VERSION "HNNBNNNYNNNNNNNNNNNNNNNNNNNNNNNNNNNNNNNNNN/4/%%%/4/'%**4NNN///"

NS_ :

BS_:

BU_: AEM BAP_Tester E_Sound FLA Gateway Gateway_PAG ISE MRR_HL MRR_HR NightVision RDK SAK SAK2 SCR STH_MLBevo TopView

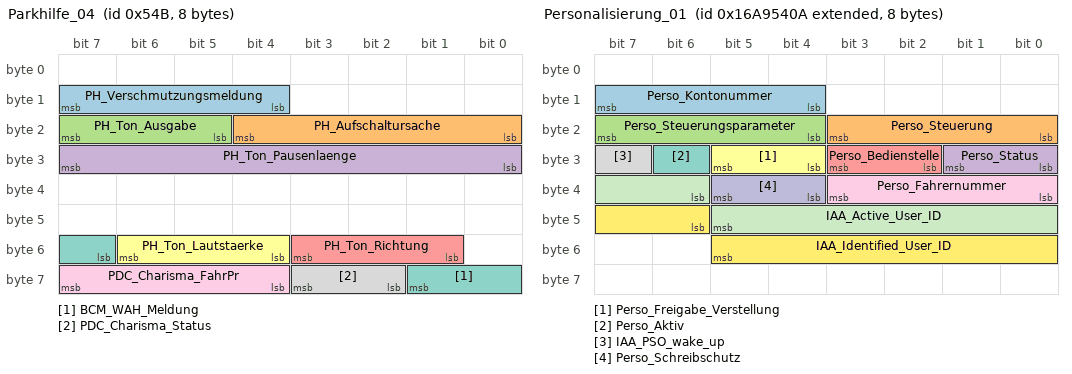
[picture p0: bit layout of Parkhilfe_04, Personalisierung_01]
BO_ 1355 Parkhilfe_04: 8 Gateway
 SG_ PH_Verschmutzungsmeldung : 12|4@1+ (1.0,0.0) [0.0|15] ""  Vector__XXX
 SG_ PH_Aufschaltursache : 16|5@1+ (1.0,0.0) [0.0|31] ""  TopView
 SG_ PH_Ton_Ausgabe : 21|3@1+ (1.0,0.0) [0.0|7] ""  Vector__XXX
 SG_ PH_Ton_Pausenlaenge : 24|8@1+ (1.0,0.0) [0.0|255] ""  Vector__XXX
 SG_ PH_Ton_Richtung : 49|3@1+ (1.0,0.0) [0.0|7] ""  Vector__XXX
 SG_ PH_Ton_Lautstaerke : 52|3@1+ (1.0,0.0) [0.0|7] ""  Vector__XXX
 SG_ BCM_WAH_Meldung : 55|3@1+ (1.0,0.0) [0.0|7] ""  Vector__XXX
 SG_ PDC_Charisma_Status : 58|2@1+ (1.0,0.0) [0.0|3] ""  Vector__XXX
 SG_ PDC_Charisma_FahrPr : 60|4@1+ (1.0,0.0) [0.0|15] ""  Vector__XXX

BO_ 2527679498 Personalisierung_01: 8 Gateway
 SG_ Perso_Kontonummer : 12|4@1+ (1.0,0.0) [0.0|15] ""  MRR_HR,NightVision
 SG_ Perso_Steuerung : 16|4@1+ (1.0,0.0) [0.0|15] ""  MRR_HR,NightVision
 SG_ Perso_Steuerungsparameter : 20|4@1+ (1.0,0.0) [0.0|15] ""  MRR_HR,NightVision
 SG_ Perso_Status : 24|2@1+ (1.0,0.0) [0.0|3] ""  MRR_HR,NightVision
 SG_ Perso_Bedienstelle : 26|2@1+ (1.0,0.0) [0.0|3] ""  Vector__XXX
 SG_ Perso_Freigabe_Verstellung : 28|2@1+ (1.0,0.0) [0.0|3] ""  Vector__XXX
 SG_ Perso_Aktiv : 30|1@1+ (1.0,0.0) [0.0|1] ""  Vector__XXX
 SG_ IAA_PSO_wake_up : 31|1@1+ (1.0,0.0) [0.0|1] ""  Vector__XXX
 SG_ Perso_Fahrernummer : 32|4@1+ (1.0,0.0) [0.0|15] ""  Vector__XXX
 SG_ Perso_Schreibschutz : 36|2@1+ (1.0,0.0) [0.0|3] ""  Vector__XXX
 SG_ IAA_Active_User_ID : 38|8@1+ (1,0) [0|255] "Unit_None"  Vector__XXX
 SG_ IAA_Identified_User_ID : 46|8@1+ (1,0) [0|255] "Unit_None"  Vector__XXX

BO_ 319 PreCrash_02: 8 Gateway
 SG_ PreCrash_02_CRC : 0|8@1+ (1,0) [0|255] ""  Vector__XXX
 SG_ PreCrash_02_BZ : 8|4@1+ (1,0) [0|15] ""  Vector__XXX
 SG_ PreCrash_Charisma_FahrPr : 12|4@1+ (1.0,0.0) [0.0|15] ""  Vector__XXX
 SG_ PreCrash_Charisma_Status : 16|2@1+ (1.0,0.0) [0.0|3] ""  Vector__XXX
 SG_ PreCrash_Schiebedach_schliessen : 18|1@1+ (1.0,0.0) [0.0|1] ""  Vector__XXX
 SG_ PreCrash_Fenster_schliessen : 19|1@1+ (1.0,0.0) [0.0|1] ""  Vector__XXX
 SG_ PreCrash_Blinken : 20|3@1+ (1.0,0.0) [0.0|7] ""  Vector__XXX
 SG_ SC_PreSense_FCWP : 23|1@1+ (1.0,0.0) [0.0|1] ""  NightVision
 SG_ PreCrash_Tueren_Verriegeln : 24|1@1+ (1.0,0.0) [0.0|1] ""  Vector__XXX
 SG_ PreCrash_Anforderung_AFR : 26|3@1+ (1.0,0.0) [0.0|7] ""  Vector__XXX
 SG_ SC_PreCrash_LED : 29|2@1+ (1.0,0.0) [0.0|3] ""  Vector__XXX
 SG_ PreCrash_FS_Pneumatik_ansteuern : 31|1@1+ (1.0,0.0) [0.0|1] ""  Vector__XXX
 SG_ PreCrash_BFS_Pneumatik_ansteuern : 32|1@1+ (1.0,0.0) [0.0|1] ""  Vector__XXX
 SG_ PreCrash_Fo_Pneumatik_ansteuern : 33|1@1+ (1.0,0.0) [0.0|1] ""  Vector__XXX
 SG_ PreCrash_FS_Sitzlehne_verfahren : 34|3@1+ (1.0,0.0) [0.0|7] ""  Vector__XXX
 SG_ PreCrash_BFS_Sitzlehne_verfahren : 37|3@1+ (1.0,0.0) [0.0|7] ""  Vector__XXX
 SG_ PreCrash_Fo_Sitzlehne_verfahren : 40|3@1+ (1.0,0.0) [0.0|7] ""  Vector__XXX
 SG_ PreCrash_FS_KSV_verfahren : 43|4@1+ (1.0,0.0) [0.0|15] ""  Vector__XXX
 SG_ PreCrash_BFS_KSV_verfahren : 47|4@1+ (1.0,0.0) [0.0|15] ""  Vector__XXX
 SG_ PreCrash_Fo_KSV_verfahren : 51|4@1+ (1.0,0.0) [0.0|15] ""  Vector__XXX
 SG_ SC_PreCrash_Warnung : 56|4@1+ (1.0,0.0) [0.0|15] ""  NightVision
 SG_ SC_PreCrash_Texte : 60|4@1+ (1.0,0.0) [0.0|15] ""  Vector__XXX

BO_ 1122 PSD_04: 8 Gateway
 SG_ PSD_Segment_ID : 0|6@1+ (1,0) [2|63] ""  FLA,NightVision
 SG_ PSD_Vorgaenger_Segment_ID : 6|6@1+ (1,0) [2|63] ""  FLA,NightVision
 SG_ PSD_Segmentlaenge : 12|7@1+ (2,0) [0|254] "Unit_Meter"  FLA,NightVision
 SG_ PSD_Strassenkategorie : 19|3@1+ (1.0,0.0) [0.0|7] ""  FLA,NightVision
 SG_ PSD_Endkruemmung : 22|8@1+ (1,0) [0|254] "Unit_None"  FLA,NightVision
 SG_ PSD_Endkruemmung_Vorz : 30|1@1+ (1.0,0.0) [0.0|1] ""  FLA,NightVision
 SG_ PSD_Idenditaets_ID : 31|6@1+ (1,0) [2|63] ""  FLA,NightVision
 SG_ PSD_ADAS_Qualitaet : 37|1@1+ (1.0,0.0) [0.0|1] ""  FLA,NightVision
 SG_ PSD_wahrscheinlichster_Pfad : 38|1@1+ (1.0,0.0) [0.0|1] ""  FLA,NightVision
 SG_ PSD_Geradester_Pfad : 39|1@1+ (1.0,0.0) [0.0|1] ""  FLA,NightVision
 SG_ PSD_Fahrspuren_Anzahl : 40|3@1+ (1.0,0.0) [0.0|7] ""  FLA,NightVision
 SG_ PSD_Bebauung : 43|1@1+ (1.0,0.0) [0.0|1] ""  FLA,NightVision
 SG_ PSD_Segment_Komplett : 44|1@1+ (1.0,0.0) [0.0|1] ""  FLA,NightVision
 SG_ PSD_Rampe : 45|2@1+ (1.0,0.0) [0.0|3] ""  FLA,NightVision
 SG_ PSD_Anfangskruemmung : 47|8@1+ (1,0) [0|254] ""  FLA,NightVision
 SG_ PSD_Anfangskruemmung_Vorz : 55|1@1+ (1.0,0.0) [0.0|1] ""  FLA,NightVision
 SG_ PSD_Abzweigerichtung : 56|1@1+ (1.0,0.0) [0.0|1] ""  FLA,NightVision
 SG_ PSD_Abzweigewinkel : 57|7@1+ (1.417323,0) [0.000000|180.000021] ""  FLA,NightVision

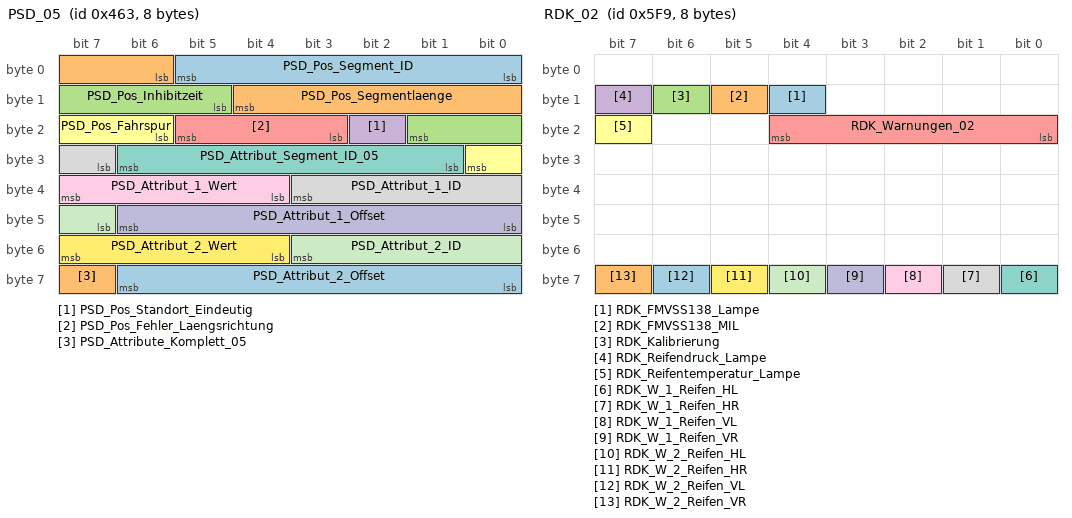
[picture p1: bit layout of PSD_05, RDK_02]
BO_ 1123 PSD_05: 8 Gateway
 SG_ PSD_Pos_Segment_ID : 0|6@1+ (1,0) [2|63] ""  FLA,NightVision
 SG_ PSD_Pos_Segmentlaenge : 6|7@1+ (2,0) [0|254] "Unit_Meter"  FLA,NightVision
 SG_ PSD_Pos_Inhibitzeit : 13|5@1+ (10,0) [0|310] "Unit_MilliSecon"  FLA,NightVision
 SG_ PSD_Pos_Standort_Eindeutig : 18|1@1+ (1.0,0.0) [0.0|1] ""  FLA,NightVision
 SG_ PSD_Pos_Fehler_Laengsrichtung : 19|3@1+ (1.0,0.0) [0.0|7] ""  FLA,NightVision
 SG_ PSD_Pos_Fahrspur : 22|3@1+ (1.0,0.0) [0.0|7] ""  FLA,NightVision
 SG_ PSD_Attribut_Segment_ID_05 : 25|6@1+ (1,0) [2|63] ""  FLA,NightVision
 SG_ PSD_Attribut_1_ID : 31|5@1+ (1,0) [1|31] ""  FLA,NightVision
 SG_ PSD_Attribut_1_Wert : 36|4@1+ (1.0,0.0) [0.0|15] ""  FLA,NightVision
 SG_ PSD_Attribut_1_Offset : 40|7@1+ (2,0) [0|254] "Unit_Meter"  FLA,NightVision
 SG_ PSD_Attribut_2_ID : 47|5@1+ (1,0) [1|31] ""  FLA,NightVision
 SG_ PSD_Attribut_2_Wert : 52|4@1+ (1.0,0.0) [0.0|15] ""  FLA,NightVision
 SG_ PSD_Attribut_2_Offset : 56|7@1+ (2,0) [0|254] "Unit_Meter"  FLA,NightVision
 SG_ PSD_Attribute_Komplett_05 : 63|1@1+ (1.0,0.0) [0.0|1] ""  FLA,NightVision

BO_ 1124 PSD_06: 8 Gateway
 SG_ PSD_06_Mux M  : 0|3@1+ (1.0,0.0) [0.0|7] ""  FLA,NightVision
 SG_ PSD_Sys_Segment_ID m0  : 3|6@1+ (1,0) [2|63] ""  FLA,NightVision
 SG_ PSD_Attribut_Segment_ID m1  : 3|6@1+ (1,0) [2|63] ""  FLA,NightVision
 SG_ PSD_Ges_Segment_ID m2  : 3|6@1+ (1,0) [2|63] ""  FLA,NightVision
 SG_ PSD_Baum_Laenge_VZ m3  : 3|1@1+ (1.0,0.0) [0.0|1] ""  FLA,NightVision
 SG_ PSD_Steigung_1_Segment_ID m4  : 3|6@1+ (1,0) [2|63] ""  FLA,NightVision
 SG_ PSD_Baum_Laenge m3  : 4|25@1+ (0.00001,0) [0.00000|180.00000] "Unit_DegreOfArc"  FLA,NightVision
 SG_ PSD_Sys_Laendercode m0  : 9|8@1+ (1.0,0.0) [0.0|255] ""  FLA,NightVision
 SG_ PSD_Attribut_3_ID m1  : 9|5@1+ (1,0) [1|31] ""  FLA,NightVision
 SG_ PSD_Ges_Offset m2  : 9|7@1+ (2,0) [0|254] "Unit_Meter"  FLA,NightVision
 SG_ PSD_Steigung_1_A_Steigung m4  : 9|7@1+ (0.12,0) [0.00|15.00] "Unit_PerCent"  FLA,NightVision
 SG_ PSD_Attribut_3_Offset m1  : 14|7@1+ (2,0) [0|254] "Unit_Meter"  FLA,NightVision
 SG_ PSD_Ges_Geschwindigkeit m2  : 16|5@1+ (1.0,0.0) [0.0|31] ""  FLA,NightVision
 SG_ PSD_Steigung_1_A_Vorz m4  : 16|1@1+ (1.0,0.0) [0.0|1] ""  FLA,NightVision
 SG_ PSD_Sys_Geschwindigkeit_Einheit m0  : 17|1@1+ (1.0,0.0) [0.0|1] ""  FLA,NightVision
 SG_ PSD_Steigung_1_A_Offset m4  : 17|7@1+ (2,0) [0|254] "Unit_Meter"  FLA,NightVision
 SG_ PSD_Sys_Verkehrsrichtung m0  : 18|1@1+ (1.0,0.0) [0.0|1] ""  FLA,NightVision
 SG_ PSD_Sys_Geometrieguete m0  : 19|2@1+ (1.0,0.0) [0.0|3] ""  FLA,NightVision
 SG_ PSD_Sys_Mapmatchingguete m0  : 21|2@1+ (1.0,0.0) [0.0|3] ""  FLA,NightVision
 SG_ PSD_Attribut_3_Wert m1  : 21|4@1+ (1.0,0.0) [0.0|15] ""  FLA,NightVision
 SG_ PSD_Ges_Typ m2  : 21|2@1+ (1.0,0.0) [0.0|3] ""  FLA,NightVision
 SG_ PSD_Sys_Alter_Karte m0  : 23|3@1+ (1.0,0.0) [0.0|7] ""  FLA,NightVision
 SG_ PSD_Ges_Spur_Geschw_Begrenzung m2  : 23|6@1+ (1.0,0.0) [0.0|63] ""  FLA,NightVision
 SG_ PSD_Steigung_1_B_Steigung m4  : 24|7@1+ (0.12,0) [0.00|15.00] "Unit_PerCent"  FLA,NightVision
 SG_ PSD_Attribut_4_ID m1  : 25|5@1+ (1,0) [1|31] ""  FLA,NightVision
 SG_ PSD_Sys_Zielfuehrung m0  : 26|1@1+ (1.0,0.0) [0.0|1] ""  FLA,NightVision
 SG_ PSD_Sys_US_State m0  : 27|6@1+ (1.0,0.0) [0.0|63] ""  FLA,NightVision
 SG_ PSD_Ges_Geschwindigkeit_Gespann m2  : 29|2@1+ (1.0,0.0) [0.0|3] ""  FLA,NightVision
 SG_ PSD_Baum_Breite_VZ m3  : 29|1@1+ (1.0,0.0) [0.0|1] ""  FLA,NightVision
 SG_ PSD_Attribut_4_Wert m1  : 30|4@1+ (1,0) [0|15] ""  FLA,NightVision
 SG_ PSD_Baum_Breite m3  : 30|24@1+ (0.00001,0) [0.00000|90.00000] "Unit_DegreOfArc"  FLA,NightVision
 SG_ PSD_Ges_Geschwindigkeit_Witter m2  : 31|2@1+ (1.0,0.0) [0.0|3] ""  FLA,NightVision
 SG_ PSD_Steigung_1_B_Vorz m4  : 31|1@1+ (1.0,0.0) [0.0|1] ""  FLA,NightVision
 SG_ PSD_Steigung_1_B_Offset m4  : 32|7@1+ (2,0) [0|254] "Unit_Meter"  FLA,NightVision
 SG_ PSD_Sys_Quali_Geometrien m0  : 33|3@1+ (1,0) [0|7] "Unit_None"  FLA,NightVision
 SG_ PSD_Ges_Geschwindigkeit_Tag_Anf m2  : 33|3@1+ (1.0,0.0) [0.0|7] ""  FLA,NightVision
 SG_ PSD_Attribut_4_Offset m1  : 34|7@1+ (2,0) [0|254] "Unit_Meter"  FLA,NightVision
 SG_ PSD_Sys_Quali_Ortsinfo m0  : 36|2@1+ (1,0) [0|3] "Unit_None"  FLA,NightVision
 SG_ PSD_Ges_Geschwindigkeit_Tag_Ende m2  : 36|3@1+ (1.0,0.0) [0.0|7] ""  FLA,NightVision
 SG_ PSD_Sys_Quali_verfuegbar m0  : 38|1@1+ (1.0,0.0) [0.0|1] ""  FLA,NightVision
 SG_ PSD_Sys_Zielfuehrung_geaendert m0  : 39|1@1+ (1.0,0.0) [0.0|1] ""  FLA,NightVision
 SG_ PSD_Ges_Geschwindigkeit_Std_Anf m2  : 39|5@1+ (1,0) [0|24] "Unit_Hours"  FLA,NightVision
 SG_ PSD_Steigung_1_Attribute_kompl m4  : 39|1@1+ (1.0,0.0) [0.0|1] ""  FLA,NightVision
 SG_ PSD_Sys_Geometrieguete_erweitert m0  : 40|8@1+ (1.0,0.0) [0.0|255] ""  FLA,NightVision
 SG_ PSD_Steigung_2_Segment_ID m4  : 40|6@1+ (1,0) [2|63] ""  FLA,NightVision
 SG_ PSD_Attribut_5_ID m1  : 41|5@1+ (1,0) [1|31] ""  FLA,NightVision
 SG_ PSD_Ges_Geschwindigkeit_Std_Ende m2  : 44|5@1+ (1,0) [0|24] "Unit_Hours"  FLA,NightVision
 SG_ PSD_Attribut_5_Offset m1  : 46|7@1+ (2,0) [0|254] "Unit_Meter"  FLA,NightVision
 SG_ PSD_Steigung_2_Steigung m4  : 46|7@1+ (0.12,0) [0.00|15.00] "Unit_PerCent"  FLA,NightVision
 SG_ PSD_Sys_Quali_sonstige_Attribute m0  : 48|3@1+ (1,0) [0|7] "Unit_None"  FLA,NightVision
 SG_ PSD_Ges_Ueberholverbot m2  : 49|2@1+ (1.0,0.0) [0.0|3] ""  FLA,NightVision
 SG_ PSD_Sys_Quali_Steigungen m0  : 51|3@1+ (1,0) [0|7] ""  FLA,NightVision
 SG_ PSD_Ges_Wechselverkehrszeichen m2  : 51|3@1+ (1.0,0.0) [0.0|7] ""  FLA,NightVision
 SG_ PSD_Attribut_5_Wert m1  : 53|4@1+ (1,0) [0|15] ""  FLA,NightVision
 SG_ PSD_Steigung_2_Vorz m4  : 53|1@1+ (1.0,0.0) [0.0|1] ""  FLA,NightVision
 SG_ PSD_Sys_Quali_Strassenkennz m0  : 54|3@1+ (1,0) [0|7] "Unit_None"  FLA,NightVision
 SG_ PSD_Wechselverkehrszeichen_Typ m2  : 54|2@1+ (1.0,0.0) [0.0|3] ""  FLA,NightVision
 SG_ PSD_Baum_Ausrichtung m3  : 54|10@1+ (0.3515625,0) [0E-7|359.6484375] "Unit_DegreOfArc"  FLA,NightVision
 SG_ PSD_Steigung_2_Offset m4  : 54|7@1+ (2,0) [0|254] "Unit_Meter"  FLA,NightVision
 SG_ PSD_Ges_Gesetzlich_Kategorie m2  : 56|3@1+ (1.0,0.0) [0.0|7] ""  FLA,NightVision
 SG_ PSD_Sys_Quali_Tempolimits m0  : 57|3@1+ (1,0) [0|7] "Unit_None"  FLA,NightVision
 SG_ PSD_Attribute_Komplett_06 m1  : 57|1@1+ (1.0,0.0) [0.0|1] ""  FLA,NightVision
 SG_ PSD_Ges_Gesetzlich_Zusatz m2  : 59|2@1+ (1.0,0.0) [0.0|3] ""  FLA,NightVision
 SG_ PSD_Sys_Quali_Vorfahrtsregelung m0  : 60|3@1+ (1,0) [0|7] "Unit_None"  FLA,NightVision
 SG_ PSD_Ges_Verkehrszeichen_Quelle m2  : 61|2@1+ (1.0,0.0) [0.0|3] ""  FLA,NightVision
 SG_ PSD_Steigung_2_Attribute_kompl m4  : 61|1@1+ (1.0,0.0) [0.0|1] ""  FLA,NightVision
 SG_ PSD_Ges_Attribute_Komplett m2  : 63|1@1+ (1.0,0.0) [0.0|1] ""  FLA,NightVision

BO_ 1529 RDK_02: 8 RDK
 SG_ RDK_FMVSS138_Lampe : 12|1@1+ (1.0,0.0) [0.0|1] ""  Gateway,Gateway_PAG
 SG_ RDK_FMVSS138_MIL : 13|1@1+ (1.0,0.0) [0.0|1] ""  Gateway,Gateway_PAG
 SG_ RDK_Kalibrierung : 14|1@1+ (1.0,0.0) [0.0|1] ""  Gateway,Gateway_PAG
 SG_ RDK_Reifendruck_Lampe : 15|1@1+ (1.0,0.0) [0.0|1] ""  Gateway,Gateway_PAG
 SG_ RDK_Warnungen_02 : 16|5@1+ (1.0,0.0) [0.0|31] ""  Gateway,Gateway_PAG
 SG_ RDK_Reifentemperatur_Lampe : 23|1@1+ (1.0,0.0) [0.0|1] ""  Gateway,Gateway_PAG
 SG_ RDK_W_1_Reifen_HL : 56|1@1+ (1.0,0.0) [0.0|1] ""  Gateway,Gateway_PAG
 SG_ RDK_W_1_Reifen_HR : 57|1@1+ (1.0,0.0) [0.0|1] ""  Gateway,Gateway_PAG
 SG_ RDK_W_1_Reifen_VL : 58|1@1+ (1.0,0.0) [0.0|1] ""  Gateway,Gateway_PAG
 SG_ RDK_W_1_Reifen_VR : 59|1@1+ (1.0,0.0) [0.0|1] ""  Gateway,Gateway_PAG
 SG_ RDK_W_2_Reifen_HL : 60|1@1+ (1.0,0.0) [0.0|1] ""  Gateway,Gateway_PAG
 SG_ RDK_W_2_Reifen_HR : 61|1@1+ (1.0,0.0) [0.0|1] ""  Gateway,Gateway_PAG
 SG_ RDK_W_2_Reifen_VL : 62|1@1+ (1.0,0.0) [0.0|1] ""  Gateway,Gateway_PAG
 SG_ RDK_W_2_Reifen_VR : 63|1@1+ (1.0,0.0) [0.0|1] ""  Gateway,Gateway_PAG

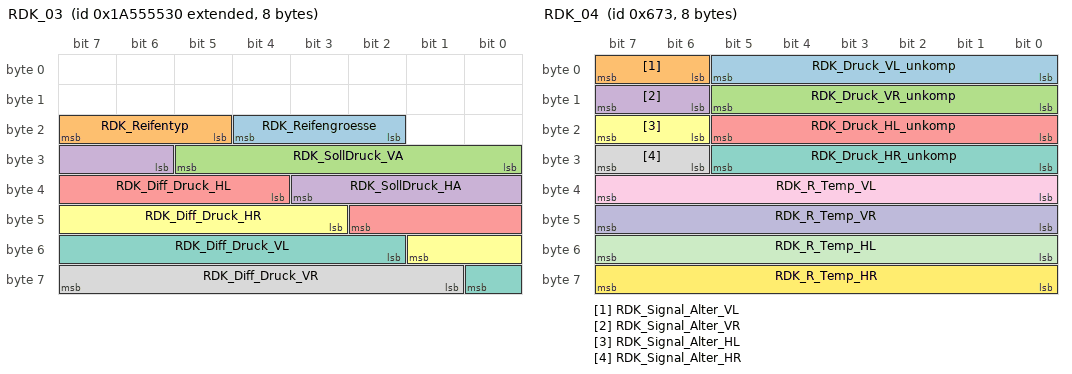
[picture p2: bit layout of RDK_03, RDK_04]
BO_ 2589283632 RDK_03: 8 RDK
 SG_ RDK_Reifengroesse : 18|3@1+ (1.0,0.0) [0.0|7] ""  Gateway,Gateway_PAG
 SG_ RDK_Reifentyp : 21|3@1+ (1.0,0.0) [0.0|7] ""  Gateway,Gateway_PAG
 SG_ RDK_SollDruck_VA : 24|6@1+ (0.1,0) [0.0|6.2] "Unit_Bar"  Gateway,Gateway_PAG
 SG_ RDK_SollDruck_HA : 30|6@1+ (0.1,0) [0.0|6.2] "Unit_Bar"  Gateway,Gateway_PAG
 SG_ RDK_Diff_Druck_HL : 36|7@1+ (0.1,-6.3) [-6.3|6.3] "Unit_Bar"  Gateway,Gateway_PAG
 SG_ RDK_Diff_Druck_HR : 43|7@1+ (0.1,-6.3) [-6.3|6.3] "Unit_Bar"  Gateway,Gateway_PAG
 SG_ RDK_Diff_Druck_VL : 50|7@1+ (0.1,-6.3) [-6.3|6.3] "Unit_Bar"  Gateway,Gateway_PAG
 SG_ RDK_Diff_Druck_VR : 57|7@1+ (0.1,-6.3) [-6.3|6.3] "Unit_Bar"  Gateway,Gateway_PAG

BO_ 1651 RDK_04: 8 RDK
 SG_ RDK_Druck_VL_unkomp : 0|6@1+ (0.1,0) [0.0|6.2] "Unit_Bar"  Gateway,Gateway_PAG
 SG_ RDK_Signal_Alter_VL : 6|2@1+ (1.0,0.0) [0.0|3] ""  Gateway,Gateway_PAG
 SG_ RDK_Druck_VR_unkomp : 8|6@1+ (0.1,0) [0.0|6.2] "Unit_Bar"  Gateway,Gateway_PAG
 SG_ RDK_Signal_Alter_VR : 14|2@1+ (1.0,0.0) [0.0|3] ""  Gateway,Gateway_PAG
 SG_ RDK_Druck_HL_unkomp : 16|6@1+ (0.1,0) [0.0|6.2] "Unit_Bar"  Gateway,Gateway_PAG
 SG_ RDK_Signal_Alter_HL : 22|2@1+ (1.0,0.0) [0.0|3] ""  Gateway,Gateway_PAG
 SG_ RDK_Druck_HR_unkomp : 24|6@1+ (0.1,0) [0.0|6.2] "Unit_Bar"  Gateway,Gateway_PAG
 SG_ RDK_Signal_Alter_HR : 30|2@1+ (1.0,0.0) [0.0|3] ""  Gateway,Gateway_PAG
 SG_ RDK_R_Temp_VL : 32|8@1+ (1,-60) [-60|193] "Unit_DegreCelsi"  Gateway,Gateway_PAG
 SG_ RDK_R_Temp_VR : 40|8@1+ (1,-60) [-60|193] "Unit_DegreCelsi"  Gateway,Gateway_PAG
 SG_ RDK_R_Temp_HL : 48|8@1+ (1,-60) [-60|193] "Unit_DegreCelsi"  Gateway,Gateway_PAG
 SG_ RDK_R_Temp_HR : 56|8@1+ (1,-60) [-60|193] "Unit_DegreCelsi"  Gateway,Gateway_PAG

BO_ 1711 Rear_View_01: 8 TopView
 SG_ RV_Video_on : 0|1@1+ (1.0,0.0) [0.0|1] ""  Gateway,Gateway_PAG
 SG_ RV_Dark_Screen : 1|1@1+ (1.0,0.0) [0.0|1] ""  Gateway,Gateway_PAG
 SG_ RV_HMI_Mode : 2|2@1+ (1.0,0.0) [0.0|3] ""  Gateway,Gateway_PAG
 SG_ RV_GL_side : 4|2@1+ (1.0,0.0) [0.0|3] ""  Gateway,Gateway_PAG
 SG_ RV_System_aktiv : 6|1@1+ (1.0,0.0) [0.0|1] ""  Gateway,Gateway_PAG
 SG_ RV_Reinigung_Anf : 7|1@1+ (1.0,0.0) [0.0|1] ""  Gateway,Gateway_PAG
 SG_ RV_Settings_enabled : 8|1@1+ (1.0,0.0) [0.0|1] ""  Gateway,Gateway_PAG
 SG_ RV_Menu_Item : 9|2@1+ (1.0,0.0) [0.0|3] ""  Gateway,Gateway_PAG
 SG_ SV_Video_on : 11|1@1+ (1.0,0.0) [0.0|1] ""  Gateway,Gateway_PAG
 SG_ RV_Calib_Fehler : 12|1@1+ (1.0,0.0) [0.0|1] ""  Gateway,Gateway_PAG
 SG_ RV_GL_Trailer_connect : 13|1@1+ (1.0,0.0) [0.0|1] ""  Gateway,Gateway_PAG
 SG_ RV_GL_Trunk_open : 14|1@1+ (1.0,0.0) [0.0|1] ""  Gateway,Gateway_PAG
 SG_ RV_GL_LWS_Fehler : 15|1@1+ (1.0,0.0) [0.0|1] ""  Gateway,Gateway_PAG
 SG_ RV_Helligkeit : 16|7@1+ (1,0) [0|100] "Unit_PerCent"  Gateway,Gateway_PAG
 SG_ ZFAS_Umfeldbeleuchtung_Anf : 23|1@1+ (1.0,0.0) [0.0|1] ""  Gateway,Gateway_PAG
 SG_ RV_Kontrast : 24|7@1+ (1,0) [0|100] "Unit_PerCent"  Gateway,Gateway_PAG
 SG_ RV_Farbe : 32|7@1+ (1,0) [0|100] "Unit_PerCent"  Gateway,Gateway_PAG

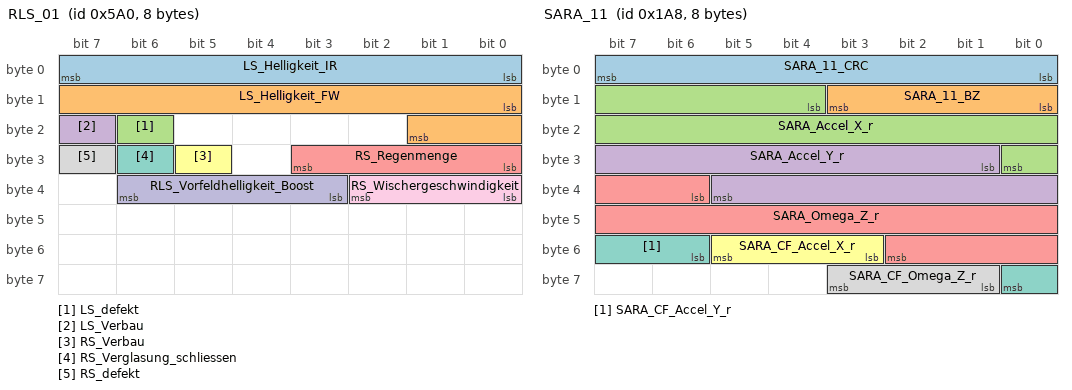
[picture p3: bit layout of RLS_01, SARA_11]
BO_ 1440 RLS_01: 8 Gateway
 SG_ LS_Helligkeit_IR : 0|8@1+ (400,0) [0|101200] "Unit_Lux"  MRR_HL,MRR_HR,NightVision
 SG_ LS_Helligkeit_FW : 8|10@1+ (6,0) [0|6126] "Unit_Lux"  MRR_HL,MRR_HR,NightVision
 SG_ LS_defekt : 22|1@1+ (1.0,0.0) [0.0|1] ""  MRR_HL,MRR_HR,NightVision
 SG_ LS_Verbau : 23|1@1+ (1.0,0.0) [0.0|1] ""  MRR_HL,MRR_HR,NightVision
 SG_ RS_Regenmenge : 24|4@1+ (10,0) [0|100] "Unit_PerCent"  Vector__XXX
 SG_ RS_Verbau : 29|1@1+ (1.0,0.0) [0.0|1] ""  NightVision
 SG_ RS_Verglasung_schliessen : 30|1@1+ (1.0,0.0) [0.0|1] ""  Vector__XXX
 SG_ RS_defekt : 31|1@1+ (1.0,0.0) [0.0|1] ""  NightVision
 SG_ RS_Wischergeschwindigkeit : 32|3@1+ (1.0,0.0) [0.0|7] ""  NightVision
 SG_ RLS_Vorfeldhelligkeit_Boost : 35|4@1+ (1.0,0.0) [0.0|15] ""  Vector__XXX

BO_ 1528 SAK_01: 8 ISE
 SG_ SAK_Charisma_FahrPr : 16|4@1+ (1.0,0.0) [0.0|15] ""  Gateway,Gateway_PAG
 SG_ SAK_Charisma_Status : 20|2@1+ (1.0,0.0) [0.0|3] ""  Gateway,Gateway_PAG

BO_ 424 SARA_11: 8 Gateway
 SG_ SARA_11_CRC : 0|8@1+ (1,0) [0|255] ""  Vector__XXX
 SG_ SARA_11_BZ : 8|4@1+ (1,0) [0|15] ""  Vector__XXX
 SG_ SARA_Accel_X_r : 12|13@1+ (0.16,-655.36) [-655.20|655.04] "Unit_MeterPerSeconSquar"  E_Sound,ISE,TopView
 SG_ SARA_Accel_Y_r : 25|13@1+ (0.16,-655.36) [-655.20|655.04] "Unit_MeterPerSeconSquar"  TopView
 SG_ SARA_Omega_Z_r : 38|13@1+ (0.08,-327.68) [-327.60|327.52] "Unit_DegreOfArcPerSecon"  FLA,NightVision,TopView
 SG_ SARA_CF_Accel_X_r : 51|3@1+ (1.0,0.0) [0.0|7] ""  TopView
 SG_ SARA_CF_Accel_Y_r : 54|3@1+ (1.0,0.0) [0.0|7] ""  TopView
 SG_ SARA_CF_Omega_Z_r : 57|3@1+ (1.0,0.0) [0.0|7] ""  FLA,NightVision,TopView

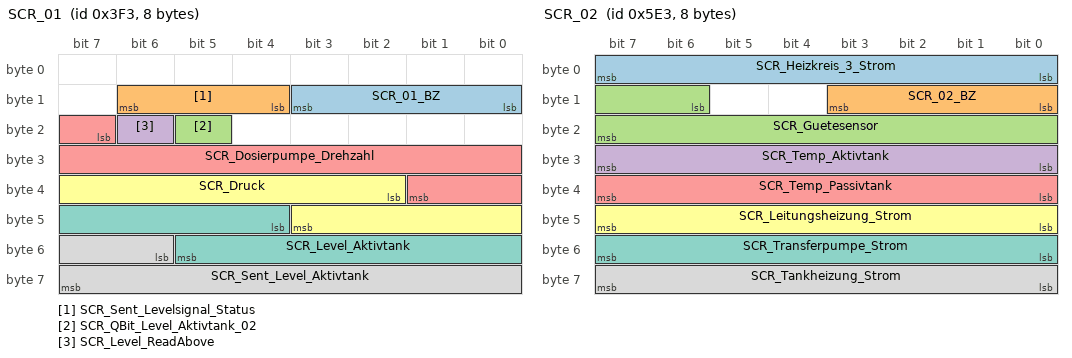
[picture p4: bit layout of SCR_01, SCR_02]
BO_ 1011 SCR_01: 8 SCR
 SG_ SCR_01_BZ : 8|4@1+ (1,0) [0|15] ""  Gateway,Gateway_PAG
 SG_ SCR_Sent_Levelsignal_Status : 12|3@1+ (1.0,0.0) [0.0|7] ""  Gateway,Gateway_PAG
 SG_ SCR_QBit_Level_Aktivtank_02 : 21|1@1+ (1.0,0.0) [0.0|1] ""  Gateway,Gateway_PAG
 SG_ SCR_Level_ReadAbove : 22|1@1+ (1.0,0.0) [0.0|1] ""  Gateway,Gateway_PAG
 SG_ SCR_Dosierpumpe_Drehzahl : 23|11@1+ (4,-4080) [-4080|4100] "Unit_MinutInver"  Gateway,Gateway_PAG
 SG_ SCR_Druck : 34|10@1+ (5,0) [0|5000] "Unit_MilliVolt"  Gateway,Gateway_PAG
 SG_ SCR_Level_Aktivtank : 44|10@1+ (5,0) [0|5000] "Unit_MilliVolt"  Gateway,Gateway_PAG
 SG_ SCR_Sent_Level_Aktivtank : 54|10@1+ (1,-20) [-20|1000] "Unit_MilliMeter"  Gateway,Gateway_PAG

BO_ 1507 SCR_02: 8 SCR
 SG_ SCR_Heizkreis_3_Strom : 0|8@1+ (0.1,0) [0.0|14.0] "Unit_Amper"  Gateway,Gateway_PAG
 SG_ SCR_02_BZ : 8|4@1+ (1,0) [0|15] ""  Gateway,Gateway_PAG
 SG_ SCR_Guetesensor : 14|10@1+ (5,0) [0|5000] "Unit_MilliVolt"  Gateway,Gateway_PAG
 SG_ SCR_Temp_Aktivtank : 24|8@1+ (20,0) [0|5000] "Unit_MilliVolt"  Gateway,Gateway_PAG
 SG_ SCR_Temp_Passivtank : 32|8@1+ (20,0) [0|5000] "Unit_MilliVolt"  Gateway,Gateway_PAG
 SG_ SCR_Leitungsheizung_Strom : 40|8@1+ (0.1,0) [0.0|14.0] "Unit_Amper"  Gateway,Gateway_PAG
 SG_ SCR_Transferpumpe_Strom : 48|8@1+ (0.1,0) [0.0|14.0] "Unit_Amper"  Gateway,Gateway_PAG
 SG_ SCR_Tankheizung_Strom : 56|8@1+ (0.1,0) [0.0|14.0] "Unit_Amper"  Gateway,Gateway_PAG

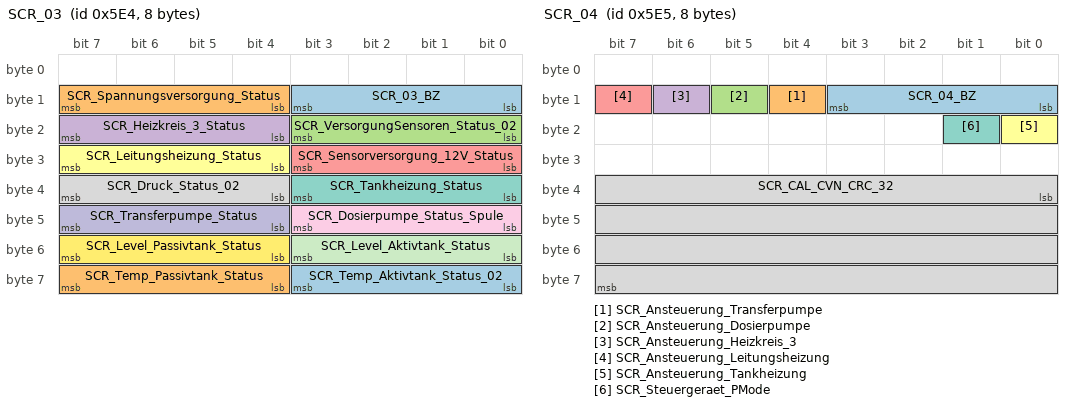
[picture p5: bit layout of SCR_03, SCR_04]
BO_ 1508 SCR_03: 8 SCR
 SG_ SCR_03_BZ : 8|4@1+ (1,0) [0|15] ""  Gateway,Gateway_PAG
 SG_ SCR_Spannungsversorgung_Status : 12|4@1+ (1.0,0.0) [0.0|15] ""  Gateway,Gateway_PAG
 SG_ SCR_VersorgungSensoren_Status_02 : 16|4@1+ (1.0,0.0) [0.0|15] ""  Gateway,Gateway_PAG
 SG_ SCR_Heizkreis_3_Status : 20|4@1+ (1.0,0.0) [0.0|15] ""  Gateway,Gateway_PAG
 SG_ SCR_Sensorversorgung_12V_Status : 24|4@1+ (1.0,0.0) [0.0|15] ""  Gateway,Gateway_PAG
 SG_ SCR_Leitungsheizung_Status : 28|4@1+ (1.0,0.0) [0.0|15] ""  Gateway,Gateway_PAG
 SG_ SCR_Tankheizung_Status : 32|4@1+ (1.0,0.0) [0.0|15] ""  Gateway,Gateway_PAG
 SG_ SCR_Druck_Status_02 : 36|4@1+ (1.0,0.0) [0.0|15] ""  Gateway,Gateway_PAG
 SG_ SCR_Dosierpumpe_Status_Spule : 40|4@1+ (1.0,0.0) [0.0|15] ""  Gateway,Gateway_PAG
 SG_ SCR_Transferpumpe_Status : 44|4@1+ (1.0,0.0) [0.0|15] ""  Gateway,Gateway_PAG
 SG_ SCR_Level_Aktivtank_Status : 48|4@1+ (1.0,0.0) [0.0|15] ""  Gateway,Gateway_PAG
 SG_ SCR_Level_Passivtank_Status : 52|4@1+ (1.0,0.0) [0.0|15] ""  Gateway,Gateway_PAG
 SG_ SCR_Temp_Aktivtank_Status_02 : 56|4@1+ (1.0,0.0) [0.0|15] ""  Gateway,Gateway_PAG
 SG_ SCR_Temp_Passivtank_Status : 60|4@1+ (1.0,0.0) [0.0|15] ""  Gateway,Gateway_PAG

BO_ 1509 SCR_04: 8 SCR
 SG_ SCR_04_BZ : 8|4@1+ (1,0) [0|15] ""  Gateway,Gateway_PAG
 SG_ SCR_Ansteuerung_Transferpumpe : 12|1@1+ (1.0,0.0) [0.0|1] ""  Gateway,Gateway_PAG
 SG_ SCR_Ansteuerung_Dosierpumpe : 13|1@1+ (1.0,0.0) [0.0|1] ""  Gateway,Gateway_PAG
 SG_ SCR_Ansteuerung_Heizkreis_3 : 14|1@1+ (1.0,0.0) [0.0|1] ""  Gateway,Gateway_PAG
 SG_ SCR_Ansteuerung_Leitungsheizung : 15|1@1+ (1.0,0.0) [0.0|1] ""  Gateway,Gateway_PAG
 SG_ SCR_Ansteuerung_Tankheizung : 16|1@1+ (1.0,0.0) [0.0|1] ""  Gateway,Gateway_PAG
 SG_ SCR_Steuergeraet_PMode : 17|1@1+ (1.0,0.0) [0.0|1] ""  Gateway,Gateway_PAG
 SG_ SCR_CAL_CVN_CRC_32 : 32|32@1+ (1.0,0.0) [0.0|4294967295] ""  Gateway,Gateway_PAG

BO_ 1526 SCR_05: 8 SCR
 SG_ SCR_05_BZ : 8|4@1+ (1,0) [0|15] ""  Gateway,Gateway_PAG
 SG_ SCR_Level_Aktivtank_OOR4Quality : 12|1@1+ (1.0,0.0) [0.0|1] ""  Gateway,Gateway_PAG
 SG_ SCR_Level_Aktivtank_OOR_minus : 13|1@1+ (1.0,0.0) [0.0|1] ""  Gateway,Gateway_PAG
 SG_ SCR_Sent_1_Signalstatus : 14|2@1+ (1.0,0.0) [0.0|3] ""  Gateway,Gateway_PAG
 SG_ SCR_Sent_1_elektrischer_Status : 16|4@1+ (1.0,0.0) [0.0|15] ""  Gateway,Gateway_PAG
 SG_ SCR_Sent_Levelsensor : 20|3@1+ (1.0,0.0) [0.0|7] ""  Gateway,Gateway_PAG
 SG_ SCR_Sent_Qualitaetssensor : 23|3@1+ (1.0,0.0) [0.0|7] ""  Gateway,Gateway_PAG
 SG_ SCR_Sent_Temperatursensor : 26|3@1+ (1.0,0.0) [0.0|7] ""  Gateway,Gateway_PAG
 SG_ SCR_DEF_Qualitaet_Medium : 29|1@1+ (1.0,0.0) [0.0|1] ""  Gateway,Gateway_PAG
 SG_ SCR_QBit_Qualitaet : 30|1@1+ (1.0,0.0) [0.0|1] ""  Gateway,Gateway_PAG
 SG_ SCR_Sent_2_Signalstatus : 31|2@1+ (1.0,0.0) [0.0|3] ""  Gateway,Gateway_PAG
 SG_ SCR_Temp_DEF2_Sensor_Status : 33|3@1+ (1.0,0.0) [0.0|7] ""  Gateway,Gateway_PAG
 SG_ SCR_Sent_2_elektrischer_Status : 36|4@1+ (1.0,0.0) [0.0|15] ""  Gateway,Gateway_PAG
 SG_ SCR_HAL_Sensorik_Status : 40|4@1+ (1.0,0.0) [0.0|15] ""  Gateway,Gateway_PAG
 SG_ SCR_Steuergeraet_Heizung_Status : 48|2@1+ (1.0,0.0) [0.0|3] ""  Gateway,Gateway_PAG
 SG_ SCR_Steuergeraet_Pumpe_Status : 50|2@1+ (1.0,0.0) [0.0|3] ""  Gateway,Gateway_PAG
 SG_ SCR_Steuergeraet_Relais_Status : 52|2@1+ (1.0,0.0) [0.0|3] ""  Gateway,Gateway_PAG
 SG_ SCR_Steuergeraet_Bus_Status : 56|2@1+ (1.0,0.0) [0.0|3] ""  Gateway,Gateway_PAG
 SG_ SCR_ECU_Datensatz_Status : 60|2@1+ (1.0,0.0) [0.0|3] ""  Gateway,Gateway_PAG
 SG_ SCR_Steuergeraet_Defekt_Status : 62|2@1+ (1.0,0.0) [0.0|3] ""  Gateway,Gateway_PAG

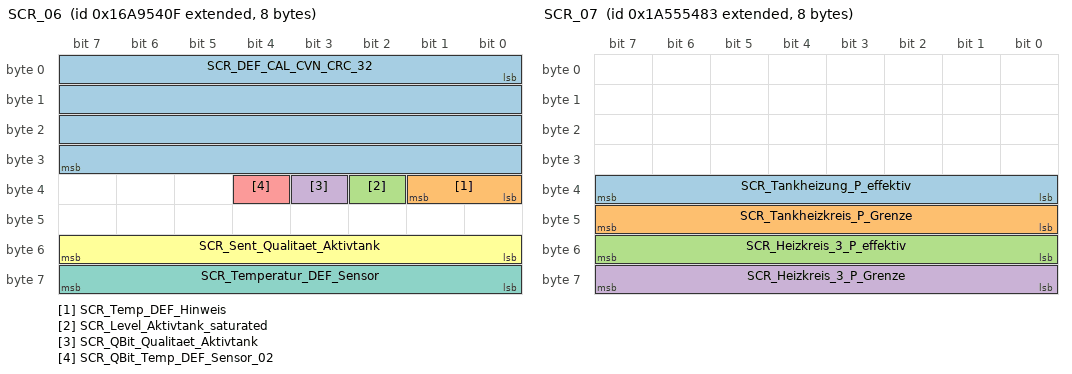
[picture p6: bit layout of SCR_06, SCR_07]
BO_ 2527679503 SCR_06: 8 SCR
 SG_ SCR_DEF_CAL_CVN_CRC_32 : 0|32@1+ (1.0,0.0) [0.0|4294967295] ""  Gateway,Gateway_PAG
 SG_ SCR_Temp_DEF_Hinweis : 32|2@1+ (1.0,0.0) [0.0|3] ""  Gateway,Gateway_PAG
 SG_ SCR_Level_Aktivtank_saturated : 34|1@1+ (1.0,0.0) [0.0|1] ""  Gateway,Gateway_PAG
 SG_ SCR_QBit_Qualitaet_Aktivtank : 35|1@1+ (1.0,0.0) [0.0|1] ""  Gateway,Gateway_PAG
 SG_ SCR_QBit_Temp_DEF_Sensor_02 : 36|1@1+ (1.0,0.0) [0.0|1] ""  Gateway,Gateway_PAG
 SG_ SCR_Sent_Qualitaet_Aktivtank : 48|8@1+ (0.5,-20) [-20.0|100.0] "Unit_PerCent"  Gateway,Gateway_PAG
 SG_ SCR_Temperatur_DEF_Sensor : 56|8@1+ (0.5,-45) [-45.0|80.0] "Unit_DegreCelsi"  Gateway,Gateway_PAG

BO_ 2589283459 SCR_07: 8 SCR
 SG_ SCR_Tankheizung_P_effektiv : 32|8@1+ (1,0) [0|250] "Unit_Watt"  Gateway,Gateway_PAG
 SG_ SCR_Tankheizkreis_P_Grenze : 40|8@1+ (1,0) [0|250] "Unit_Watt"  Gateway,Gateway_PAG
 SG_ SCR_Heizkreis_3_P_effektiv : 48|8@1+ (1,0) [0|250] "Unit_Watt"  Gateway,Gateway_PAG
 SG_ SCR_Heizkreis_3_P_Grenze : 56|8@1+ (1,0) [0|250] "Unit_Watt"  Gateway,Gateway_PAG

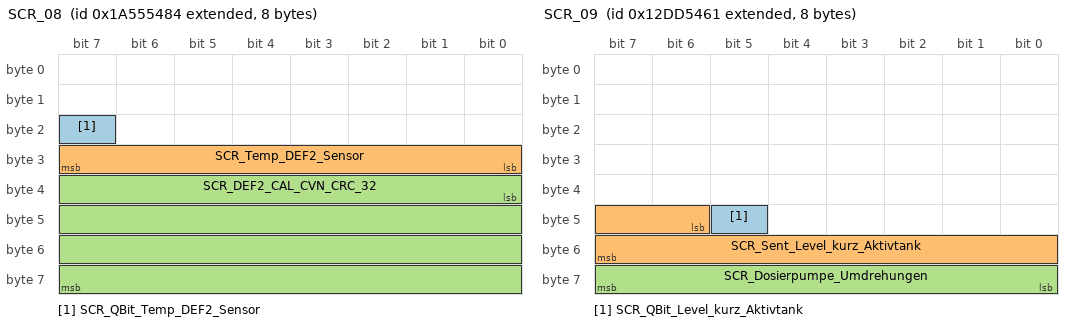
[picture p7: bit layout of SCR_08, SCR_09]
BO_ 2589283460 SCR_08: 8 SCR
 SG_ SCR_QBit_Temp_DEF2_Sensor : 23|1@1+ (1.0,0.0) [0.0|1] ""  Gateway,Gateway_PAG
 SG_ SCR_Temp_DEF2_Sensor : 24|8@1+ (0.5,-45) [-45.0|80.0] "Unit_DegreCelsi"  Gateway,Gateway_PAG
 SG_ SCR_DEF2_CAL_CVN_CRC_32 : 32|32@1+ (1.0,0.0) [0.0|4294967295] ""  Gateway,Gateway_PAG

BO_ 2463978593 SCR_09: 8 SCR
 SG_ SCR_QBit_Level_kurz_Aktivtank : 45|1@1+ (1.0,0.0) [0.0|1] ""  Gateway,Gateway_PAG
 SG_ SCR_Sent_Level_kurz_Aktivtank : 46|10@1+ (1,-20) [-20|1000] "Unit_MilliMeter"  Gateway,Gateway_PAG
 SG_ SCR_Dosierpumpe_Umdrehungen : 56|8@1+ (1,0) [0|253] "Unit_Rev"  Gateway,Gateway_PAG

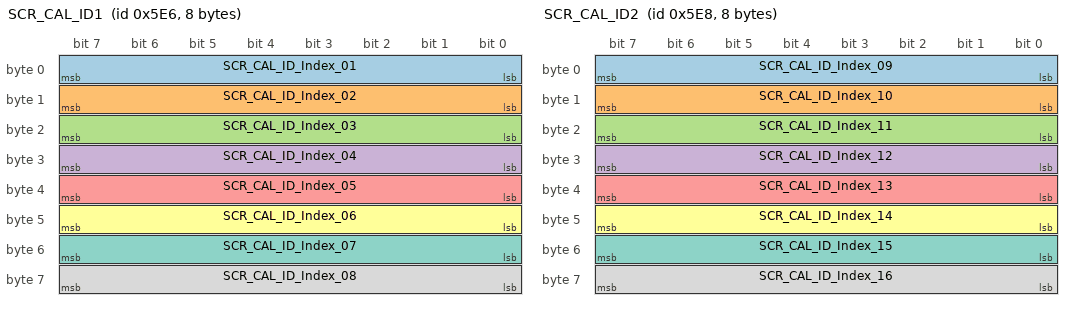
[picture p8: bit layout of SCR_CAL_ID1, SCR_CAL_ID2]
BO_ 1510 SCR_CAL_ID1: 8 SCR
 SG_ SCR_CAL_ID_Index_01 : 0|8@1+ (1.0,0.0) [0.0|255] ""  Gateway,Gateway_PAG
 SG_ SCR_CAL_ID_Index_02 : 8|8@1+ (1.0,0.0) [0.0|255] ""  Gateway,Gateway_PAG
 SG_ SCR_CAL_ID_Index_03 : 16|8@1+ (1.0,0.0) [0.0|255] ""  Gateway,Gateway_PAG
 SG_ SCR_CAL_ID_Index_04 : 24|8@1+ (1.0,0.0) [0.0|255] ""  Gateway,Gateway_PAG
 SG_ SCR_CAL_ID_Index_05 : 32|8@1+ (1.0,0.0) [0.0|255] ""  Gateway,Gateway_PAG
 SG_ SCR_CAL_ID_Index_06 : 40|8@1+ (1.0,0.0) [0.0|255] ""  Gateway,Gateway_PAG
 SG_ SCR_CAL_ID_Index_07 : 48|8@1+ (1.0,0.0) [0.0|255] ""  Gateway,Gateway_PAG
 SG_ SCR_CAL_ID_Index_08 : 56|8@1+ (1.0,0.0) [0.0|255] ""  Gateway,Gateway_PAG

BO_ 1512 SCR_CAL_ID2: 8 SCR
 SG_ SCR_CAL_ID_Index_09 : 0|8@1+ (1.0,0.0) [0.0|255] ""  Gateway,Gateway_PAG
 SG_ SCR_CAL_ID_Index_10 : 8|8@1+ (1.0,0.0) [0.0|255] ""  Gateway,Gateway_PAG
 SG_ SCR_CAL_ID_Index_11 : 16|8@1+ (1.0,0.0) [0.0|255] ""  Gateway,Gateway_PAG
 SG_ SCR_CAL_ID_Index_12 : 24|8@1+ (1.0,0.0) [0.0|255] ""  Gateway,Gateway_PAG
 SG_ SCR_CAL_ID_Index_13 : 32|8@1+ (1.0,0.0) [0.0|255] ""  Gateway,Gateway_PAG
 SG_ SCR_CAL_ID_Index_14 : 40|8@1+ (1.0,0.0) [0.0|255] ""  Gateway,Gateway_PAG
 SG_ SCR_CAL_ID_Index_15 : 48|8@1+ (1.0,0.0) [0.0|255] ""  Gateway,Gateway_PAG
 SG_ SCR_CAL_ID_Index_16 : 56|8@1+ (1.0,0.0) [0.0|255] ""  Gateway,Gateway_PAG

BO_ 2589283497 SCR_DEF2_CAL_ID1: 8 SCR
 SG_ SCR_DEF2_CAL_ID_Index01 : 0|32@1+ (1.0,0.0) [0.0|4294967295] ""  Gateway,Gateway_PAG
 SG_ SCR_DEF2_CAL_ID_Index02 : 32|32@1+ (1.0,0.0) [0.0|4294967295] ""  Gateway,Gateway_PAG

BO_ 2589283498 SCR_DEF2_CAL_ID2: 8 SCR
 SG_ SCR_DEF2_CAL_ID_Index03 : 0|32@1+ (1.0,0.0) [0.0|4294967295] ""  Gateway,Gateway_PAG
 SG_ SCR_DEF2_CAL_ID_Index04 : 32|32@1+ (1.0,0.0) [0.0|4294967295] ""  Gateway,Gateway_PAG

BO_ 2589283413 SCR_DEF_CAL_ID1: 8 SCR
 SG_ SCR_DEF_CAL_ID_Index01 : 0|32@1+ (1.0,0.0) [0.0|4294967295] ""  Gateway,Gateway_PAG
 SG_ SCR_DEF_CAL_ID_Index02 : 32|32@1+ (1.0,0.0) [0.0|4294967295] ""  Gateway,Gateway_PAG

BO_ 2589283414 SCR_DEF_CAL_ID2: 8 SCR
 SG_ SCR_DEF_CAL_ID_Index03 : 0|32@1+ (1.0,0.0) [0.0|4294967295] ""  Gateway,Gateway_PAG
 SG_ SCR_DEF_CAL_ID_Index04 : 32|32@1+ (1.0,0.0) [0.0|4294967295] ""  Gateway,Gateway_PAG

BO_ 980 SMLS_01: 8 Gateway
 SG_ SMLS_01_CRC : 0|8@1+ (1,0) [0|255] ""  Vector__XXX
 SG_ SMLS_01_BZ : 8|4@1+ (1,0) [0|15] ""  Vector__XXX
 SG_ BH_Blinker_li : 12|1@1+ (1.0,0.0) [0.0|1] ""  TopView
 SG_ BH_Blinker_re : 13|1@1+ (1.0,0.0) [0.0|1] ""  TopView
 SG_ BH_Lichthupe : 14|1@1+ (1.0,0.0) [0.0|1] ""  Vector__XXX
 SG_ BH_Fernlicht : 15|1@1+ (1.0,0.0) [0.0|1] ""  FLA
 SG_ WH_Tipwischen : 16|1@1+ (1.0,0.0) [0.0|1] ""  Vector__XXX
 SG_ WH_Intervall : 17|1@1+ (1.0,0.0) [0.0|1] ""  Vector__XXX
 SG_ WH_WischerStufe1 : 18|1@1+ (1.0,0.0) [0.0|1] ""  Vector__XXX
 SG_ WH_WischerStufe2 : 19|1@1+ (1.0,0.0) [0.0|1] ""  Vector__XXX
 SG_ WH_Frontwaschen : 20|1@1+ (1.0,0.0) [0.0|1] ""  Vector__XXX
 SG_ WH_Heckintervall : 21|1@1+ (1.0,0.0) [0.0|1] ""  Vector__XXX
 SG_ WH_Heckwaschen : 22|1@1+ (1.0,0.0) [0.0|1] ""  Vector__XXX
 SG_ WH_Intervallstufen : 23|4@1+ (1.0,0.0) [0.0|15] ""  Vector__XXX
 SG_ FAS_Taster : 27|1@1+ (1.0,0.0) [0.0|1] ""  Vector__XXX
 SG_ FAS_Taster_Fehler : 28|1@1+ (1.0,0.0) [0.0|1] ""  Vector__XXX
 SG_ SMLS_Hupe : 29|1@1+ (1.0,0.0) [0.0|1] ""  Vector__XXX
 SG_ LRH_on_off : 30|2@1+ (1.0,0.0) [0.0|3] ""  Vector__XXX
 SG_ LRH_aktiv : 40|1@1+ (1.0,0.0) [0.0|1] ""  Vector__XXX
 SG_ SMLS_P_verriegelt_plausibel : 43|1@1+ (1.0,0.0) [0.0|1] ""  Vector__XXX
 SG_ WH_SRA : 44|1@1+ (1.0,0.0) [0.0|1] ""  Vector__XXX
 SG_ WH_Wischer_Fehler : 45|1@1+ (1.0,0.0) [0.0|1] ""  Vector__XXX
 SG_ BH_Blinker_Fehler : 46|1@1+ (1.0,0.0) [0.0|1] ""  Vector__XXX
 SG_ SMLS_PTT : 47|1@1+ (1.0,0.0) [0.0|1] ""  Vector__XXX
 SG_ WH_Tipwischen_lang : 48|1@1+ (1.0,0.0) [0.0|1] ""  Vector__XXX

BO_ 1710 Spiegel_01: 8 Gateway
 SG_ SP_FT_oben : 0|1@1+ (1.0,0.0) [0.0|1] ""  Vector__XXX
 SG_ SP_FT_unten : 1|1@1+ (1.0,0.0) [0.0|1] ""  Vector__XXX
 SG_ SP_FT_links : 2|1@1+ (1.0,0.0) [0.0|1] ""  Vector__XXX
 SG_ SP_FT_rechts : 3|1@1+ (1.0,0.0) [0.0|1] ""  Vector__XXX
 SG_ SP_BT_oben : 4|1@1+ (1.0,0.0) [0.0|1] ""  Vector__XXX
 SG_ SP_BT_unten : 5|1@1+ (1.0,0.0) [0.0|1] ""  Vector__XXX
 SG_ SP_BT_links : 6|1@1+ (1.0,0.0) [0.0|1] ""  Vector__XXX
 SG_ SP_BT_rechts : 7|1@1+ (1.0,0.0) [0.0|1] ""  Vector__XXX
 SG_ SP_abklappen : 8|1@1+ (1.0,0.0) [0.0|1] ""  Vector__XXX
 SG_ SP_anklappen : 9|1@1+ (1.0,0.0) [0.0|1] ""  Vector__XXX
 SG_ SP_normieren : 10|1@1+ (1.0,0.0) [0.0|1] ""  Vector__XXX
 SG_ SP_Hzg_Taster : 12|1@1+ (1.0,0.0) [0.0|1] ""  Vector__XXX
 SG_ SP_S_oben : 16|1@1+ (1.0,0.0) [0.0|1] ""  Vector__XXX
 SG_ SP_S_unten : 17|1@1+ (1.0,0.0) [0.0|1] ""  Vector__XXX
 SG_ SP_S_links : 18|1@1+ (1.0,0.0) [0.0|1] ""  Vector__XXX
 SG_ SP_S_rechts : 19|1@1+ (1.0,0.0) [0.0|1] ""  Vector__XXX
 SG_ SP_Auswahl_li : 20|1@1+ (1.0,0.0) [0.0|1] ""  Vector__XXX
 SG_ SP_Auswahl_re : 21|1@1+ (1.0,0.0) [0.0|1] ""  Vector__XXX
 SG_ SP_ARA_Status : 22|1@1+ (1.0,0.0) [0.0|1] ""  Vector__XXX
 SG_ SP_S_Klappen : 23|1@1+ (1.0,0.0) [0.0|1] ""  TopView
 SG_ SP_Verstellschalter_Fehler : 24|1@1+ (1.0,0.0) [0.0|1] ""  Vector__XXX

BO_ 1313 STH_01: 8 STH_MLBevo
 SG_ STH_Funk_ein : 0|1@1+ (1.0,0.0) [0.0|1] ""  Gateway,Gateway_PAG
 SG_ STH_Funk_aus : 1|1@1+ (1.0,0.0) [0.0|1] ""  Gateway,Gateway_PAG
 SG_ STH_Zusatzheizung : 2|1@1+ (1.0,0.0) [0.0|1] ""  Gateway,Gateway_PAG
 SG_ STH_LED : 3|1@1+ (1.0,0.0) [0.0|1] ""  Gateway,Gateway_PAG
 SG_ STH_Pumpe_ein : 4|1@1+ (1,0) [0|1] ""  Gateway,Gateway_PAG
 SG_ STH_Geblaese : 5|1@1+ (1.0,0.0) [0.0|1] ""  Gateway,Gateway_PAG
 SG_ STH_EKP_Anst : 6|1@1+ (1.0,0.0) [0.0|1] ""  Gateway,Gateway_PAG
 SG_ STH_Start_folgt : 7|1@1+ (1.0,0.0) [0.0|1] ""  Gateway,Gateway_PAG
 SG_ STH_Ventiloeffnungszeit : 8|6@1+ (1,0) [0|63] "Unit_Minut"  Gateway,Gateway_PAG
 SG_ STH_Ventil_Status : 14|1@1+ (1.0,0.0) [0.0|1] ""  Gateway,Gateway_PAG
 SG_ STH_Fehler_ElWaPu : 15|1@1+ (1.0,0.0) [0.0|1] ""  Gateway,Gateway_PAG
 SG_ STH_Waermeeintrag : 16|6@1+ (1,0) [0|63] ""  Gateway,Gateway_PAG
 SG_ STH_Pumpen_Anf_extern : 22|1@1+ (1.0,0.0) [0.0|1] ""  Gateway,Gateway_PAG
 SG_ STH_KL_HUP : 23|1@1+ (1.0,0.0) [0.0|1] ""  Gateway,Gateway_PAG
 SG_ STH_KVS : 24|13@1+ (1,0) [0|8191] "Unit_MilliLiter"  Gateway,Gateway_PAG
 SG_ STH_Fehlerstatus : 37|3@1+ (1.0,0.0) [0.0|7] ""  Gateway,Gateway_PAG
 SG_ STH_Heizleistung : 40|8@1+ (1,0) [0|255] ""  Gateway,Gateway_PAG
 SG_ STH_Wassertemp : 48|8@1+ (0.75,-40) [-40.00|142.25] "Unit_DegreCelsi"  Gateway,Gateway_PAG
 SG_ STH_Texte : 56|3@1+ (1.0,0.0) [0.0|7] ""  Gateway,Gateway_PAG
 SG_ STH_Motorvorwaermung : 59|1@1+ (1.0,0.0) [0.0|1] ""  Gateway,Gateway_PAG
 SG_ STH_Servicemode : 60|1@1+ (1,0) [0|1] ""  Gateway,Gateway_PAG
 SG_ STH_war_aktiv : 61|1@1+ (1.0,0.0) [0.0|1] ""  Gateway,Gateway_PAG
 SG_ STH_KVS_Ueberlauf : 62|1@1+ (1.0,0.0) [0.0|1] ""  Gateway,Gateway_PAG
 SG_ STH_SH_ZH : 63|1@1+ (1.0,0.0) [0.0|1] ""  Gateway,Gateway_PAG

BO_TX_BU_ 1355 :Gateway,Gateway_PAG;
BO_TX_BU_ 2527679498 :Gateway,Gateway_PAG;
BO_TX_BU_ 319 :Gateway,Gateway_PAG;
BO_TX_BU_ 1122 :Gateway,Gateway_PAG;
BO_TX_BU_ 1123 :Gateway,Gateway_PAG;
BO_TX_BU_ 1124 :Gateway,Gateway_PAG;
BO_TX_BU_ 1440 :Gateway,Gateway_PAG;
BO_TX_BU_ 1528 :ISE,SAK;
BO_TX_BU_ 424 :Gateway,Gateway_PAG;
BO_TX_BU_ 980 :Gateway,Gateway_PAG;
BO_TX_BU_ 1710 :Gateway,Gateway_PAG;
CM_ BO_ 1355 "neue Struktur ab MQB ohne KD-Fehler";
CM_ BO_ 1529 "MQB";
CM_ BO_ 1440 "8Byte ab MLBevo
LIN-CAN (1:1) Botschaften werden geroutet
-  wenn entsprechender Slave codiert ist
-  wenn fehlerfreie Kommunikation zum Slave besteht
-  bei fehlerhafter Kommunikation zum Slave wird die Botschaft für 4s mit den letzten gültigen Werte";
CM_ BO_ 1528 "ab MQB mit geändertem Charisma, ohne KD-Fehler";
CM_ BO_ 424 "CAN-Botschaft";
CM_ BO_ 1510 "Teilenummer & Checksumme für OBD-Lampe";
CM_ BO_ 980 "Ab MQB 7.2";
CM_ BO_ 1710 "MLBevo 8Byte";

CM_ SG_ 1355 BCM_WAH_Meldung "Steuert die HMI-Meldungen im Kombi für den Wiederanfahrhinweis";
CM_ SG_ 1355 PDC_Charisma_FahrPr "Istwert der Kennline (siehe System-LAH MQB FPA)";
CM_ SG_ 1355 PDC_Charisma_Status "Charisma Systemstatus des Charisma-Teilnehmers";
CM_ SG_ 1355 PH_Aufschaltursache "Der Grund für die Aufschaltung der Einparkhilfe wird angegeben, z.B. bei der Aktivierung der Einparkhilfe durch eine andere Funktion, wird diese Funktion als Aktivierungsursache für die Dauer der Aktivierung gemeldet.
Das Signal wird den PH_Systemzustand";
CM_ SG_ 1355 PH_Ton_Ausgabe "Anforderung einer Tonausgabe beim MIB3 durch die Parkhilfe";
CM_ SG_ 1355 PH_Ton_Lautstaerke "Wunschlautstärke der Tonanforderung beim MIB3 durch die Parkhilfe.";
CM_ SG_ 1355 PH_Ton_Pausenlaenge "Pause zwischen den angeforderten Tönen beim MIB3 durch die Parkhilfe. Nur für Intervalltöne, nicht relevant für Dauerton und Quittierungston.";
CM_ SG_ 1355 PH_Ton_Richtung "Abspielrichtung des angeforderten Ton beim MIB3 durch die Parkhilfe";
CM_ SG_ 1355 PH_Verschmutzungsmeldung "Meldung einer Verschmutzung/Vereisung der PDC an das Kombi";

CM_ SG_ 2527679498 IAA_Active_User_ID "Signal gibt die IAA Nutzer ID des aktiven IAA Nutzers an.";
CM_ SG_ 2527679498 IAA_Identified_User_ID "Signal gibt die IAA Nutzer ID des vom BCM identifizierten IAA Nutzers an";
CM_ SG_ 2527679498 IAA_PSO_wake_up "Signal zum Wake_up der IAA und PSO Komponenten im Kombi und in der OCU";
CM_ SG_ 2527679498 Perso_Aktiv "Status Personalisierung für den Fahrer aktiviert/ deaktiviert (via HMI)";
CM_ SG_ 2527679498 Perso_Bedienstelle "Signal zeigt an, über welche Bedienstelle die Umschaltung des Benutzerkontos gestartet wurden.";
CM_ SG_ 2527679498 Perso_Fahrernummer "Signal gibt die jewels aktuelle Nummer des Fahrers für die Personalisierung an.
Nicht für AU736 und AU48x.";
CM_ SG_ 2527679498 Perso_Freigabe_Verstellung "Signal zeigt an, ob die Ergonomiefunktionen nach Umschaltung des Benutzerkontos verfahren dürfen.";
CM_ SG_ 2527679498 Perso_Kontonummer "Signal gibt die jewels aktuelle Kontonummer für die Personalisierung an.
Nicht für AU736 und AU48x.";
CM_ SG_ 2527679498 Perso_Schreibschutz "Signal zeigt an, ob der Schreibschutz der Personalisierung aktiv ist.";
CM_ SG_ 2527679498 Perso_Status "Codierstatus der Personalisierung
Nicht für AU736 und AU49x.";
CM_ SG_ 2527679498 Perso_Steuerung "Signal gibt einen Steuerungsbefehl an die Funktionsteilnehmer der Personalisierung.
Nicht für AU736 und AU49x.";
CM_ SG_ 2527679498 Perso_Steuerungsparameter "Signal gibt einen Parameter zum Steuerungsbefehl (Signal Perso_Steuerung) für die Personalisierung an.
Nicht für AU736 und AU49x.";

CM_ SG_ 319 PreCrash_02_BZ "Botschaftszaehler
Botschaft asynchron geroutet. Zählerwert kann springen.";
CM_ SG_ 319 PreCrash_02_CRC "Ab MQB und MLBevo:
'Berechnung siehe Lastenheft 'End-to-End Kommunikationsabsicherung''

Endwerte siehe Begleitdokument 'S-PDU Kennungsfolgen'";
CM_ SG_ 319 PreCrash_Anforderung_AFR "Anforderungen der Funktion PrecrashSeite an Fahrwerksregelung";
CM_ SG_ 319 PreCrash_BFS_KSV_verfahren "Ansteuerung der Kopfstuetze Beifahrerseite durch die Funktion PreCrash

Signalwert 0x09 für vereinfachte Ansteuerung mit Logik im Sitz-SG (MQB37W)";
CM_ SG_ 319 PreCrash_BFS_Pneumatik_ansteuern "Ansteuerung des Beifahrersitzes durch die PreCrash-Funktionen";
CM_ SG_ 319 PreCrash_BFS_Sitzlehne_verfahren "Ansteuerung des Beifahrersitzes durch die PreCrash-Funktionen

Wert 0x06 und 0x07 für vereinfachte Ansteuerung Sitzlehne";
CM_ SG_ 319 PreCrash_Blinken "Safety Computer übermittelt Blinkverhalten bei einer PreCrash-Auslösung an den BCM2";
CM_ SG_ 319 PreCrash_Charisma_FahrPr "Aktuell eingestelltes Fahrprogramm der Funktion PreCrash";
CM_ SG_ 319 PreCrash_Charisma_Status "Verfügbarkeit der Funktion PreCrash für die Ansteuerung durch den Charisma_Koordinator";
CM_ SG_ 319 PreCrash_Fenster_schliessen "Anforderung Seitenscheiben schließen durch die Funktion PreCrash";
CM_ SG_ 319 PreCrash_Fo_KSV_verfahren "Ansteuerung der Kopfstuetzen im Fond durch die PreCrash-Funktionen";
CM_ SG_ 319 PreCrash_Fo_Pneumatik_ansteuern "Ansteuerung der Fondsitze durch die PreCrash-Funktionen";
CM_ SG_ 319 PreCrash_Fo_Sitzlehne_verfahren "Ansteuerung des Fondsitzes durch die PreCrash-Funktionen";
CM_ SG_ 319 PreCrash_FS_KSV_verfahren "Ansteuerung der Kopfstuetze Fahrerseite durch die PreCrash-Funktionen

Signalwert 0x09 für vereinfachte Ansteuerung mit Logik im Sitz-SG (MQB37W)";
CM_ SG_ 319 PreCrash_FS_Pneumatik_ansteuern "Ansteuerung des Fahrersitzes durch die PreCrash-Funktionen";
CM_ SG_ 319 PreCrash_FS_Sitzlehne_verfahren "Ansteuerung des Fahrersitzes durch die PreCrash-Funktionen

Wert 0x06 und 0x07 für vereinfachte Ansteuerung Sitzlehne";
CM_ SG_ 319 PreCrash_Schiebedach_schliessen "Anforderung Schiebedach schließen durch die Funktion PreCrash";
CM_ SG_ 319 PreCrash_Tueren_Verriegeln "Anforderung Türen Verriegeln durch die Funktion PreCrash";
CM_ SG_ 319 SC_PreCrash_LED "Ansteuerung LED-Leiste im Kombi durch SC";
CM_ SG_ 319 SC_PreCrash_Texte "Safety Computer übermittelt Systemstatus der PreCrash Funktionen an Kombi";
CM_ SG_ 319 SC_PreCrash_Warnung "Safety Computer übermittelt Warnung der PreCrash Funktionen an Kombi";
CM_ SG_ 319 SC_PreSense_FCWP "Mitteilung an das NightVision, auf welche Art von Objekt eine Warnung angefordert wird";

CM_ SG_ 1122 PSD_Abzweigerichtung "Richtung, in der die Abzweigung von der Hauptroute abzweigt
";
CM_ SG_ 1122 PSD_Abzweigewinkel "Winkel, unter dem die Abzweigung von der Hauptroute abzweigt.
";
CM_ SG_ 1122 PSD_ADAS_Qualitaet "ADAS Qualtität des Streckensegments.";
CM_ SG_ 1122 PSD_Anfangskruemmung "Startkrümmung der Klothoide des übermittelten abzweigenden Streckensegments. 
1/(1+0.155 * x^2) {1/m}'
";
CM_ SG_ 1122 PSD_Anfangskruemmung_Vorz "Vorzeichen für die Startkrümmung bei Abzweigungen
";
CM_ SG_ 1122 PSD_Bebauung "Segement befindet sich innerhalb bebauten Gebietes";
CM_ SG_ 1122 PSD_Endkruemmung "'Endkrümmung der Klotoide des übermittelten Streckensegments. Die Anfangskrümmung des folgenden Streckensegments entspricht der Endkrümmung dieses Segments. Krümmung = 1/(1+0.155 * x²) [1/m]

";
CM_ SG_ 1122 PSD_Fahrspuren_Anzahl "Anzahl der Fahrspuren in Fahrtrichtung
";
CM_ SG_ 1122 PSD_Geradester_Pfad "Segment ist Teil des geradesten Pfades";
CM_ SG_ 1122 PSD_Idenditaets_ID "Identifier auf ein Streckensegment, dass mit dem aktuell übertragenen geometrisch identisch ist.";
CM_ SG_ 1122 PSD_Segment_ID "Identifier des prädiktiven Streckensegments
";
CM_ SG_ 1122 PSD_Segment_Komplett "Zeigt, ob alle Attribute für das Segment übertragen worden sind
";
CM_ SG_ 1122 PSD_Segmentlaenge "Gesamtlänge des prädiktiven Streckensegments";
CM_ SG_ 1122 PSD_Strassenkategorie "Klassifizierung der Straße des beschriebenen Segments
";
CM_ SG_ 1122 PSD_Vorgaenger_Segment_ID "An dem Streckensegment mit diesem Identifier schließt sich das neue Segment mit der ID 'PSD_01_Segment_ID' an.
";
CM_ SG_ 1122 PSD_wahrscheinlichster_Pfad "Identifiziert den vom Navigationssystem berechneten wahrscheinlichsten Pfad des Fahrzeuges. ";

CM_ SG_ 1123 PSD_Attribut_1_ID "Identifier des ersten Attributes";
CM_ SG_ 1123 PSD_Attribut_1_Offset "Positionsoffset im Segment für die Position des Attributs";
CM_ SG_ 1123 PSD_Attribut_1_Wert "Wert des ersten Attributes";
CM_ SG_ 1123 PSD_Attribut_2_ID "Identifier des zweiten Attributes";
CM_ SG_ 1123 PSD_Attribut_2_Offset "Positionsoffset im Segment für die Position des Attributs";
CM_ SG_ 1123 PSD_Attribut_2_Wert "Wert des zweiten Attributes";
CM_ SG_ 1123 PSD_Attribut_Segment_ID_05 "Identifier des Streckensegments, für das die weiteren Attribute in der Botschaft gültig sind";
CM_ SG_ 1123 PSD_Attribute_Komplett_05 "Zeigt, ob alle Attribute für das Segment übertragen worden sind";
CM_ SG_ 1123 PSD_Pos_Fahrspur "Spur, auf der sich das Fahrzeug aktuell befindet";
CM_ SG_ 1123 PSD_Pos_Fehler_Laengsrichtung "Laengsfehler der Positionierung";
CM_ SG_ 1123 PSD_Pos_Inhibitzeit "Zeitspanne zwischen Generierung der PSD Daten im Navigationssystem und Versand der Daten auf den Most
";
CM_ SG_ 1123 PSD_Pos_Segment_ID "Identifier des Streckensegments, auf dem sich das Fahrzeug aktuell befindet
";
CM_ SG_ 1123 PSD_Pos_Segmentlaenge "Verbleibende Länge des Streckensegments, auf dem sich das Fahrzeug aktuell befindet
";
CM_ SG_ 1123 PSD_Pos_Standort_Eindeutig "Ist die Position des Fahrzeugs eindeutig dem aktuelle Segment zugeordnet, oder gibt es fahrbare alternative Segmente, die bei akteller GPS-Position ebenfalls als aktuelles Segment möglich wären.";

CM_ SG_ 1124 PSD_06_Mux "Multiplex Zähler für die PSD_06-Botschaft";
CM_ SG_ 1124 PSD_Attribut_3_ID "Identifier des dritten Attributes";
CM_ SG_ 1124 PSD_Attribut_3_Offset "Positionsoffset im Segment für die Position des Attributs";
CM_ SG_ 1124 PSD_Attribut_3_Wert "Wert des dritten Attributes";
CM_ SG_ 1124 PSD_Attribut_4_ID "Typ von Attribut 4";
CM_ SG_ 1124 PSD_Attribut_4_Offset "Offset von Attribut 4";
CM_ SG_ 1124 PSD_Attribut_4_Wert "Wert von Attribut 4";
CM_ SG_ 1124 PSD_Attribut_5_ID "Typ von Attribut 5";
CM_ SG_ 1124 PSD_Attribut_5_Offset "Offset von Attribut 5";
CM_ SG_ 1124 PSD_Attribut_5_Wert "Wert von Attribut 5";
CM_ SG_ 1124 PSD_Attribut_Segment_ID "Identifier des Streckensegments,für das die weiteren Attribute in der Botschaft gültig sind";
CM_ SG_ 1124 PSD_Attribute_Komplett_06 "Zeigt, ob alle Attribute für das Segment übertragen worden sind
";
CM_ SG_ 1124 PSD_Baum_Ausrichtung "Ausrichtung des Fahrzeugsegments zu Nord";
CM_ SG_ 1124 PSD_Baum_Breite "WGS84 Breite des Fahrzeugsegments";
CM_ SG_ 1124 PSD_Baum_Breite_VZ "Vorzeichen WGS84 Breite des Fahrzeugsegments";
CM_ SG_ 1124 PSD_Baum_Laenge "WGS84 Laenge des Fahrzeugsegments";
CM_ SG_ 1124 PSD_Baum_Laenge_VZ "Vorzeichen WGS84 Laenge des Fahrzeugsegments";
CM_ SG_ 1124 PSD_Ges_Attribute_Komplett "Zeigt, ob alle Attribute für das Segment übertragen worden sind";
CM_ SG_ 1124 PSD_Ges_Geschwindigkeit_Gespann "Gilt diese Einschränkung der Geschwindigkeit für alle Fahrzeuge oder ausschließlich für PKW mit Gespann oder für LKW, Buss, etc.";
CM_ SG_ 1124 PSD_Ges_Geschwindigkeit_Std_Anf "Stunde, zu der die stündliche Geschwindigkeitsbegrenzung beginnt
0h.. 24h";
CM_ SG_ 1124 PSD_Ges_Geschwindigkeit_Std_Ende "Stunde, an der die stündliche Geschwindigkeitsbegrenzung endet
0h.. 24h";
CM_ SG_ 1124 PSD_Ges_Geschwindigkeit_Tag_Anf "Wochentag, an dem die tägliche Geschwindigkeitsbegrenzung beginnt";
CM_ SG_ 1124 PSD_Ges_Geschwindigkeit_Tag_Ende "Wochentag, an dem die tägliche Geschwindigkeitsbegrenzung endet";
CM_ SG_ 1124 PSD_Ges_Geschwindigkeit_Witter "Witterungsabhängigkeit der Geschwindigkeitsbegrenzung";
CM_ SG_ 1124 PSD_Ges_Gesetzlich_Kategorie "Kategorie für das legale Gebot";
CM_ SG_ 1124 PSD_Ges_Gesetzlich_Zusatz "Zusatz für das legale Gebot";
CM_ SG_ 1124 PSD_Ges_Offset "Positionsoffset im Segment für die Position des Attributs";
CM_ SG_ 1124 PSD_Ges_Segment_ID "Identifier des prädiktiven Streckensegments ab dem die Geschwindigkeitsbegrenzungen und mögliche Einschränkungen gelten.
";
CM_ SG_ 1124 PSD_Ges_Spur_Geschw_Begrenzung "Definition der Spuren, für die das übertragene Gebot gilt";
CM_ SG_ 1124 PSD_Ges_Typ "Typ der Geschwindigkeitsbegrenzung
";
CM_ SG_ 1124 PSD_Ges_Verkehrszeichen_Quelle "Quelle der Verkehrszeicheninformation";
CM_ SG_ 1124 PSD_Ges_Wechselverkehrszeichen "Am Beginn des Segments ist ein Wechselverkehrszeichen angebracht.";
CM_ SG_ 1124 PSD_Steigung_1_A_Offset "Positionsoffset im Segment für die Position der Steigung 1 A";
CM_ SG_ 1124 PSD_Steigung_1_A_Steigung "Steigung des Segments ab Offset 1A";
CM_ SG_ 1124 PSD_Steigung_1_A_Vorz "Vorzeichen für Steigung 1 A";
CM_ SG_ 1124 PSD_Steigung_1_Attribute_kompl "Alle Steigungsdaten für dieses Segment gesendet";
CM_ SG_ 1124 PSD_Steigung_1_B_Offset "Positionsoffset im Segment für die Position der Steigung 1 B";
CM_ SG_ 1124 PSD_Steigung_1_B_Steigung "Steigung des Segments ab Offset 1B";
CM_ SG_ 1124 PSD_Steigung_1_B_Vorz "Vorzeichen für Steigung 1 B";
CM_ SG_ 1124 PSD_Steigung_1_Segment_ID "Identifier des prädiktiven Streckensegments, zu dem die  ersten beiden Steigungswerte dieser Botschaft gehören";
CM_ SG_ 1124 PSD_Steigung_2_Attribute_kompl "Alle Steigungsdaten für dieses Segment gesendet";
CM_ SG_ 1124 PSD_Steigung_2_Offset "Positionsoffset im Segment für die Position der Steigung 2";
CM_ SG_ 1124 PSD_Steigung_2_Segment_ID "Identifier des prädiktiven Streckensegments, zu dem der dritte Steigungswert dieser Botschaft gehört";
CM_ SG_ 1124 PSD_Steigung_2_Steigung "Steigung des Segments ab Offset 2";
CM_ SG_ 1124 PSD_Steigung_2_Vorz "Vorzeichen für Steigung 2";
CM_ SG_ 1124 PSD_Sys_Alter_Karte "Alter der Karte";
CM_ SG_ 1124 PSD_Sys_Geometrieguete "Maß für die Güte der Klothoidengeometrie.";
CM_ SG_ 1124 PSD_Sys_Geometrieguete_erweitert "Güte der Kurvenrepräsentation der Klothoiden";
CM_ SG_ 1124 PSD_Sys_Geschwindigkeit_Einheit "Unterscheidung zwischen km/h und miles/h";
CM_ SG_ 1124 PSD_Sys_Laendercode "Ländercode
";
CM_ SG_ 1124 PSD_Sys_Mapmatchingguete "Güte des Mapmatchings";
CM_ SG_ 1124 PSD_Sys_Quali_Geometrien "Qualität der Geometrien in dieser Region";
CM_ SG_ 1124 PSD_Sys_Quali_Ortsinfo "Qualität Ortsinformationen (Bebauung, Ortsschild) dieser Region";
CM_ SG_ 1124 PSD_Sys_Quali_sonstige_Attribute "Qualität sonstiger Attribute dieser Region";
CM_ SG_ 1124 PSD_Sys_Quali_Steigungen "Qualität der Steigungen dieser Region";
CM_ SG_ 1124 PSD_Sys_Quali_Strassenkennz "Qualität Straßenkennzeichnungen dieser Region";
CM_ SG_ 1124 PSD_Sys_Quali_Tempolimits "Qualität Tempolimits dieser Region";
CM_ SG_ 1124 PSD_Sys_Quali_verfuegbar "Karte enthält gültige Qualitätskriterien";
CM_ SG_ 1124 PSD_Sys_Quali_Vorfahrtsregelung "Qualität Vorfahrtsregelungen dieser Region";
CM_ SG_ 1124 PSD_Sys_Segment_ID "Identifier des prädiktiven Streckensegments ab dem die Systeminformationen gültig sind.
";
CM_ SG_ 1124 PSD_Sys_US_State "Name des USA-State";
CM_ SG_ 1124 PSD_Sys_Verkehrsrichtung "Unterscheidung zwischen Linksverkehr und Rechtsverkehr";
CM_ SG_ 1124 PSD_Sys_Zielfuehrung "Zielfuehrung im Navigationssystem. Damit lässt sich der wahrscheinlichste Pfad des Fahrzeuges zuverlässig angeben.";
CM_ SG_ 1124 PSD_Sys_Zielfuehrung_geaendert "Die Zielführung (Route) hat sich geändert hat ohne dass der Fahrer eine neue Zielführung gestartet hat";
CM_ SG_ 1124 PSD_Wechselverkehrszeichen_Typ "Typ des Wechselverkehrszeichen";

CM_ SG_ 1529 RDK_FMVSS138_Lampe "Ansteuerung der RDK-Lampe im Kombi bei Druckwarnung";
CM_ SG_ 1529 RDK_FMVSS138_MIL "Ansteuerung der RDK-Lampe im Kombi bei Systemstörung.
RDK-Lampe muss für 65 Sekunden blinken und anschliessend dauerhaft leuchten bis RDK dieses Bit wieder auf '0' setzt (Wiedergutprüfung).
Hinweis:  Im AU48x blinken für 60 Sekunden";
CM_ SG_ 1529 RDK_Kalibrierung "Art der Vorgabe der Solldrücke
0x0 Vorgabe der Solldrücke erfolgt durch eine Reifenauswahl in der Headunit
0x1 Vorgabe der Solldrücke erfolgt durch Betätigung des SET-Tasters des Kombiinstruments";
CM_ SG_ 1529 RDK_Reifendruck_Lampe "Ansteuerung einer RDK-Lampe im Kombi bei einem problematischen Druck";
CM_ SG_ 1529 RDK_Reifentemperatur_Lampe "Ansteuerung einer RDK-Lampe im Kombi bei einer problematischen Reifentemperatur";
CM_ SG_ 1529 RDK_W_1_Reifen_HL "Harte Warnung fuer Reifen hinten links";
CM_ SG_ 1529 RDK_W_1_Reifen_HR "Harte Warnung fuer Reifen hinten rechts";
CM_ SG_ 1529 RDK_W_1_Reifen_VL "Harte Warnung fuer Reifen vorne links";
CM_ SG_ 1529 RDK_W_1_Reifen_VR "Harte Warnung fuer Reifen vorne rechts
";
CM_ SG_ 1529 RDK_W_2_Reifen_HL "Weiche Warnung fuer Reifen hinten links";
CM_ SG_ 1529 RDK_W_2_Reifen_HR "Weiche Warnung fuer Reifen hinten rechts";
CM_ SG_ 1529 RDK_W_2_Reifen_VL "Weiche Warnung fuer Reifen vorne links";
CM_ SG_ 1529 RDK_W_2_Reifen_VR "Weiche Warnung fuer Reifen vorne rechts";
CM_ SG_ 1529 RDK_Warnungen_02 "Ausgabe von Texten/Akustik im Kombiinstrument";

CM_ SG_ 2589283632 RDK_Diff_Druck_HL "Differenzdruck zwischen Ist- und Solldruck HL, normiert auf 20°C";
CM_ SG_ 2589283632 RDK_Diff_Druck_HR "Differenzdruck zwischen Ist- und Solldruck HR, normiert auf 20°C";
CM_ SG_ 2589283632 RDK_Diff_Druck_VL "Differenzdruck zwischen Ist- und Solldruck VL, normiert auf 20°C";
CM_ SG_ 2589283632 RDK_Diff_Druck_VR "Differenzdruck zwischen Ist- und Solldruck VL, normiert auf 20°C";
CM_ SG_ 2589283632 RDK_Reifengroesse "Ausgabe der Reifengröße (Vorderachse)";
CM_ SG_ 2589283632 RDK_Reifentyp "Ausgabe von Reifentyp";
CM_ SG_ 2589283632 RDK_SollDruck_HA "Solldruck hinten";
CM_ SG_ 2589283632 RDK_SollDruck_VA "Solldruck vorne";

CM_ SG_ 1651 RDK_Druck_HL_unkomp "Reifendruck hinten links unkompensiert für BC";
CM_ SG_ 1651 RDK_Druck_HR_unkomp "Reifendruck hinten rechts unkompensiert für BC";
CM_ SG_ 1651 RDK_Druck_VL_unkomp "Reifendruck vorne links unkompensiert für BC";
CM_ SG_ 1651 RDK_Druck_VR_unkomp "Reifendruck vorne rechts unkompensiert für BC";
CM_ SG_ 1651 RDK_R_Temp_HL "Reifentemperatur hinten links";
CM_ SG_ 1651 RDK_R_Temp_HR "Reifentemperatur hinten rechts";
CM_ SG_ 1651 RDK_R_Temp_VL "Reifentemperatur vorne links";
CM_ SG_ 1651 RDK_R_Temp_VR "Reifentemperatur vorne rechts";
CM_ SG_ 1651 RDK_Signal_Alter_HL "Gibt die Aktualitaet/ Alter des Sensorsignals an.";
CM_ SG_ 1651 RDK_Signal_Alter_HR "Gibt die Aktualitaet/ Alter des Sensorsignals an.";
CM_ SG_ 1651 RDK_Signal_Alter_VL "Gibt die Aktualitaet/ Alter des Sensorsignals an.";
CM_ SG_ 1651 RDK_Signal_Alter_VR "Gibt die Aktualitaet/ Alter des Sensorsignals an.";

CM_ SG_ 1711 RV_Dark_Screen "Verdunkelungsanforderung Kamerabild";
CM_ SG_ 1711 RV_Farbe "Istwert fuer Farbe (in Prozent)";
CM_ SG_ 1711 RV_Helligkeit "Istwert fuer Helligkeit (in Prozent)";
CM_ SG_ 1711 RV_HMI_Mode "Aktueller Wert für den HMI-Modus

";
CM_ SG_ 1711 RV_Kontrast "Istwert fuer Kontrast (in Prozent)";
CM_ SG_ 1711 RV_Menu_Item "Ausgewähltes Menü-Item
";
CM_ SG_ 1711 RV_Reinigung_Anf "Anforderung Reinigung der Rückfahrkamera";
CM_ SG_ 1711 RV_Settings_enabled "Menü 'Einstellungen'
";
CM_ SG_ 1711 RV_System_aktiv "Systemstatus (Initialisierungsphase)
";
CM_ SG_ 1711 RV_Video_on "Anzeige Kamerabild
";
CM_ SG_ 1711 SV_Video_on "Aufschaltaufforderung SideView";
CM_ SG_ 1711 ZFAS_Umfeldbeleuchtung_Anf "Anforderung für die Aktivierung einer Umfeldbeleuchtung zur Unterstützung des Umfeldkamerasystems bei Dunkelheit";

CM_ SG_ 1440 LS_defekt "Fehlererkennung Lichtsensor
";
CM_ SG_ 1440 LS_Verbau "Verbauinfo Lichtsensor
";
CM_ SG_ 1440 RLS_Vorfeldhelligkeit_Boost "erweiterte Helligkeitssensierung für HUD";
CM_ SG_ 1440 RS_defekt "Fehlererkennung Regensensor";
CM_ SG_ 1440 RS_Regenmenge "Regenmenge für intel. Heckleuchte ";
CM_ SG_ 1440 RS_Verbau "Verbauinfo Regensensor";
CM_ SG_ 1440 RS_Verglasung_schliessen "Anforderung: Verglasung schliessen
";
CM_ SG_ 1440 RS_Wischergeschwindigkeit "Wischergeschwindigkeit (Hübe/min)";

CM_ SG_ 1528 SAK_Charisma_FahrPr "MLBevo: Aktuelles Fahrprogramm des Charisma-Teilnehmers (siehe Systemlastenheft Drive Select)
MQB: Istwert der Kennlinie (siehe Systemlastenheft MQB FPA)";
CM_ SG_ 1528 SAK_Charisma_Status "Rückmeldung an den Charisma-Master

Wert 0x3 ist nur für Fahrzeuge ab MQB relevant";

CM_ SG_ 424 SARA_11_CRC "Für MLB:
'Berechnung siehe Lastenheft 'Kommunikationsabsicherung für Flexray und CAN''

Ab MQB und MLBevo:
'Berechnung siehe Lastenheft 'End-to-End Kommunikationsabsicherung'

Endwerte siehe Begleitdokument 'S-PDU Kennungsfolge'";
CM_ SG_ 424 SARA_Accel_X_r "Beschleunigung Acceleration-X routable:
- 0x0000= Sensor nicht verbaut, Signal wird nicht berechnet
- genutzter Wertebereich ± 640 m/s²

Filterung: 60 Hz Sensorfilter + 15 Hz uC-Filter (Cheby-II 3.Ordnung)";
CM_ SG_ 424 SARA_Accel_Y_r "Beschleunigung Acceleration-Y routable:
- 0x0000= Sensor nicht verbaut, Signal wird nicht berechnet
- genutzter Wertebereich ± 640 m/s²

Filterung: 60 Hz Sensorfilter + 15 Hz uC-Filter (Cheby-II 3.Ordnung)";
CM_ SG_ 424 SARA_CF_Accel_X_r "Confidence Faktor Beschleunigung Acceleration-X routable:

0=gültiger Wert
1=nicht belegt
2=nicht belegt
3=Temporärer Fehler {solange möglich werden aktuelle Sensorwerte gesendet, ansonsten 0xFFFF}
4=Init {0x8000 wird gesendet}
5=Sensor nicht verba";
CM_ SG_ 424 SARA_CF_Accel_Y_r "Confidence Faktor Beschleunigung Acceleration-Y routable:

0=gültiger Wert
1=nicht belegt
2=nicht belegt
3=Temporärer Fehler {solange möglich werden aktuelle Sensorwerte gesendet, ansonsten 0xFFFF}
4=Init {0x8000 wird gesendet}
5=Sensor nicht verba";
CM_ SG_ 424 SARA_CF_Omega_Z_r "Confidence Faktor Winkelgeschwindigkeit Omega-Z routable:

0=gültiger Wert
1=nicht belegt
2=nicht belegt
3=Temporärer Fehler {solange möglich werden aktuelle Sensorwerte gesendet, ansonsten 0xFFFF}
4=Init {0x8000 wird gesendet}
5=Sensor nicht verba";
CM_ SG_ 424 SARA_Omega_Z_r "Winkelgeschwindigkeit Omega-Z routable:
- 0x0000 = Sensor nicht verbaut, Signal wird nicht berechnet
- genutzter Wertebereich ± 320 Deg/s

Filterung: 60 Hz Sensorfilter + 15 Hz uC-Filter (Cheby-II 3.Ordnung)";

CM_ SG_ 1011 SCR_01_BZ "Zähler der von der Applikation inkrementiert wird";
CM_ SG_ 1011 SCR_Dosierpumpe_Drehzahl "Drehzahl der Dosierpumpe

negative 1/min für Rückwärtsbetrieb
0 für Stop
positive 1/min für Vorwärtsbetrieb";
CM_ SG_ 1011 SCR_Druck "Druck der wässrigen Harnstofflösung";
CM_ SG_ 1011 SCR_Level_Aktivtank "Füllstand des Aktivtanks";
CM_ SG_ 1011 SCR_Level_ReadAbove "Zeigt an in welchem Messmodus der Levelsensor ist.
Dieses Signal ist für die Füllstandberechnung notwendig und für die OBD-Diagnose mit notwendig.
Ist der Sensor im Readabove Ein Modus, ist die Toleranz des gemessenen Signals größer.";
CM_ SG_ 1011 SCR_QBit_Level_Aktivtank_02 "gibt an ob das Signal gültig ist.";
CM_ SG_ 1011 SCR_Sent_Level_Aktivtank "Füllstand des Aktivtanks";
CM_ SG_ 1011 SCR_Sent_Levelsignal_Status "Gibt an, in welchem Aggregatzustand sich die Flüssigkeit im Aktivtank befindet";

CM_ SG_ 1507 SCR_02_BZ "Zähler der von der Applikation inkrementiert wird";
CM_ SG_ 1507 SCR_Guetesensor "Güte der Flüssigkeit";
CM_ SG_ 1507 SCR_Heizkreis_3_Strom "gemessener Strom vom Heizkreis 3 (ist optional verbaut)";
CM_ SG_ 1507 SCR_Leitungsheizung_Strom "gemessener Strom für die Leitungsheizung";
CM_ SG_ 1507 SCR_Tankheizung_Strom "gemessener Strom für die Tankheizung Aktivtank";
CM_ SG_ 1507 SCR_Temp_Aktivtank "Temperatur des Medium im Aktivtank";
CM_ SG_ 1507 SCR_Temp_Passivtank "Temperatur des Medium im Aktivtank";
CM_ SG_ 1507 SCR_Transferpumpe_Strom "gemessener Strom für dieTransferpumpe";

CM_ SG_ 1508 SCR_03_BZ "Zähler der von der Applikation inkrementiert wird";
CM_ SG_ 1508 SCR_Dosierpumpe_Status_Spule "Statusinformation für OBD-Auswertung";
CM_ SG_ 1508 SCR_Druck_Status_02 "Statusinformation für OBD-Auswertung
KS+ / OC entspricht KS+ nach 5V";
CM_ SG_ 1508 SCR_Heizkreis_3_Status "Statusinformation für OBD-Auswertung";
CM_ SG_ 1508 SCR_Leitungsheizung_Status "Statusinformation für OBD-Auswertung";
CM_ SG_ 1508 SCR_Level_Aktivtank_Status "Statusinformation für OBD-Auswertung
KS+ / OC entspricht KS+ nach 5V
RC+ (alle Schalter offen) UND RC- (Wert unplausibel)";
CM_ SG_ 1508 SCR_Level_Passivtank_Status "Statusinformation für OBD-Auswertung
KS+ / OC entspricht KS+ nach 5V
RC+ (alle Schalter offen) UND RC- (Wert unplausibel)";
CM_ SG_ 1508 SCR_Sensorversorgung_12V_Status "Statusinformation für OBD-Auswertung der 12V-Sensorversorgung";
CM_ SG_ 1508 SCR_Spannungsversorgung_Status "Statusinformation für OBD-Auswertung";
CM_ SG_ 1508 SCR_Tankheizung_Status "Statusinformation für OBD-Auswertung";
CM_ SG_ 1508 SCR_Temp_Aktivtank_Status_02 "Statusinformation für OBD-Auswertung
KS+ / OC entspricht KS+ nach 5V";
CM_ SG_ 1508 SCR_Temp_Passivtank_Status "Statusinformation für OBD-Auswertung
KS+ / OC entspricht KS+ nach 5V";
CM_ SG_ 1508 SCR_Transferpumpe_Status "Statusinformation für OBD-Auswertung";
CM_ SG_ 1508 SCR_VersorgungSensoren_Status_02 "Statusinformation für OBD-Auswertung";

CM_ SG_ 1509 SCR_04_BZ "Zähler der von der Applikation inkrementiert wird";
CM_ SG_ 1509 SCR_Ansteuerung_Dosierpumpe "Messwert im Motor-SG zur Treiber-Ansteuerung der Dosierpumpen Endstufe.";
CM_ SG_ 1509 SCR_Ansteuerung_Heizkreis_3 "Messwert im Motor-SG zur Treiber-Ansteuerung der Heizkreis 3 Endstufe. ";
CM_ SG_ 1509 SCR_Ansteuerung_Leitungsheizung "Messwert im Motor-SG zur Treiber-Ansteuerung der Leitungsheizungs Endstufe. ";
CM_ SG_ 1509 SCR_Ansteuerung_Tankheizung "Messwert im Motor-SG zur Treiber-Ansteuerung der Tankheizungs Endstufe. ";
CM_ SG_ 1509 SCR_Ansteuerung_Transferpumpe "Messwert im Motor-SG zur Treiber-Ansteuerung der Transferpumpe Endstufe. ";
CM_ SG_ 1509 SCR_CAL_CVN_CRC_32 "Gesetzliche Anforderung nach OBD-Gesetz CCR1968.2 (g) (4.7) für 'diagnostic or emission critical powertrain control module'";
CM_ SG_ 1509 SCR_Steuergeraet_PMode "Gibt an ob der Vehicle P-Mode im SCR-Steuergeraet aktiv ist.";

CM_ SG_ 1526 SCR_05_BZ "Zähler der von der Applikation inkrementiert wird";
CM_ SG_ 1526 SCR_DEF_Qualitaet_Medium "Gibt an, dass die Konzentration des Medium nicht ermittelt werden kann.";
CM_ SG_ 1526 SCR_ECU_Datensatz_Status "StatusInformation für OBD-Auswertung";
CM_ SG_ 1526 SCR_HAL_Sensorik_Status "Statusinformation für OBD-Auswertung der HAL-Sensorik";
CM_ SG_ 1526 SCR_Level_Aktivtank_OOR4Quality "Der Füllstand im SCR-Tank ist zu niedrig um eine Qualtiätsmessung durchzuführen.";
CM_ SG_ 1526 SCR_Level_Aktivtank_OOR_minus "Minimaler Level vom SCR-Tank erreicht.
Tankstand so niedrig, dass das Signal nicht mehr verlässlich erfasst werden kann.";
CM_ SG_ 1526 SCR_QBit_Qualitaet "gibt an ob das Signal gültig ist";
CM_ SG_ 1526 SCR_Sent_1_elektrischer_Status "Fehlerstatus der elektrischen Diagnosen";
CM_ SG_ 1526 SCR_Sent_1_Signalstatus "Signalfehler vom Sent_1 Signal";
CM_ SG_ 1526 SCR_Sent_2_elektrischer_Status "Fehlerstatus der elektrischen Diagnosen auf dem zweiten Sentkanal";
CM_ SG_ 1526 SCR_Sent_2_Signalstatus "Signalfehler vom Sent_2  Signal";
CM_ SG_ 1526 SCR_Sent_Levelsensor "Funktionaler Fehlerstatus des Levelsensors";
CM_ SG_ 1526 SCR_Sent_Qualitaetssensor "Funktionalen Fehler des Qualitätssensors";
CM_ SG_ 1526 SCR_Sent_Temperatursensor "Funktionaler Fehlerstatus vom internen Temperatursensor in dem Sentsensor";
CM_ SG_ 1526 SCR_Steuergeraet_Bus_Status "StatusInformation für OBD-Auswertung";
CM_ SG_ 1526 SCR_Steuergeraet_Defekt_Status "StatusInformation für OBD-Auswertung";
CM_ SG_ 1526 SCR_Steuergeraet_Heizung_Status "StatusInformation für OBD-Auswertung";
CM_ SG_ 1526 SCR_Steuergeraet_Pumpe_Status "StatusInformation der Dosierpumpe für OBD-Auswertung";
CM_ SG_ 1526 SCR_Steuergeraet_Relais_Status "StatusInformation für OBD-Auswertung";
CM_ SG_ 1526 SCR_Temp_DEF2_Sensor_Status "Funktionaler Fehlerstatus vom internen Temperatursensor des zweiten Sentsensors";

CM_ SG_ 2527679503 SCR_DEF_CAL_CVN_CRC_32 "Major Monitor Sensor hat eine CVN zu senden";
CM_ SG_ 2527679503 SCR_Level_Aktivtank_saturated "Max. Füllstanderfassung erreicht";
CM_ SG_ 2527679503 SCR_QBit_Qualitaet_Aktivtank "Gibt an ob, dass aktuell gesendetet Qualitysignal gültig ist.";
CM_ SG_ 2527679503 SCR_QBit_Temp_DEF_Sensor_02 "Gibt an ob das Signal SCR_SENT_Temperatur gültig ist.";
CM_ SG_ 2527679503 SCR_Sent_Qualitaet_Aktivtank "Qualitätssignal des Aktivtank";
CM_ SG_ 2527679503 SCR_Temp_DEF_Hinweis "Gibt an ob die Temperatur am Sensor zu hoch oder zu niedrig ist, um eine verlässliches Signal vom Qualitätssensor oder Levelsensor zu bilden.";
CM_ SG_ 2527679503 SCR_Temperatur_DEF_Sensor "internes Temperatursignal vom Qualitätssensor.
Dieses Signal wird für den Crosscheck benötigt um das Qualitätssignal zu qulifizieren. Anforderung OBD-II";

CM_ SG_ 2589283459 SCR_Heizkreis_3_P_effektiv "Rückmeldung der effektiven Leistung vom Heizkreis_3";
CM_ SG_ 2589283459 SCR_Heizkreis_3_P_Grenze "Gibt die aktuell verfügbare Leistung für den Heizkreis 3 an.";
CM_ SG_ 2589283459 SCR_Tankheizkreis_P_Grenze "Gibt die aktuell verfügbare Leistung für den Tankheizkreis an.";
CM_ SG_ 2589283459 SCR_Tankheizung_P_effektiv "Rückmeldung der effektiven Leistung vom Tankheizkreis";

CM_ SG_ 2589283460 SCR_DEF2_CAL_CVN_CRC_32 "CVN des zweiten Sensors. Wird für die Ausgabe an das SCAN-Tool benötigt.";
CM_ SG_ 2589283460 SCR_QBit_Temp_DEF2_Sensor "Gibt an ob das Signal SCR_Temp_DEF2_Sensor gültig ist.";
CM_ SG_ 2589283460 SCR_Temp_DEF2_Sensor "Temperatur des zweiten DEF-Sensors im SCR-Tank";

CM_ SG_ 2463978593 SCR_Dosierpumpe_Umdrehungen "Anzahl der Umdrehungen der Dosierpumpe seit letztem Startup.

Zähler fängt bei Übverlauf wieder bei Null an. Der Zähler wird sowohl bei Vorwärts als auch bei Rückwärtsbetrieb der Pumpe hochgezählt. Somit muss der Ansteuerungsmodus bei der Auswertung des";
CM_ SG_ 2463978593 SCR_QBit_Level_kurz_Aktivtank "gibt an ob das Signal 'SCR_Sent_Level_kurz_Aktivtank' gültig ist.";
CM_ SG_ 2463978593 SCR_Sent_Level_kurz_Aktivtank "Füllstand des Aktivtanks, gemessen mit dem kurzen Levelsensor für höhere Genauigkeit bei niedrigen Füllständen";

CM_ SG_ 1510 SCR_CAL_ID_Index_01 "ASCII-Zeichen erster Buchstabe des SG-Namens";
CM_ SG_ 1510 SCR_CAL_ID_Index_02 "ASCII-Zeichen zweiter Buchstabe des SG-Namens";
CM_ SG_ 1510 SCR_CAL_ID_Index_03 "ASCII-Zeichen dritter Buchstabe des SG-Namens";
CM_ SG_ 1510 SCR_CAL_ID_Index_04 "ASCII-Zeichen erster Buchstabe der letzten 3 Stellen der Software-Teilenummer";
CM_ SG_ 1510 SCR_CAL_ID_Index_05 "ASCII-Zeichen zweiter Buchstabe der letzten 3 Stellen der Software-Teilenummer";
CM_ SG_ 1510 SCR_CAL_ID_Index_06 "ASCII-Zeichen dritter Buchstabe der letzten 3 Stellen der Software-Teilenummer";
CM_ SG_ 1510 SCR_CAL_ID_Index_07 "ASCII-Zeichen Buchstabe für Hardware-Index";
CM_ SG_ 1510 SCR_CAL_ID_Index_08 "ASCII-Zeichen erster Buchstabe der vierstelligen Softwareversion";

CM_ SG_ 1512 SCR_CAL_ID_Index_09 "ASCII-Zeichen zweiter Buchstabe der vierstelligen Softwareversion";
CM_ SG_ 1512 SCR_CAL_ID_Index_10 "ASCII-Zeichen dritter Buchstabe der vierstelligen Softwareversion";
CM_ SG_ 1512 SCR_CAL_ID_Index_11 "ASCII-Zeichen vierter Buchstabe der vierstelligen Softwareversion";
CM_ SG_ 1512 SCR_CAL_ID_Index_12 "ASCII-Zeichen erster Buchstabe der zweistelligen Abgelegten Fahrzeugklasse aus dem Datensatz";
CM_ SG_ 1512 SCR_CAL_ID_Index_13 "ASCII-Zeichen zweiter Buchstabe der zweistelligen Abgelegten Fahrzeugklasse aus dem Datensatz";
CM_ SG_ 1512 SCR_CAL_ID_Index_14 "ASCII-Zeichen Reserve zur Erweiterung der OBD-relevanten Variante";
CM_ SG_ 1512 SCR_CAL_ID_Index_15 "ASCII-Zeichen erster Buchstabe der zweistelligen Datensatzversion";
CM_ SG_ 1512 SCR_CAL_ID_Index_16 "ASCII-Zeichen zweiter Buchstabe der zweistelligen Datensatzversion";

CM_ SG_ 2589283497 SCR_DEF2_CAL_ID_Index01 "Die Bytes 1 bis 4 von der 16 stelligen CALID des zweiten Sentsensors.";
CM_ SG_ 2589283497 SCR_DEF2_CAL_ID_Index02 "5 bis 8 Byte der CALID vom zweiten Sentsensor";

CM_ SG_ 2589283498 SCR_DEF2_CAL_ID_Index03 "9. bis 12. Byte der CALID vom zweiten Sentsensor";
CM_ SG_ 2589283498 SCR_DEF2_CAL_ID_Index04 "13. bis 16. Byte der CALID für den zweiten Sentsensor";

CM_ SG_ 2589283413 SCR_DEF_CAL_ID_Index01 "Major Monitor Sensoren haben eine CALID zu senden";
CM_ SG_ 2589283413 SCR_DEF_CAL_ID_Index02 "Major Monitor Sensoren haben ein CALID zu senden.";

CM_ SG_ 2589283414 SCR_DEF_CAL_ID_Index03 "Major Monitor Sensoren haben einen CALID zu senden";
CM_ SG_ 2589283414 SCR_DEF_CAL_ID_Index04 "Major Monitor Sensoren haben einen CALID zu senden";

CM_ SG_ 980 BH_Blinker_Fehler "Anzeige, ob am Lenkstockschalter ein Fehler anliegt.
Notwendig aufgrund ASIL-Einstufung";
CM_ SG_ 980 BH_Blinker_li "Blinkerhebel Richtung links
";
CM_ SG_ 980 BH_Blinker_re "Blinkerhebel Richtung rechts
";
CM_ SG_ 980 BH_Fernlicht "Betaetigung Fernlicht
";
CM_ SG_ 980 BH_Lichthupe "Betaetigung Lichthupe
";
CM_ SG_ 980 FAS_Taster "Betaetigung FAS Taster
";
CM_ SG_ 980 FAS_Taster_Fehler "Fehlerstatus FAS Taster
";
CM_ SG_ 980 LRH_aktiv "Signal gibt an, ob ein Heizstrom durch die Lenkradheizung fließt. Es dient der Auswertung durch das Energiemanagement.";
CM_ SG_ 980 LRH_on_off "Status Lenkradheizung";
CM_ SG_ 980 SMLS_01_BZ "4bit Botschaftszaehler, wird mit jeder Sendebotschaft inkrementiert";
CM_ SG_ 980 SMLS_01_CRC "Für MLB:
'Berechnung siehe Lastenheft 'Kommunikationsabsicherung für FlexRay und CAN''

Ab MQB und MLBevo:
'Berechnung siehe Lastenheft 'End-to-End Kommunikationsabsicherung''

Endwerte siehe Begleitdokument 'S-PDU Kennungsfolgen'";
CM_ SG_ 980 SMLS_Hupe "Betaetigung Hupe
";
CM_ SG_ 980 SMLS_P_verriegelt_plausibel "Signal stellt den Plausibilisierungstatus des Signals p_verriegelt auf den Fahrzeugbus zur Verfügung. Eine Plausibilität muss explizit erkannt werden. Initial wird 'unplausibel' gesendet. Ein plausibles Signal wird erkannt, wenn p_verriegelt plausibel geg";
CM_ SG_ 980 SMLS_PTT "Betaetigung PTT";
CM_ SG_ 980 WH_Frontwaschen "Wischerhebel: Stellung Wisch Wasch vorne
";
CM_ SG_ 980 WH_Heckintervall "Wischerhebel: Stellung Heckintervall
";
CM_ SG_ 980 WH_Heckwaschen "Wischerhebel: Stellung Wisch Wasch hinten
";
CM_ SG_ 980 WH_Intervall "Wischerhebel: Stellung Intervall
";
CM_ SG_ 980 WH_Intervallstufen "Wischerhebel: Stellung Intervallstufen";
CM_ SG_ 980 WH_SRA "Scheinwerferreinigungsanlage

derzeit nur bei PAG umgesetzt";
CM_ SG_ 980 WH_Tipwischen "Wischerhebel: Tippwischen

MQB A0/ PQ26: Bei Verbau LSS (kein SMLS): gespiegelter Wert zu Signal WH_WischerStufe1";
CM_ SG_ 980 WH_Tipwischen_lang "Wischerhebel: Tippwischen lang
(dient zur Auswertung für die Unterscheidung Tippwischen oder Serviceposition Wischer)";
CM_ SG_ 980 WH_Wischer_Fehler "Anzeige, ob am Lenkstockschalter ein Fehler anliegt.
Notwendig aufgrund ASIL-Einstufung";
CM_ SG_ 980 WH_WischerStufe1 "Wischerhebel: Stufe Wischen 1
";
CM_ SG_ 980 WH_WischerStufe2 "Wischerhebel: Stufe Wischen 2
";

CM_ SG_ 1710 SP_abklappen "Spiegel abklappen";
CM_ SG_ 1710 SP_anklappen "Spiegel anklappen";
CM_ SG_ 1710 SP_ARA_Status "Rückkanal TSG im ARA-Modus";
CM_ SG_ 1710 SP_Auswahl_li "Spiegelschalter in Stellung Auswahl links";
CM_ SG_ 1710 SP_Auswahl_re "Spiegelschalter in Stellung Auswahl rechts";
CM_ SG_ 1710 SP_BT_links "Spiegel Beifahrertür nach links";
CM_ SG_ 1710 SP_BT_oben "Spiegel Beifahrertür nach oben";
CM_ SG_ 1710 SP_BT_rechts "Spiegel Beifahrertür nach rechts";
CM_ SG_ 1710 SP_BT_unten "Spiegel Beifahrertür nach unten";
CM_ SG_ 1710 SP_FT_links "Spiegel Fahrertür nach links";
CM_ SG_ 1710 SP_FT_oben "Spiegel Fahrertür nach oben";
CM_ SG_ 1710 SP_FT_rechts "Spiegel Fahrertür nach rechts";
CM_ SG_ 1710 SP_FT_unten "Spiegel Fahrertür nach unten";
CM_ SG_ 1710 SP_Hzg_Taster "Heizungstaster/schalter aktiv";
CM_ SG_ 1710 SP_normieren "Spiegel normieren";
CM_ SG_ 1710 SP_S_Klappen "Spiegelschalter in Stellung Klappen";
CM_ SG_ 1710 SP_S_links "Spiegelschalter in Stellung links";
CM_ SG_ 1710 SP_S_oben "Spiegelschalter in Stellung oben";
CM_ SG_ 1710 SP_S_rechts "Spiegelschalter in Stellung rechts";
CM_ SG_ 1710 SP_S_unten "Spiegelschalter in Stellung unten";
CM_ SG_ 1710 SP_Verstellschalter_Fehler "Erkennung eines hängenden Spiegelverstellschalters";

CM_ SG_ 1313 STH_EKP_Anst "STH sendet die Anforderung zur Ansteuerung der EKP an den Motor, um Kraftstoffbehälter der STH zu befüllen.";
CM_ SG_ 1313 STH_Fehler_ElWaPu "Fehler der el. Zusatzwasserpumpe der zur Deaktivierung der Wasserpumpe führt ";
CM_ SG_ 1313 STH_Fehlerstatus "Übermittlung der unterschiedlichen Fehlerzustände der Standheizung";
CM_ SG_ 1313 STH_Heizleistung "Heizleistung in %";
CM_ SG_ 1313 STH_KL_HUP "Signal HUP Aktivierung an Klima

0 = HUP aus
1 = HUP ein";
CM_ SG_ 1313 STH_KVS "Kraftstoffverbrauch";
CM_ SG_ 1313 STH_LED "Funktionslampe";
CM_ SG_ 1313 STH_Motorvorwaermung "Info an der Motor, dass der Aufheizvorgang mit Motorvorwärmung erfolgt ist";
CM_ SG_ 1313 STH_Pumpen_Anf_extern "Anforderung der motorseitigen elektr. (externen) Wasserpumpe zur Kreislaufunterstützung im Standheizbetrieb";
CM_ SG_ 1313 STH_SH_ZH "0 = Heizgerät ist Standheizung
1 = Heizgerät ist Zuheizer
Gerätekennung WZH oder ZH
";
CM_ SG_ 1313 STH_Start_folgt "Thema Start/Stop: Im Stop-Modus muß das KBT einen Wiederstart anfordern, da ein STH-Start notwendig ist.";
CM_ SG_ 1313 STH_Texte "Anforderung der unterschiedlichen Anzeigetexte im Mitteldisplay des Kombi.

0: Keine Anzeige
1: Kein Standheizungs- bzw Lueftungsbetrieb wegen Batteriemanagementeinschraenkung
2: Kein Standheizungs- bzw Lueftungsbetrieb wegen Kraftstoffmangels
3: Kei";
CM_ SG_ 1313 STH_Ventil_Status "Statusrückmeldung Ansteuerung 3/2 Wege-Ventil";
CM_ SG_ 1313 STH_Ventiloeffnungszeit "Die Standheizung sendet an den Motor die Information darüber wie lange das Magnetventil die Wasserkreisläufe von 'klein' aus 'gross' geschaltet hat. ";
CM_ SG_ 1313 STH_Waermeeintrag "Signal enthält die Brenndauer in 1min-Schritten, über welche die Standheizung gelaufen ist";
CM_ SG_ 1313 STH_war_aktiv "Bit beeinhaltet die Info, dass die Standheizung während der letzten halbe Stunde aktiv war.";
BA_DEF_REL_ BU_SG_REL_  "GenSigTimeoutTime" INT 0 65535;
BA_DEF_ BO_  "DiagRequest" ENUM "No", "Yes";
BA_DEF_ BO_  "DiagResponse" ENUM "No", "Yes";
BA_DEF_ BO_  "DiagState" ENUM "No", "Yes";
BA_DEF_ BO_  "GenMsgChkConstant" HEX 0 4095;
BA_DEF_ BO_  "GenMsgCycleTime" INT 0 65535;
BA_DEF_ BO_  "GenMsgCycleTimeFast" INT 0 65535;
BA_DEF_ BO_  "GenMsgDelayTime" INT 0 100000;
BA_DEF_ BO_  "GenMsgILSupport" ENUM "No", "Yes";
BA_DEF_ BO_  "GenMsgNrOfRepetition" INT 0 100;
BA_DEF_ BO_  "GenMsgPDUConstants" STRING;
BA_DEF_ BO_  "GenMsgSendType" ENUM "Cyclic", "not_used", "not_used", "not_used", "not_used", "not_used", "not_used", "IfActive", "NoMsgSendType";
BA_DEF_ BO_  "GenMsgStartDelayTime" INT 0 100000;
BA_DEF_ BO_  "NmMessage" ENUM "No", "Yes";
BA_DEF_ BO_  "NmhMessage" ENUM "No", "Yes";
BA_DEF_ BO_  "MsgType" ENUM "Application", "NM ", "NMH", "TP2.0", "ISO-TP ", "BAP", "EID", "KS";
BA_DEF_ BO_  "VAGTP20_API" HEX 0 255;
BA_DEF_ BO_  "VAGTP20_DynConnection" ENUM "No", "Yes";
BA_DEF_ BO_  "VAGTP20_DynSetup" ENUM "No", "Yes";
BA_DEF_ BO_  "VAGTP20_StatConnection" ENUM "No", "Yes";
BA_DEF_ SG_  "GenSigActiveRepetitions" INT -2147483648 2147483647;
BA_DEF_ SG_  "GenSigInactiveValue" INT -2147483648 2147483647;
BA_DEF_ SG_  "GenSigSendType" ENUM "Cyclic", "OnWrite", "OnWriteWithRepetition", "OnChange", "OnChangeWithRepetition", "IfActive", "IfActiveWithRepetition", "NoSigSendType", "OnChangeAndIfActive", "OnChangeAndIfActiveWithRepetition";
BA_DEF_ SG_  "GenSigStartValue" INT -2147483648 2147483647;
BA_DEF_ SG_  "NWM-WakeupAllowed" ENUM "No", "Yes";
BA_DEF_ SG_  "GenSigFuncType" ENUM "NoFunction", "MsgCounter", "CRC-8", "XOR", "XOR-2", "DatedBit", "SW-Kl15", "CHK", "Constant", "Protocol", "CRC-8-SAE_J1850";
BA_DEF_ SG_  "GenSigSwitchedByIgnition" ENUM "No", "Yes";
BA_DEF_ SG_  "Fehlerwert" HEX 0 2147483647;
BA_DEF_ SG_  "GenSigMissingSourceValue" HEX 0 2147483647;
BA_DEF_DEF_REL_  "GenSigTimeoutTime" 0;
BA_DEF_DEF_  "DiagRequest" "No";
BA_DEF_DEF_  "DiagResponse" "No";
BA_DEF_DEF_  "DiagState" "No";
BA_DEF_DEF_  "GenMsgChkConstant" 0;
BA_DEF_DEF_  "GenMsgCycleTime" 0;
BA_DEF_DEF_  "GenMsgCycleTimeFast" 0;
BA_DEF_DEF_  "GenMsgDelayTime" 0;
BA_DEF_DEF_  "GenMsgILSupport" "No";
BA_DEF_DEF_  "GenMsgNrOfRepetition" 0;
BA_DEF_DEF_  "GenMsgPDUConstants" "";
BA_DEF_DEF_  "GenMsgSendType" "NoMsgSendType";
BA_DEF_DEF_  "GenMsgStartDelayTime" 0;
BA_DEF_DEF_  "NmMessage" "No";
BA_DEF_DEF_  "NmhMessage" "No";
BA_DEF_DEF_  "MsgType" "Application";
BA_DEF_DEF_  "VAGTP20_API" 0;
BA_DEF_DEF_  "VAGTP20_DynConnection" "No";
BA_DEF_DEF_  "VAGTP20_DynSetup" "No";
BA_DEF_DEF_  "VAGTP20_StatConnection" "No";
BA_DEF_DEF_  "GenSigActiveRepetitions" 0;
BA_DEF_DEF_  "GenSigInactiveValue" 0;
BA_DEF_DEF_  "GenSigSendType" "NoSigSendType";
BA_DEF_DEF_  "GenSigStartValue" 0;
BA_DEF_DEF_  "NWM-WakeupAllowed" "No";
BA_DEF_DEF_  "GenSigFuncType" "NoFunction";
BA_DEF_DEF_  "GenSigSwitchedByIgnition" "Yes";
BA_DEF_DEF_  "Fehlerwert" 0;
BA_DEF_DEF_  "GenSigMissingSourceValue" 0;
BA_ "GenMsgCycleTime" BO_ 1355 500;
BA_ "GenMsgDelayTime" BO_ 1355 20;
BA_ "GenMsgILSupport" BO_ 1355 1;
BA_ "GenMsgSendType" BO_ 1355 0;
BA_ "GenMsgCycleTime" BO_ 2527679498 1000;
BA_ "GenMsgCycleTimeFast" BO_ 2527679498 200;
BA_ "GenMsgDelayTime" BO_ 2527679498 50;
BA_ "GenMsgILSupport" BO_ 2527679498 1;
BA_ "GenMsgNrOfRepetition" BO_ 2527679498 3;
BA_ "GenMsgSendType" BO_ 2527679498 0;
BA_ "GenMsgCycleTime" BO_ 319 200;
BA_ "GenMsgDelayTime" BO_ 319 20;
BA_ "GenMsgILSupport" BO_ 319 1;
BA_ "GenMsgPDUConstants" BO_ 319 "0x28,0x6e,0x5a,0xc6,0x52,0x65,0x85,0xa1,0xb8,0xe6,0x38,0x88,0xf8,0xb9,0x2b,0xb0";
BA_ "GenMsgSendType" BO_ 319 0;
BA_ "GenMsgCycleTime" BO_ 1122 150;
BA_ "GenMsgILSupport" BO_ 1122 1;
BA_ "GenMsgSendType" BO_ 1122 0;
BA_ "GenMsgCycleTime" BO_ 1123 150;
BA_ "GenMsgILSupport" BO_ 1123 1;
BA_ "GenMsgSendType" BO_ 1123 0;
BA_ "GenMsgCycleTime" BO_ 1124 150;
BA_ "GenMsgILSupport" BO_ 1124 1;
BA_ "GenMsgSendType" BO_ 1124 0;
BA_ "GenMsgCycleTime" BO_ 1529 320;
BA_ "GenMsgILSupport" BO_ 1529 1;
BA_ "GenMsgSendType" BO_ 1529 0;
BA_ "GenMsgCycleTime" BO_ 2589283632 800;
BA_ "GenMsgILSupport" BO_ 2589283632 1;
BA_ "GenMsgSendType" BO_ 2589283632 0;
BA_ "GenMsgCycleTime" BO_ 1651 800;
BA_ "GenMsgILSupport" BO_ 1651 1;
BA_ "GenMsgSendType" BO_ 1651 0;
BA_ "GenMsgCycleTime" BO_ 1711 1000;
BA_ "GenMsgDelayTime" BO_ 1711 100;
BA_ "GenMsgILSupport" BO_ 1711 1;
BA_ "GenMsgSendType" BO_ 1711 0;
BA_ "GenMsgCycleTime" BO_ 1440 200;
BA_ "GenMsgILSupport" BO_ 1440 1;
BA_ "GenMsgSendType" BO_ 1440 0;
BA_ "GenMsgCycleTime" BO_ 1528 1000;
BA_ "GenMsgDelayTime" BO_ 1528 100;
BA_ "GenMsgILSupport" BO_ 1528 1;
BA_ "GenMsgSendType" BO_ 1528 0;
BA_ "GenMsgCycleTime" BO_ 424 20;
BA_ "GenMsgILSupport" BO_ 424 1;
BA_ "GenMsgPDUConstants" BO_ 424 "0x11,0x17,0xbb,0xaa,0xd0,0x83,0xe1,0x8e,0xa3,0x4d,0xef,0x50,0x88,0xa5,0x22,0xf6";
BA_ "GenMsgSendType" BO_ 424 0;
BA_ "GenMsgCycleTime" BO_ 1011 100;
BA_ "GenMsgILSupport" BO_ 1011 1;
BA_ "GenMsgSendType" BO_ 1011 0;
BA_ "GenMsgCycleTime" BO_ 1507 500;
BA_ "GenMsgILSupport" BO_ 1507 1;
BA_ "GenMsgSendType" BO_ 1507 0;
BA_ "GenMsgCycleTime" BO_ 1508 500;
BA_ "GenMsgDelayTime" BO_ 1508 50;
BA_ "GenMsgILSupport" BO_ 1508 1;
BA_ "GenMsgSendType" BO_ 1508 0;
BA_ "GenMsgCycleTime" BO_ 1509 1000;
BA_ "GenMsgILSupport" BO_ 1509 1;
BA_ "GenMsgSendType" BO_ 1509 0;
BA_ "GenMsgCycleTime" BO_ 1526 500;
BA_ "GenMsgDelayTime" BO_ 1526 50;
BA_ "GenMsgILSupport" BO_ 1526 1;
BA_ "GenMsgSendType" BO_ 1526 0;
BA_ "GenMsgCycleTime" BO_ 2527679503 500;
BA_ "GenMsgILSupport" BO_ 2527679503 1;
BA_ "GenMsgSendType" BO_ 2527679503 0;
BA_ "GenMsgCycleTime" BO_ 2589283459 500;
BA_ "GenMsgILSupport" BO_ 2589283459 1;
BA_ "GenMsgSendType" BO_ 2589283459 0;
BA_ "GenMsgCycleTime" BO_ 2589283460 500;
BA_ "GenMsgILSupport" BO_ 2589283460 1;
BA_ "GenMsgSendType" BO_ 2589283460 0;
BA_ "GenMsgCycleTime" BO_ 2463978593 100;
BA_ "GenMsgILSupport" BO_ 2463978593 1;
BA_ "GenMsgSendType" BO_ 2463978593 0;
BA_ "GenMsgCycleTime" BO_ 1510 1000;
BA_ "GenMsgILSupport" BO_ 1510 1;
BA_ "GenMsgSendType" BO_ 1510 0;
BA_ "GenMsgCycleTime" BO_ 1512 1000;
BA_ "GenMsgILSupport" BO_ 1512 1;
BA_ "GenMsgSendType" BO_ 1512 0;
BA_ "GenMsgCycleTime" BO_ 2589283497 500;
BA_ "GenMsgILSupport" BO_ 2589283497 1;
BA_ "GenMsgSendType" BO_ 2589283497 0;
BA_ "GenMsgCycleTime" BO_ 2589283498 500;
BA_ "GenMsgILSupport" BO_ 2589283498 1;
BA_ "GenMsgSendType" BO_ 2589283498 0;
BA_ "GenMsgCycleTime" BO_ 2589283413 500;
BA_ "GenMsgILSupport" BO_ 2589283413 1;
BA_ "GenMsgSendType" BO_ 2589283413 0;
BA_ "GenMsgCycleTime" BO_ 2589283414 500;
BA_ "GenMsgILSupport" BO_ 2589283414 1;
BA_ "GenMsgSendType" BO_ 2589283414 0;
BA_ "GenMsgCycleTime" BO_ 980 200;
BA_ "GenMsgCycleTimeFast" BO_ 980 80;
BA_ "GenMsgDelayTime" BO_ 980 40;
BA_ "GenMsgILSupport" BO_ 980 1;
BA_ "GenMsgNrOfRepetition" BO_ 980 5;
BA_ "GenMsgPDUConstants" BO_ 980 "0xc3,0x79,0xbf,0xdb,0xe9,0x11,0x46,0x86,0x69,0xb6,0x9b,0x29,0x15,0x9c,0x45,0x0d";
BA_ "GenMsgSendType" BO_ 980 0;
BA_ "GenMsgCycleTime" BO_ 1710 1000;
BA_ "GenMsgCycleTimeFast" BO_ 1710 100;
BA_ "GenMsgDelayTime" BO_ 1710 50;
BA_ "GenMsgILSupport" BO_ 1710 1;
BA_ "GenMsgNrOfRepetition" BO_ 1710 5;
BA_ "GenMsgSendType" BO_ 1710 0;
BA_ "GenMsgCycleTime" BO_ 1313 200;
BA_ "GenMsgILSupport" BO_ 1313 1;
BA_ "GenMsgSendType" BO_ 1313 0;
BA_ "GenSigSendType" SG_ 1355 BCM_WAH_Meldung 3;
BA_ "GenSigSendType" SG_ 1355 PDC_Charisma_FahrPr 3;
BA_ "GenSigSendType" SG_ 1355 PDC_Charisma_Status 3;
BA_ "GenSigSendType" SG_ 1355 PH_Aufschaltursache 3;
BA_ "GenSigSendType" SG_ 1355 PH_Ton_Ausgabe 3;
BA_ "Fehlerwert" SG_ 1355 PH_Ton_Ausgabe 7;
BA_ "GenSigSendType" SG_ 1355 PH_Ton_Lautstaerke 3;
BA_ "GenSigSendType" SG_ 1355 PH_Ton_Pausenlaenge 3;
BA_ "Fehlerwert" SG_ 1355 PH_Ton_Pausenlaenge 127;
BA_ "GenSigSendType" SG_ 1355 PH_Ton_Richtung 3;
BA_ "GenSigSendType" SG_ 1355 PH_Verschmutzungsmeldung 3;
BA_ "GenSigSendType" SG_ 2527679498 IAA_Active_User_ID 0;
BA_ "GenSigSwitchedByIgnition" SG_ 2527679498 IAA_Active_User_ID 0;
BA_ "GenSigSendType" SG_ 2527679498 IAA_Identified_User_ID 0;
BA_ "GenSigSwitchedByIgnition" SG_ 2527679498 IAA_Identified_User_ID 0;
BA_ "GenSigSendType" SG_ 2527679498 IAA_PSO_wake_up 0;
BA_ "GenSigSwitchedByIgnition" SG_ 2527679498 IAA_PSO_wake_up 0;
BA_ "GenSigActiveRepetitions" SG_ 2527679498 Perso_Aktiv 3;
BA_ "GenSigSendType" SG_ 2527679498 Perso_Aktiv 4;
BA_ "GenSigSwitchedByIgnition" SG_ 2527679498 Perso_Aktiv 0;
BA_ "GenSigActiveRepetitions" SG_ 2527679498 Perso_Bedienstelle 3;
BA_ "GenSigSendType" SG_ 2527679498 Perso_Bedienstelle 4;
BA_ "GenSigSwitchedByIgnition" SG_ 2527679498 Perso_Bedienstelle 0;
BA_ "GenSigActiveRepetitions" SG_ 2527679498 Perso_Fahrernummer 3;
BA_ "GenSigSendType" SG_ 2527679498 Perso_Fahrernummer 4;
BA_ "GenSigSwitchedByIgnition" SG_ 2527679498 Perso_Fahrernummer 0;
BA_ "GenSigActiveRepetitions" SG_ 2527679498 Perso_Freigabe_Verstellung 3;
BA_ "GenSigSendType" SG_ 2527679498 Perso_Freigabe_Verstellung 4;
BA_ "GenSigSwitchedByIgnition" SG_ 2527679498 Perso_Freigabe_Verstellung 0;
BA_ "GenSigActiveRepetitions" SG_ 2527679498 Perso_Kontonummer 3;
BA_ "GenSigSendType" SG_ 2527679498 Perso_Kontonummer 4;
BA_ "GenSigSwitchedByIgnition" SG_ 2527679498 Perso_Kontonummer 0;
BA_ "GenSigActiveRepetitions" SG_ 2527679498 Perso_Schreibschutz 3;
BA_ "GenSigSendType" SG_ 2527679498 Perso_Schreibschutz 4;
BA_ "GenSigSwitchedByIgnition" SG_ 2527679498 Perso_Schreibschutz 0;
BA_ "GenSigSendType" SG_ 2527679498 Perso_Status 1;
BA_ "GenSigSwitchedByIgnition" SG_ 2527679498 Perso_Status 0;
BA_ "GenSigActiveRepetitions" SG_ 2527679498 Perso_Steuerung 3;
BA_ "GenSigSendType" SG_ 2527679498 Perso_Steuerung 4;
BA_ "GenSigSwitchedByIgnition" SG_ 2527679498 Perso_Steuerung 0;
BA_ "GenSigActiveRepetitions" SG_ 2527679498 Perso_Steuerungsparameter 3;
BA_ "GenSigSendType" SG_ 2527679498 Perso_Steuerungsparameter 4;
BA_ "GenSigSwitchedByIgnition" SG_ 2527679498 Perso_Steuerungsparameter 0;
BA_ "GenSigSendType" SG_ 319 PreCrash_02_BZ 0;
BA_ "GenSigFuncType" SG_ 319 PreCrash_02_BZ 1;
BA_ "GenSigSendType" SG_ 319 PreCrash_02_CRC 0;
BA_ "GenSigFuncType" SG_ 319 PreCrash_02_CRC 2;
BA_ "GenSigSendType" SG_ 319 PreCrash_Anforderung_AFR 3;
BA_ "GenSigStartValue" SG_ 319 PreCrash_Anforderung_AFR 7;
BA_ "GenSigSwitchedByIgnition" SG_ 319 PreCrash_Anforderung_AFR 0;
BA_ "GenSigSendType" SG_ 319 PreCrash_BFS_KSV_verfahren 3;
BA_ "GenSigSwitchedByIgnition" SG_ 319 PreCrash_BFS_KSV_verfahren 0;
BA_ "GenSigSendType" SG_ 319 PreCrash_BFS_Pneumatik_ansteuern 3;
BA_ "GenSigSwitchedByIgnition" SG_ 319 PreCrash_BFS_Pneumatik_ansteuern 0;
BA_ "GenSigSendType" SG_ 319 PreCrash_BFS_Sitzlehne_verfahren 3;
BA_ "GenSigSwitchedByIgnition" SG_ 319 PreCrash_BFS_Sitzlehne_verfahren 0;
BA_ "GenSigSendType" SG_ 319 PreCrash_Blinken 3;
BA_ "GenSigSendType" SG_ 319 PreCrash_Charisma_FahrPr 0;
BA_ "GenSigSendType" SG_ 319 PreCrash_Charisma_Status 0;
BA_ "GenSigSendType" SG_ 319 PreCrash_Fenster_schliessen 3;
BA_ "GenSigSendType" SG_ 319 PreCrash_Fo_KSV_verfahren 3;
BA_ "GenSigSwitchedByIgnition" SG_ 319 PreCrash_Fo_KSV_verfahren 0;
BA_ "GenSigSendType" SG_ 319 PreCrash_Fo_Pneumatik_ansteuern 3;
BA_ "GenSigSwitchedByIgnition" SG_ 319 PreCrash_Fo_Pneumatik_ansteuern 0;
BA_ "GenSigSendType" SG_ 319 PreCrash_Fo_Sitzlehne_verfahren 3;
BA_ "GenSigSwitchedByIgnition" SG_ 319 PreCrash_Fo_Sitzlehne_verfahren 0;
BA_ "GenSigSendType" SG_ 319 PreCrash_FS_KSV_verfahren 3;
BA_ "GenSigSwitchedByIgnition" SG_ 319 PreCrash_FS_KSV_verfahren 0;
BA_ "GenSigSendType" SG_ 319 PreCrash_FS_Pneumatik_ansteuern 3;
BA_ "GenSigSwitchedByIgnition" SG_ 319 PreCrash_FS_Pneumatik_ansteuern 0;
BA_ "GenSigSendType" SG_ 319 PreCrash_FS_Sitzlehne_verfahren 3;
BA_ "GenSigSwitchedByIgnition" SG_ 319 PreCrash_FS_Sitzlehne_verfahren 0;
BA_ "GenSigSendType" SG_ 319 PreCrash_Schiebedach_schliessen 3;
BA_ "GenSigSendType" SG_ 319 PreCrash_Tueren_Verriegeln 3;
BA_ "GenSigSwitchedByIgnition" SG_ 319 PreCrash_Tueren_Verriegeln 0;
BA_ "GenSigSendType" SG_ 319 SC_PreCrash_LED 3;
BA_ "GenSigSwitchedByIgnition" SG_ 319 SC_PreCrash_LED 0;
BA_ "GenSigSendType" SG_ 319 SC_PreCrash_Texte 3;
BA_ "GenSigSwitchedByIgnition" SG_ 319 SC_PreCrash_Texte 0;
BA_ "GenSigSendType" SG_ 319 SC_PreCrash_Warnung 3;
BA_ "GenSigSwitchedByIgnition" SG_ 319 SC_PreCrash_Warnung 0;
BA_ "GenSigSendType" SG_ 319 SC_PreSense_FCWP 3;
BA_ "GenSigSwitchedByIgnition" SG_ 319 SC_PreSense_FCWP 0;
BA_ "GenSigSendType" SG_ 1122 PSD_Abzweigerichtung 0;
BA_ "GenSigSwitchedByIgnition" SG_ 1122 PSD_Abzweigerichtung 0;
BA_ "GenSigSendType" SG_ 1122 PSD_Abzweigewinkel 0;
BA_ "GenSigSwitchedByIgnition" SG_ 1122 PSD_Abzweigewinkel 0;
BA_ "GenSigSendType" SG_ 1122 PSD_ADAS_Qualitaet 0;
BA_ "GenSigSendType" SG_ 1122 PSD_Anfangskruemmung 0;
BA_ "GenSigSwitchedByIgnition" SG_ 1122 PSD_Anfangskruemmung 0;
BA_ "GenSigSendType" SG_ 1122 PSD_Anfangskruemmung_Vorz 0;
BA_ "GenSigSwitchedByIgnition" SG_ 1122 PSD_Anfangskruemmung_Vorz 0;
BA_ "GenSigSendType" SG_ 1122 PSD_Bebauung 0;
BA_ "GenSigSendType" SG_ 1122 PSD_Endkruemmung 0;
BA_ "GenSigSendType" SG_ 1122 PSD_Endkruemmung_Vorz 0;
BA_ "GenSigSendType" SG_ 1122 PSD_Fahrspuren_Anzahl 0;
BA_ "GenSigStartValue" SG_ 1122 PSD_Fahrspuren_Anzahl 1;
BA_ "GenSigSwitchedByIgnition" SG_ 1122 PSD_Fahrspuren_Anzahl 0;
BA_ "GenSigSendType" SG_ 1122 PSD_Geradester_Pfad 0;
BA_ "GenSigSendType" SG_ 1122 PSD_Idenditaets_ID 0;
BA_ "Fehlerwert" SG_ 1122 PSD_Idenditaets_ID 1;
BA_ "GenSigSendType" SG_ 1122 PSD_Rampe 0;
BA_ "GenSigSendType" SG_ 1122 PSD_Segment_ID 0;
BA_ "GenSigSendType" SG_ 1122 PSD_Segment_Komplett 0;
BA_ "GenSigSwitchedByIgnition" SG_ 1122 PSD_Segment_Komplett 0;
BA_ "GenSigSendType" SG_ 1122 PSD_Segmentlaenge 0;
BA_ "GenSigSendType" SG_ 1122 PSD_Strassenkategorie 0;
BA_ "GenSigStartValue" SG_ 1122 PSD_Strassenkategorie 7;
BA_ "GenSigSwitchedByIgnition" SG_ 1122 PSD_Strassenkategorie 0;
BA_ "GenSigSendType" SG_ 1122 PSD_Vorgaenger_Segment_ID 0;
BA_ "GenSigSendType" SG_ 1122 PSD_wahrscheinlichster_Pfad 0;
BA_ "GenSigSendType" SG_ 1123 PSD_Attribut_1_ID 0;
BA_ "GenSigSendType" SG_ 1123 PSD_Attribut_1_Offset 0;
BA_ "GenSigSendType" SG_ 1123 PSD_Attribut_1_Wert 0;
BA_ "GenSigSendType" SG_ 1123 PSD_Attribut_2_ID 0;
BA_ "GenSigSendType" SG_ 1123 PSD_Attribut_2_Offset 0;
BA_ "GenSigSendType" SG_ 1123 PSD_Attribut_2_Wert 0;
BA_ "GenSigSendType" SG_ 1123 PSD_Attribut_Segment_ID_05 0;
BA_ "Fehlerwert" SG_ 1123 PSD_Attribut_Segment_ID_05 1;
BA_ "GenSigSendType" SG_ 1123 PSD_Attribute_Komplett_05 0;
BA_ "GenSigSendType" SG_ 1123 PSD_Pos_Fahrspur 0;
BA_ "GenSigSendType" SG_ 1123 PSD_Pos_Fehler_Laengsrichtung 0;
BA_ "GenSigSendType" SG_ 1123 PSD_Pos_Inhibitzeit 0;
BA_ "GenSigSendType" SG_ 1123 PSD_Pos_Segment_ID 0;
BA_ "GenSigSendType" SG_ 1123 PSD_Pos_Segmentlaenge 0;
BA_ "GenSigSendType" SG_ 1123 PSD_Pos_Standort_Eindeutig 0;
BA_ "GenSigSwitchedByIgnition" SG_ 1123 PSD_Pos_Standort_Eindeutig 0;
BA_ "GenSigSendType" SG_ 1124 PSD_06_Mux 0;
BA_ "NWM-WakeupAllowed" SG_ 1124 PSD_06_Mux 1;
BA_ "GenSigSwitchedByIgnition" SG_ 1124 PSD_06_Mux 0;
BA_ "Fehlerwert" SG_ 1124 PSD_Attribut_Segment_ID 1;
BA_ "GenSigSwitchedByIgnition" SG_ 1124 PSD_Attribute_Komplett_06 0;
BA_ "GenSigStartValue" SG_ 1124 PSD_Ges_Typ 3;
BA_ "GenSigSwitchedByIgnition" SG_ 1124 PSD_Ges_Typ 0;
BA_ "GenSigSwitchedByIgnition" SG_ 1124 PSD_Steigung_1_Attribute_kompl 0;
BA_ "Fehlerwert" SG_ 1124 PSD_Steigung_1_Segment_ID 1;
BA_ "GenSigSwitchedByIgnition" SG_ 1124 PSD_Steigung_2_Attribute_kompl 0;
BA_ "Fehlerwert" SG_ 1124 PSD_Steigung_2_Segment_ID 1;
BA_ "GenSigSendType" SG_ 1529 RDK_FMVSS138_Lampe 0;
BA_ "GenSigSwitchedByIgnition" SG_ 1529 RDK_FMVSS138_Lampe 0;
BA_ "GenSigSendType" SG_ 1529 RDK_FMVSS138_MIL 0;
BA_ "GenSigSwitchedByIgnition" SG_ 1529 RDK_FMVSS138_MIL 0;
BA_ "GenSigSendType" SG_ 1529 RDK_Kalibrierung 0;
BA_ "GenSigSwitchedByIgnition" SG_ 1529 RDK_Kalibrierung 0;
BA_ "GenSigSendType" SG_ 1529 RDK_Reifendruck_Lampe 0;
BA_ "GenSigSwitchedByIgnition" SG_ 1529 RDK_Reifendruck_Lampe 0;
BA_ "GenSigSendType" SG_ 1529 RDK_Reifentemperatur_Lampe 0;
BA_ "GenSigSwitchedByIgnition" SG_ 1529 RDK_Reifentemperatur_Lampe 0;
BA_ "GenSigSendType" SG_ 1529 RDK_W_1_Reifen_HL 0;
BA_ "GenSigSwitchedByIgnition" SG_ 1529 RDK_W_1_Reifen_HL 0;
BA_ "GenSigSendType" SG_ 1529 RDK_W_1_Reifen_HR 0;
BA_ "GenSigSwitchedByIgnition" SG_ 1529 RDK_W_1_Reifen_HR 0;
BA_ "GenSigSendType" SG_ 1529 RDK_W_1_Reifen_VL 0;
BA_ "GenSigSwitchedByIgnition" SG_ 1529 RDK_W_1_Reifen_VL 0;
BA_ "GenSigSendType" SG_ 1529 RDK_W_1_Reifen_VR 0;
BA_ "GenSigSwitchedByIgnition" SG_ 1529 RDK_W_1_Reifen_VR 0;
BA_ "GenSigSendType" SG_ 1529 RDK_W_2_Reifen_HL 0;
BA_ "GenSigSwitchedByIgnition" SG_ 1529 RDK_W_2_Reifen_HL 0;
BA_ "GenSigSendType" SG_ 1529 RDK_W_2_Reifen_HR 0;
BA_ "GenSigSwitchedByIgnition" SG_ 1529 RDK_W_2_Reifen_HR 0;
BA_ "GenSigSendType" SG_ 1529 RDK_W_2_Reifen_VL 0;
BA_ "GenSigSwitchedByIgnition" SG_ 1529 RDK_W_2_Reifen_VL 0;
BA_ "GenSigSendType" SG_ 1529 RDK_W_2_Reifen_VR 0;
BA_ "GenSigSwitchedByIgnition" SG_ 1529 RDK_W_2_Reifen_VR 0;
BA_ "GenSigSendType" SG_ 1529 RDK_Warnungen_02 0;
BA_ "GenSigSwitchedByIgnition" SG_ 1529 RDK_Warnungen_02 0;
BA_ "GenSigSendType" SG_ 2589283632 RDK_Diff_Druck_HL 0;
BA_ "GenSigSwitchedByIgnition" SG_ 2589283632 RDK_Diff_Druck_HL 0;
BA_ "GenSigSendType" SG_ 2589283632 RDK_Diff_Druck_HR 0;
BA_ "GenSigSwitchedByIgnition" SG_ 2589283632 RDK_Diff_Druck_HR 0;
BA_ "GenSigSendType" SG_ 2589283632 RDK_Diff_Druck_VL 0;
BA_ "GenSigSwitchedByIgnition" SG_ 2589283632 RDK_Diff_Druck_VL 0;
BA_ "GenSigSendType" SG_ 2589283632 RDK_Diff_Druck_VR 0;
BA_ "GenSigSwitchedByIgnition" SG_ 2589283632 RDK_Diff_Druck_VR 0;
BA_ "GenSigSendType" SG_ 2589283632 RDK_Reifengroesse 0;
BA_ "GenSigSwitchedByIgnition" SG_ 2589283632 RDK_Reifengroesse 0;
BA_ "GenSigSendType" SG_ 2589283632 RDK_Reifentyp 0;
BA_ "GenSigSendType" SG_ 2589283632 RDK_SollDruck_HA 0;
BA_ "GenSigStartValue" SG_ 2589283632 RDK_SollDruck_HA 63;
BA_ "GenSigSwitchedByIgnition" SG_ 2589283632 RDK_SollDruck_HA 0;
BA_ "GenSigSendType" SG_ 2589283632 RDK_SollDruck_VA 0;
BA_ "GenSigStartValue" SG_ 2589283632 RDK_SollDruck_VA 63;
BA_ "GenSigSwitchedByIgnition" SG_ 2589283632 RDK_SollDruck_VA 0;
BA_ "GenSigSendType" SG_ 1651 RDK_Druck_HL_unkomp 0;
BA_ "GenSigStartValue" SG_ 1651 RDK_Druck_HL_unkomp 63;
BA_ "GenSigSwitchedByIgnition" SG_ 1651 RDK_Druck_HL_unkomp 0;
BA_ "GenSigSendType" SG_ 1651 RDK_Druck_HR_unkomp 0;
BA_ "GenSigStartValue" SG_ 1651 RDK_Druck_HR_unkomp 63;
BA_ "GenSigSwitchedByIgnition" SG_ 1651 RDK_Druck_HR_unkomp 0;
BA_ "GenSigSendType" SG_ 1651 RDK_Druck_VL_unkomp 0;
BA_ "GenSigStartValue" SG_ 1651 RDK_Druck_VL_unkomp 63;
BA_ "GenSigSwitchedByIgnition" SG_ 1651 RDK_Druck_VL_unkomp 0;
BA_ "GenSigSendType" SG_ 1651 RDK_Druck_VR_unkomp 0;
BA_ "GenSigStartValue" SG_ 1651 RDK_Druck_VR_unkomp 63;
BA_ "GenSigSwitchedByIgnition" SG_ 1651 RDK_Druck_VR_unkomp 0;
BA_ "GenSigSendType" SG_ 1651 RDK_R_Temp_HL 0;
BA_ "GenSigStartValue" SG_ 1651 RDK_R_Temp_HL 80;
BA_ "GenSigSwitchedByIgnition" SG_ 1651 RDK_R_Temp_HL 0;
BA_ "Fehlerwert" SG_ 1651 RDK_R_Temp_HL 255;
BA_ "GenSigSendType" SG_ 1651 RDK_R_Temp_HR 0;
BA_ "GenSigStartValue" SG_ 1651 RDK_R_Temp_HR 80;
BA_ "GenSigSwitchedByIgnition" SG_ 1651 RDK_R_Temp_HR 0;
BA_ "Fehlerwert" SG_ 1651 RDK_R_Temp_HR 255;
BA_ "GenSigSendType" SG_ 1651 RDK_R_Temp_VL 0;
BA_ "GenSigStartValue" SG_ 1651 RDK_R_Temp_VL 80;
BA_ "GenSigSwitchedByIgnition" SG_ 1651 RDK_R_Temp_VL 0;
BA_ "Fehlerwert" SG_ 1651 RDK_R_Temp_VL 255;
BA_ "GenSigSendType" SG_ 1651 RDK_R_Temp_VR 0;
BA_ "GenSigStartValue" SG_ 1651 RDK_R_Temp_VR 80;
BA_ "GenSigSwitchedByIgnition" SG_ 1651 RDK_R_Temp_VR 0;
BA_ "Fehlerwert" SG_ 1651 RDK_R_Temp_VR 255;
BA_ "GenSigSendType" SG_ 1651 RDK_Signal_Alter_HL 0;
BA_ "GenSigSwitchedByIgnition" SG_ 1651 RDK_Signal_Alter_HL 0;
BA_ "GenSigSendType" SG_ 1651 RDK_Signal_Alter_HR 0;
BA_ "GenSigSwitchedByIgnition" SG_ 1651 RDK_Signal_Alter_HR 0;
BA_ "GenSigSendType" SG_ 1651 RDK_Signal_Alter_VL 0;
BA_ "GenSigSwitchedByIgnition" SG_ 1651 RDK_Signal_Alter_VL 0;
BA_ "GenSigSendType" SG_ 1651 RDK_Signal_Alter_VR 0;
BA_ "GenSigSwitchedByIgnition" SG_ 1651 RDK_Signal_Alter_VR 0;
BA_ "GenSigSendType" SG_ 1711 RV_Calib_Fehler 3;
BA_ "GenSigSwitchedByIgnition" SG_ 1711 RV_Calib_Fehler 0;
BA_ "GenSigSendType" SG_ 1711 RV_Dark_Screen 3;
BA_ "GenSigSwitchedByIgnition" SG_ 1711 RV_Dark_Screen 0;
BA_ "GenSigSendType" SG_ 1711 RV_Farbe 3;
BA_ "GenSigSwitchedByIgnition" SG_ 1711 RV_Farbe 0;
BA_ "GenSigSendType" SG_ 1711 RV_GL_LWS_Fehler 3;
BA_ "GenSigSwitchedByIgnition" SG_ 1711 RV_GL_LWS_Fehler 0;
BA_ "GenSigSendType" SG_ 1711 RV_GL_side 3;
BA_ "GenSigSendType" SG_ 1711 RV_GL_Trailer_connect 3;
BA_ "GenSigSwitchedByIgnition" SG_ 1711 RV_GL_Trailer_connect 0;
BA_ "GenSigSendType" SG_ 1711 RV_GL_Trunk_open 3;
BA_ "GenSigSwitchedByIgnition" SG_ 1711 RV_GL_Trunk_open 0;
BA_ "GenSigSendType" SG_ 1711 RV_Helligkeit 3;
BA_ "GenSigSwitchedByIgnition" SG_ 1711 RV_Helligkeit 0;
BA_ "GenSigSendType" SG_ 1711 RV_HMI_Mode 3;
BA_ "GenSigSwitchedByIgnition" SG_ 1711 RV_HMI_Mode 0;
BA_ "GenSigSendType" SG_ 1711 RV_Kontrast 3;
BA_ "GenSigSwitchedByIgnition" SG_ 1711 RV_Kontrast 0;
BA_ "GenSigSendType" SG_ 1711 RV_Menu_Item 3;
BA_ "GenSigSwitchedByIgnition" SG_ 1711 RV_Menu_Item 0;
BA_ "GenSigSendType" SG_ 1711 RV_Reinigung_Anf 3;
BA_ "GenSigSwitchedByIgnition" SG_ 1711 RV_Reinigung_Anf 0;
BA_ "GenSigSendType" SG_ 1711 RV_Settings_enabled 3;
BA_ "GenSigSwitchedByIgnition" SG_ 1711 RV_Settings_enabled 0;
BA_ "GenSigSendType" SG_ 1711 RV_System_aktiv 3;
BA_ "GenSigSwitchedByIgnition" SG_ 1711 RV_System_aktiv 0;
BA_ "GenSigSendType" SG_ 1711 RV_Video_on 3;
BA_ "GenSigSwitchedByIgnition" SG_ 1711 RV_Video_on 0;
BA_ "GenSigSendType" SG_ 1711 SV_Video_on 3;
BA_ "GenSigSendType" SG_ 1711 ZFAS_Umfeldbeleuchtung_Anf 3;
BA_ "GenSigSwitchedByIgnition" SG_ 1711 ZFAS_Umfeldbeleuchtung_Anf 0;
BA_ "GenSigSendType" SG_ 1440 LS_defekt 0;
BA_ "GenSigSwitchedByIgnition" SG_ 1440 LS_defekt 0;
BA_ "GenSigSendType" SG_ 1440 LS_Helligkeit_FW 0;
BA_ "GenSigStartValue" SG_ 1440 LS_Helligkeit_FW 1022;
BA_ "GenSigSwitchedByIgnition" SG_ 1440 LS_Helligkeit_FW 0;
BA_ "Fehlerwert" SG_ 1440 LS_Helligkeit_FW 1023;
BA_ "GenSigMissingSourceValue" SG_ 1440 LS_Helligkeit_FW 1023;
BA_ "GenSigSendType" SG_ 1440 LS_Helligkeit_IR 0;
BA_ "GenSigStartValue" SG_ 1440 LS_Helligkeit_IR 254;
BA_ "GenSigSwitchedByIgnition" SG_ 1440 LS_Helligkeit_IR 0;
BA_ "Fehlerwert" SG_ 1440 LS_Helligkeit_IR 255;
BA_ "GenSigMissingSourceValue" SG_ 1440 LS_Helligkeit_IR 255;
BA_ "GenSigSendType" SG_ 1440 LS_Verbau 0;
BA_ "GenSigSwitchedByIgnition" SG_ 1440 LS_Verbau 0;
BA_ "GenSigSendType" SG_ 1440 RLS_Vorfeldhelligkeit_Boost 0;
BA_ "GenSigStartValue" SG_ 1440 RLS_Vorfeldhelligkeit_Boost 15;
BA_ "GenSigSwitchedByIgnition" SG_ 1440 RLS_Vorfeldhelligkeit_Boost 0;
BA_ "GenSigSendType" SG_ 1440 RS_defekt 0;
BA_ "GenSigSwitchedByIgnition" SG_ 1440 RS_defekt 0;
BA_ "GenSigSendType" SG_ 1440 RS_Regenmenge 0;
BA_ "GenSigStartValue" SG_ 1440 RS_Regenmenge 14;
BA_ "GenSigSwitchedByIgnition" SG_ 1440 RS_Regenmenge 0;
BA_ "Fehlerwert" SG_ 1440 RS_Regenmenge 15;
BA_ "GenSigMissingSourceValue" SG_ 1440 RS_Regenmenge 15;
BA_ "GenSigSendType" SG_ 1440 RS_Verbau 0;
BA_ "GenSigSwitchedByIgnition" SG_ 1440 RS_Verbau 0;
BA_ "GenSigSendType" SG_ 1440 RS_Verglasung_schliessen 0;
BA_ "GenSigSwitchedByIgnition" SG_ 1440 RS_Verglasung_schliessen 0;
BA_ "GenSigSendType" SG_ 1440 RS_Wischergeschwindigkeit 0;
BA_ "GenSigSwitchedByIgnition" SG_ 1440 RS_Wischergeschwindigkeit 0;
BA_ "GenSigSendType" SG_ 1528 SAK_Charisma_FahrPr 3;
BA_ "GenSigSendType" SG_ 1528 SAK_Charisma_Status 3;
BA_ "GenSigSendType" SG_ 424 SARA_11_BZ 0;
BA_ "GenSigFuncType" SG_ 424 SARA_11_BZ 1;
BA_ "GenSigSwitchedByIgnition" SG_ 424 SARA_11_BZ 0;
BA_ "GenSigSendType" SG_ 424 SARA_11_CRC 0;
BA_ "GenSigFuncType" SG_ 424 SARA_11_CRC 2;
BA_ "GenSigSwitchedByIgnition" SG_ 424 SARA_11_CRC 0;
BA_ "GenSigSendType" SG_ 424 SARA_Accel_X_r 0;
BA_ "GenSigStartValue" SG_ 424 SARA_Accel_X_r 4096;
BA_ "GenSigSwitchedByIgnition" SG_ 424 SARA_Accel_X_r 0;
BA_ "Fehlerwert" SG_ 424 SARA_Accel_X_r 8191;
BA_ "GenSigSendType" SG_ 424 SARA_Accel_Y_r 0;
BA_ "GenSigStartValue" SG_ 424 SARA_Accel_Y_r 4096;
BA_ "GenSigSwitchedByIgnition" SG_ 424 SARA_Accel_Y_r 0;
BA_ "Fehlerwert" SG_ 424 SARA_Accel_Y_r 8191;
BA_ "GenSigSendType" SG_ 424 SARA_CF_Accel_X_r 0;
BA_ "GenSigStartValue" SG_ 424 SARA_CF_Accel_X_r 4;
BA_ "GenSigSwitchedByIgnition" SG_ 424 SARA_CF_Accel_X_r 0;
BA_ "GenSigSendType" SG_ 424 SARA_CF_Accel_Y_r 0;
BA_ "GenSigStartValue" SG_ 424 SARA_CF_Accel_Y_r 4;
BA_ "GenSigSwitchedByIgnition" SG_ 424 SARA_CF_Accel_Y_r 0;
BA_ "GenSigSendType" SG_ 424 SARA_CF_Omega_Z_r 0;
BA_ "GenSigStartValue" SG_ 424 SARA_CF_Omega_Z_r 4;
BA_ "GenSigSwitchedByIgnition" SG_ 424 SARA_CF_Omega_Z_r 0;
BA_ "GenSigSendType" SG_ 424 SARA_Omega_Z_r 0;
BA_ "GenSigStartValue" SG_ 424 SARA_Omega_Z_r 4096;
BA_ "GenSigSwitchedByIgnition" SG_ 424 SARA_Omega_Z_r 0;
BA_ "Fehlerwert" SG_ 424 SARA_Omega_Z_r 8191;
BA_ "GenSigSendType" SG_ 1011 SCR_01_BZ 0;
BA_ "GenSigFuncType" SG_ 1011 SCR_01_BZ 1;
BA_ "GenSigSwitchedByIgnition" SG_ 1011 SCR_01_BZ 0;
BA_ "GenSigSendType" SG_ 1011 SCR_Dosierpumpe_Drehzahl 0;
BA_ "GenSigStartValue" SG_ 1011 SCR_Dosierpumpe_Drehzahl 2046;
BA_ "GenSigSwitchedByIgnition" SG_ 1011 SCR_Dosierpumpe_Drehzahl 0;
BA_ "Fehlerwert" SG_ 1011 SCR_Dosierpumpe_Drehzahl 2047;
BA_ "GenSigSendType" SG_ 1011 SCR_Druck 0;
BA_ "GenSigStartValue" SG_ 1011 SCR_Druck 1022;
BA_ "GenSigSwitchedByIgnition" SG_ 1011 SCR_Druck 0;
BA_ "Fehlerwert" SG_ 1011 SCR_Druck 1023;
BA_ "GenSigSendType" SG_ 1011 SCR_Level_Aktivtank 0;
BA_ "GenSigStartValue" SG_ 1011 SCR_Level_Aktivtank 1022;
BA_ "GenSigSwitchedByIgnition" SG_ 1011 SCR_Level_Aktivtank 0;
BA_ "Fehlerwert" SG_ 1011 SCR_Level_Aktivtank 1023;
BA_ "GenSigSendType" SG_ 1011 SCR_Level_ReadAbove 0;
BA_ "GenSigSwitchedByIgnition" SG_ 1011 SCR_Level_ReadAbove 0;
BA_ "GenSigSendType" SG_ 1011 SCR_QBit_Level_Aktivtank_02 0;
BA_ "GenSigStartValue" SG_ 1011 SCR_QBit_Level_Aktivtank_02 1;
BA_ "GenSigSwitchedByIgnition" SG_ 1011 SCR_QBit_Level_Aktivtank_02 0;
BA_ "GenSigSendType" SG_ 1011 SCR_Sent_Level_Aktivtank 0;
BA_ "GenSigStartValue" SG_ 1011 SCR_Sent_Level_Aktivtank 1022;
BA_ "GenSigSwitchedByIgnition" SG_ 1011 SCR_Sent_Level_Aktivtank 0;
BA_ "GenSigSendType" SG_ 1011 SCR_Sent_Levelsignal_Status 0;
BA_ "GenSigStartValue" SG_ 1011 SCR_Sent_Levelsignal_Status 7;
BA_ "GenSigSwitchedByIgnition" SG_ 1011 SCR_Sent_Levelsignal_Status 0;
BA_ "Fehlerwert" SG_ 1011 SCR_Sent_Levelsignal_Status 6;
BA_ "GenSigSendType" SG_ 1507 SCR_02_BZ 0;
BA_ "GenSigFuncType" SG_ 1507 SCR_02_BZ 1;
BA_ "GenSigSwitchedByIgnition" SG_ 1507 SCR_02_BZ 0;
BA_ "GenSigSendType" SG_ 1507 SCR_Guetesensor 0;
BA_ "GenSigStartValue" SG_ 1507 SCR_Guetesensor 1022;
BA_ "GenSigSwitchedByIgnition" SG_ 1507 SCR_Guetesensor 0;
BA_ "Fehlerwert" SG_ 1507 SCR_Guetesensor 1023;
BA_ "GenSigSendType" SG_ 1507 SCR_Heizkreis_3_Strom 0;
BA_ "GenSigStartValue" SG_ 1507 SCR_Heizkreis_3_Strom 254;
BA_ "GenSigSwitchedByIgnition" SG_ 1507 SCR_Heizkreis_3_Strom 0;
BA_ "Fehlerwert" SG_ 1507 SCR_Heizkreis_3_Strom 255;
BA_ "GenSigSendType" SG_ 1507 SCR_Leitungsheizung_Strom 0;
BA_ "GenSigStartValue" SG_ 1507 SCR_Leitungsheizung_Strom 254;
BA_ "GenSigSwitchedByIgnition" SG_ 1507 SCR_Leitungsheizung_Strom 0;
BA_ "Fehlerwert" SG_ 1507 SCR_Leitungsheizung_Strom 255;
BA_ "GenSigSendType" SG_ 1507 SCR_Tankheizung_Strom 0;
BA_ "GenSigStartValue" SG_ 1507 SCR_Tankheizung_Strom 254;
BA_ "GenSigSwitchedByIgnition" SG_ 1507 SCR_Tankheizung_Strom 0;
BA_ "Fehlerwert" SG_ 1507 SCR_Tankheizung_Strom 255;
BA_ "GenSigSendType" SG_ 1507 SCR_Temp_Aktivtank 0;
BA_ "GenSigStartValue" SG_ 1507 SCR_Temp_Aktivtank 254;
BA_ "GenSigSwitchedByIgnition" SG_ 1507 SCR_Temp_Aktivtank 0;
BA_ "Fehlerwert" SG_ 1507 SCR_Temp_Aktivtank 255;
BA_ "GenSigSendType" SG_ 1507 SCR_Temp_Passivtank 0;
BA_ "GenSigStartValue" SG_ 1507 SCR_Temp_Passivtank 254;
BA_ "GenSigSwitchedByIgnition" SG_ 1507 SCR_Temp_Passivtank 0;
BA_ "Fehlerwert" SG_ 1507 SCR_Temp_Passivtank 255;
BA_ "GenSigSendType" SG_ 1507 SCR_Transferpumpe_Strom 0;
BA_ "GenSigStartValue" SG_ 1507 SCR_Transferpumpe_Strom 254;
BA_ "GenSigSwitchedByIgnition" SG_ 1507 SCR_Transferpumpe_Strom 0;
BA_ "Fehlerwert" SG_ 1507 SCR_Transferpumpe_Strom 255;
BA_ "GenSigSendType" SG_ 1508 SCR_03_BZ 0;
BA_ "GenSigFuncType" SG_ 1508 SCR_03_BZ 1;
BA_ "GenSigSwitchedByIgnition" SG_ 1508 SCR_03_BZ 0;
BA_ "GenSigSendType" SG_ 1508 SCR_Dosierpumpe_Status_Spule 3;
BA_ "GenSigSwitchedByIgnition" SG_ 1508 SCR_Dosierpumpe_Status_Spule 0;
BA_ "GenSigSendType" SG_ 1508 SCR_Druck_Status_02 3;
BA_ "GenSigSwitchedByIgnition" SG_ 1508 SCR_Druck_Status_02 0;
BA_ "GenSigSendType" SG_ 1508 SCR_Heizkreis_3_Status 3;
BA_ "GenSigStartValue" SG_ 1508 SCR_Heizkreis_3_Status 15;
BA_ "GenSigSwitchedByIgnition" SG_ 1508 SCR_Heizkreis_3_Status 0;
BA_ "GenSigSendType" SG_ 1508 SCR_Leitungsheizung_Status 3;
BA_ "GenSigStartValue" SG_ 1508 SCR_Leitungsheizung_Status 15;
BA_ "GenSigSwitchedByIgnition" SG_ 1508 SCR_Leitungsheizung_Status 0;
BA_ "GenSigSendType" SG_ 1508 SCR_Level_Aktivtank_Status 3;
BA_ "GenSigStartValue" SG_ 1508 SCR_Level_Aktivtank_Status 15;
BA_ "GenSigSwitchedByIgnition" SG_ 1508 SCR_Level_Aktivtank_Status 0;
BA_ "GenSigSendType" SG_ 1508 SCR_Level_Passivtank_Status 3;
BA_ "GenSigStartValue" SG_ 1508 SCR_Level_Passivtank_Status 15;
BA_ "GenSigSwitchedByIgnition" SG_ 1508 SCR_Level_Passivtank_Status 0;
BA_ "GenSigSendType" SG_ 1508 SCR_Sensorversorgung_12V_Status 3;
BA_ "GenSigStartValue" SG_ 1508 SCR_Sensorversorgung_12V_Status 15;
BA_ "GenSigSwitchedByIgnition" SG_ 1508 SCR_Sensorversorgung_12V_Status 0;
BA_ "GenSigSendType" SG_ 1508 SCR_Spannungsversorgung_Status 3;
BA_ "GenSigStartValue" SG_ 1508 SCR_Spannungsversorgung_Status 15;
BA_ "GenSigSwitchedByIgnition" SG_ 1508 SCR_Spannungsversorgung_Status 0;
BA_ "GenSigSendType" SG_ 1508 SCR_Tankheizung_Status 3;
BA_ "GenSigStartValue" SG_ 1508 SCR_Tankheizung_Status 15;
BA_ "GenSigSwitchedByIgnition" SG_ 1508 SCR_Tankheizung_Status 0;
BA_ "GenSigSendType" SG_ 1508 SCR_Temp_Aktivtank_Status_02 3;
BA_ "GenSigSwitchedByIgnition" SG_ 1508 SCR_Temp_Aktivtank_Status_02 0;
BA_ "GenSigSendType" SG_ 1508 SCR_Temp_Passivtank_Status 3;
BA_ "GenSigStartValue" SG_ 1508 SCR_Temp_Passivtank_Status 15;
BA_ "GenSigSwitchedByIgnition" SG_ 1508 SCR_Temp_Passivtank_Status 0;
BA_ "GenSigSendType" SG_ 1508 SCR_Transferpumpe_Status 3;
BA_ "GenSigSwitchedByIgnition" SG_ 1508 SCR_Transferpumpe_Status 0;
BA_ "GenSigSendType" SG_ 1508 SCR_VersorgungSensoren_Status_02 3;
BA_ "GenSigStartValue" SG_ 1508 SCR_VersorgungSensoren_Status_02 15;
BA_ "GenSigSwitchedByIgnition" SG_ 1508 SCR_VersorgungSensoren_Status_02 0;
BA_ "GenSigSendType" SG_ 1509 SCR_04_BZ 0;
BA_ "GenSigFuncType" SG_ 1509 SCR_04_BZ 1;
BA_ "GenSigSwitchedByIgnition" SG_ 1509 SCR_04_BZ 0;
BA_ "GenSigSendType" SG_ 1509 SCR_Ansteuerung_Dosierpumpe 0;
BA_ "GenSigSwitchedByIgnition" SG_ 1509 SCR_Ansteuerung_Dosierpumpe 0;
BA_ "GenSigSendType" SG_ 1509 SCR_Ansteuerung_Heizkreis_3 0;
BA_ "GenSigSwitchedByIgnition" SG_ 1509 SCR_Ansteuerung_Heizkreis_3 0;
BA_ "GenSigSendType" SG_ 1509 SCR_Ansteuerung_Leitungsheizung 0;
BA_ "GenSigSwitchedByIgnition" SG_ 1509 SCR_Ansteuerung_Leitungsheizung 0;
BA_ "GenSigSendType" SG_ 1509 SCR_Ansteuerung_Tankheizung 0;
BA_ "GenSigSwitchedByIgnition" SG_ 1509 SCR_Ansteuerung_Tankheizung 0;
BA_ "GenSigSendType" SG_ 1509 SCR_Ansteuerung_Transferpumpe 0;
BA_ "GenSigSwitchedByIgnition" SG_ 1509 SCR_Ansteuerung_Transferpumpe 0;
BA_ "GenSigSendType" SG_ 1509 SCR_CAL_CVN_CRC_32 0;
BA_ "GenSigSwitchedByIgnition" SG_ 1509 SCR_CAL_CVN_CRC_32 0;
BA_ "GenSigSendType" SG_ 1509 SCR_Steuergeraet_PMode 0;
BA_ "GenSigSwitchedByIgnition" SG_ 1509 SCR_Steuergeraet_PMode 0;
BA_ "GenSigSendType" SG_ 1526 SCR_05_BZ 0;
BA_ "GenSigFuncType" SG_ 1526 SCR_05_BZ 1;
BA_ "GenSigSwitchedByIgnition" SG_ 1526 SCR_05_BZ 0;
BA_ "GenSigSendType" SG_ 1526 SCR_DEF_Qualitaet_Medium 3;
BA_ "GenSigSwitchedByIgnition" SG_ 1526 SCR_DEF_Qualitaet_Medium 0;
BA_ "GenSigSendType" SG_ 1526 SCR_ECU_Datensatz_Status 3;
BA_ "GenSigStartValue" SG_ 1526 SCR_ECU_Datensatz_Status 3;
BA_ "GenSigSwitchedByIgnition" SG_ 1526 SCR_ECU_Datensatz_Status 0;
BA_ "GenSigSendType" SG_ 1526 SCR_HAL_Sensorik_Status 3;
BA_ "GenSigStartValue" SG_ 1526 SCR_HAL_Sensorik_Status 15;
BA_ "GenSigSwitchedByIgnition" SG_ 1526 SCR_HAL_Sensorik_Status 0;
BA_ "GenSigSendType" SG_ 1526 SCR_Level_Aktivtank_OOR4Quality 3;
BA_ "GenSigSwitchedByIgnition" SG_ 1526 SCR_Level_Aktivtank_OOR4Quality 0;
BA_ "GenSigSendType" SG_ 1526 SCR_Level_Aktivtank_OOR_minus 3;
BA_ "GenSigSwitchedByIgnition" SG_ 1526 SCR_Level_Aktivtank_OOR_minus 0;
BA_ "GenSigSendType" SG_ 1526 SCR_QBit_Qualitaet 0;
BA_ "GenSigStartValue" SG_ 1526 SCR_QBit_Qualitaet 1;
BA_ "GenSigSwitchedByIgnition" SG_ 1526 SCR_QBit_Qualitaet 0;
BA_ "GenSigSendType" SG_ 1526 SCR_Sent_1_elektrischer_Status 3;
BA_ "GenSigStartValue" SG_ 1526 SCR_Sent_1_elektrischer_Status 15;
BA_ "GenSigSwitchedByIgnition" SG_ 1526 SCR_Sent_1_elektrischer_Status 0;
BA_ "GenSigSendType" SG_ 1526 SCR_Sent_1_Signalstatus 3;
BA_ "GenSigStartValue" SG_ 1526 SCR_Sent_1_Signalstatus 3;
BA_ "GenSigSwitchedByIgnition" SG_ 1526 SCR_Sent_1_Signalstatus 0;
BA_ "GenSigSendType" SG_ 1526 SCR_Sent_2_elektrischer_Status 3;
BA_ "GenSigStartValue" SG_ 1526 SCR_Sent_2_elektrischer_Status 15;
BA_ "GenSigSwitchedByIgnition" SG_ 1526 SCR_Sent_2_elektrischer_Status 0;
BA_ "GenSigSendType" SG_ 1526 SCR_Sent_2_Signalstatus 3;
BA_ "GenSigStartValue" SG_ 1526 SCR_Sent_2_Signalstatus 3;
BA_ "GenSigSwitchedByIgnition" SG_ 1526 SCR_Sent_2_Signalstatus 0;
BA_ "GenSigSendType" SG_ 1526 SCR_Sent_Levelsensor 3;
BA_ "GenSigStartValue" SG_ 1526 SCR_Sent_Levelsensor 7;
BA_ "GenSigSwitchedByIgnition" SG_ 1526 SCR_Sent_Levelsensor 0;
BA_ "GenSigSendType" SG_ 1526 SCR_Sent_Qualitaetssensor 3;
BA_ "GenSigStartValue" SG_ 1526 SCR_Sent_Qualitaetssensor 7;
BA_ "GenSigSwitchedByIgnition" SG_ 1526 SCR_Sent_Qualitaetssensor 0;
BA_ "GenSigSendType" SG_ 1526 SCR_Sent_Temperatursensor 3;
BA_ "GenSigStartValue" SG_ 1526 SCR_Sent_Temperatursensor 7;
BA_ "GenSigSwitchedByIgnition" SG_ 1526 SCR_Sent_Temperatursensor 0;
BA_ "GenSigSendType" SG_ 1526 SCR_Steuergeraet_Bus_Status 3;
BA_ "GenSigStartValue" SG_ 1526 SCR_Steuergeraet_Bus_Status 3;
BA_ "GenSigSwitchedByIgnition" SG_ 1526 SCR_Steuergeraet_Bus_Status 0;
BA_ "GenSigSendType" SG_ 1526 SCR_Steuergeraet_Defekt_Status 3;
BA_ "GenSigStartValue" SG_ 1526 SCR_Steuergeraet_Defekt_Status 3;
BA_ "GenSigSwitchedByIgnition" SG_ 1526 SCR_Steuergeraet_Defekt_Status 0;
BA_ "GenSigSendType" SG_ 1526 SCR_Steuergeraet_Heizung_Status 3;
BA_ "GenSigStartValue" SG_ 1526 SCR_Steuergeraet_Heizung_Status 3;
BA_ "GenSigSwitchedByIgnition" SG_ 1526 SCR_Steuergeraet_Heizung_Status 0;
BA_ "GenSigSendType" SG_ 1526 SCR_Steuergeraet_Pumpe_Status 3;
BA_ "GenSigStartValue" SG_ 1526 SCR_Steuergeraet_Pumpe_Status 3;
BA_ "GenSigSwitchedByIgnition" SG_ 1526 SCR_Steuergeraet_Pumpe_Status 0;
BA_ "GenSigSendType" SG_ 1526 SCR_Steuergeraet_Relais_Status 3;
BA_ "GenSigStartValue" SG_ 1526 SCR_Steuergeraet_Relais_Status 3;
BA_ "GenSigSwitchedByIgnition" SG_ 1526 SCR_Steuergeraet_Relais_Status 0;
BA_ "GenSigSendType" SG_ 1526 SCR_Temp_DEF2_Sensor_Status 3;
BA_ "GenSigStartValue" SG_ 1526 SCR_Temp_DEF2_Sensor_Status 7;
BA_ "GenSigSwitchedByIgnition" SG_ 1526 SCR_Temp_DEF2_Sensor_Status 0;
BA_ "GenSigSendType" SG_ 2527679503 SCR_DEF_CAL_CVN_CRC_32 0;
BA_ "GenSigSwitchedByIgnition" SG_ 2527679503 SCR_DEF_CAL_CVN_CRC_32 0;
BA_ "GenSigSendType" SG_ 2527679503 SCR_Level_Aktivtank_saturated 0;
BA_ "GenSigSwitchedByIgnition" SG_ 2527679503 SCR_Level_Aktivtank_saturated 0;
BA_ "GenSigSendType" SG_ 2527679503 SCR_QBit_Qualitaet_Aktivtank 0;
BA_ "GenSigStartValue" SG_ 2527679503 SCR_QBit_Qualitaet_Aktivtank 1;
BA_ "GenSigSwitchedByIgnition" SG_ 2527679503 SCR_QBit_Qualitaet_Aktivtank 0;
BA_ "GenSigSendType" SG_ 2527679503 SCR_QBit_Temp_DEF_Sensor_02 0;
BA_ "GenSigStartValue" SG_ 2527679503 SCR_QBit_Temp_DEF_Sensor_02 1;
BA_ "GenSigSwitchedByIgnition" SG_ 2527679503 SCR_QBit_Temp_DEF_Sensor_02 0;
BA_ "GenSigSendType" SG_ 2527679503 SCR_Sent_Qualitaet_Aktivtank 0;
BA_ "GenSigStartValue" SG_ 2527679503 SCR_Sent_Qualitaet_Aktivtank 254;
BA_ "GenSigSwitchedByIgnition" SG_ 2527679503 SCR_Sent_Qualitaet_Aktivtank 0;
BA_ "GenSigSendType" SG_ 2527679503 SCR_Temp_DEF_Hinweis 0;
BA_ "GenSigStartValue" SG_ 2527679503 SCR_Temp_DEF_Hinweis 3;
BA_ "GenSigSwitchedByIgnition" SG_ 2527679503 SCR_Temp_DEF_Hinweis 0;
BA_ "GenSigSendType" SG_ 2527679503 SCR_Temperatur_DEF_Sensor 0;
BA_ "GenSigSwitchedByIgnition" SG_ 2527679503 SCR_Temperatur_DEF_Sensor 0;
BA_ "GenSigSendType" SG_ 2589283459 SCR_Heizkreis_3_P_effektiv 0;
BA_ "GenSigStartValue" SG_ 2589283459 SCR_Heizkreis_3_P_effektiv 254;
BA_ "GenSigSwitchedByIgnition" SG_ 2589283459 SCR_Heizkreis_3_P_effektiv 0;
BA_ "GenSigSendType" SG_ 2589283459 SCR_Heizkreis_3_P_Grenze 0;
BA_ "GenSigStartValue" SG_ 2589283459 SCR_Heizkreis_3_P_Grenze 254;
BA_ "GenSigSwitchedByIgnition" SG_ 2589283459 SCR_Heizkreis_3_P_Grenze 0;
BA_ "GenSigSendType" SG_ 2589283459 SCR_Tankheizkreis_P_Grenze 0;
BA_ "GenSigStartValue" SG_ 2589283459 SCR_Tankheizkreis_P_Grenze 254;
BA_ "GenSigSwitchedByIgnition" SG_ 2589283459 SCR_Tankheizkreis_P_Grenze 0;
BA_ "GenSigSendType" SG_ 2589283459 SCR_Tankheizung_P_effektiv 0;
BA_ "GenSigStartValue" SG_ 2589283459 SCR_Tankheizung_P_effektiv 254;
BA_ "GenSigSwitchedByIgnition" SG_ 2589283459 SCR_Tankheizung_P_effektiv 0;
BA_ "GenSigSendType" SG_ 2589283460 SCR_DEF2_CAL_CVN_CRC_32 0;
BA_ "GenSigSwitchedByIgnition" SG_ 2589283460 SCR_DEF2_CAL_CVN_CRC_32 0;
BA_ "GenSigSendType" SG_ 2589283460 SCR_QBit_Temp_DEF2_Sensor 0;
BA_ "GenSigStartValue" SG_ 2589283460 SCR_QBit_Temp_DEF2_Sensor 1;
BA_ "GenSigSwitchedByIgnition" SG_ 2589283460 SCR_QBit_Temp_DEF2_Sensor 0;
BA_ "GenSigSendType" SG_ 2589283460 SCR_Temp_DEF2_Sensor 0;
BA_ "GenSigStartValue" SG_ 2589283460 SCR_Temp_DEF2_Sensor 254;
BA_ "GenSigSwitchedByIgnition" SG_ 2589283460 SCR_Temp_DEF2_Sensor 0;
BA_ "GenSigSendType" SG_ 2463978593 SCR_Dosierpumpe_Umdrehungen 0;
BA_ "GenSigStartValue" SG_ 2463978593 SCR_Dosierpumpe_Umdrehungen 254;
BA_ "GenSigSwitchedByIgnition" SG_ 2463978593 SCR_Dosierpumpe_Umdrehungen 0;
BA_ "Fehlerwert" SG_ 2463978593 SCR_Dosierpumpe_Umdrehungen 255;
BA_ "GenSigSendType" SG_ 2463978593 SCR_QBit_Level_kurz_Aktivtank 0;
BA_ "GenSigStartValue" SG_ 2463978593 SCR_QBit_Level_kurz_Aktivtank 1;
BA_ "GenSigSwitchedByIgnition" SG_ 2463978593 SCR_QBit_Level_kurz_Aktivtank 0;
BA_ "GenSigSendType" SG_ 2463978593 SCR_Sent_Level_kurz_Aktivtank 0;
BA_ "GenSigStartValue" SG_ 2463978593 SCR_Sent_Level_kurz_Aktivtank 1022;
BA_ "GenSigSwitchedByIgnition" SG_ 2463978593 SCR_Sent_Level_kurz_Aktivtank 0;
BA_ "GenSigSendType" SG_ 1510 SCR_CAL_ID_Index_01 0;
BA_ "GenSigStartValue" SG_ 1510 SCR_CAL_ID_Index_01 83;
BA_ "GenSigSwitchedByIgnition" SG_ 1510 SCR_CAL_ID_Index_01 0;
BA_ "GenSigSendType" SG_ 1510 SCR_CAL_ID_Index_02 0;
BA_ "GenSigStartValue" SG_ 1510 SCR_CAL_ID_Index_02 67;
BA_ "GenSigSwitchedByIgnition" SG_ 1510 SCR_CAL_ID_Index_02 0;
BA_ "GenSigSendType" SG_ 1510 SCR_CAL_ID_Index_03 0;
BA_ "GenSigStartValue" SG_ 1510 SCR_CAL_ID_Index_03 82;
BA_ "GenSigSwitchedByIgnition" SG_ 1510 SCR_CAL_ID_Index_03 0;
BA_ "GenSigSendType" SG_ 1510 SCR_CAL_ID_Index_04 0;
BA_ "GenSigStartValue" SG_ 1510 SCR_CAL_ID_Index_04 48;
BA_ "GenSigSwitchedByIgnition" SG_ 1510 SCR_CAL_ID_Index_04 0;
BA_ "GenSigSendType" SG_ 1510 SCR_CAL_ID_Index_05 0;
BA_ "GenSigStartValue" SG_ 1510 SCR_CAL_ID_Index_05 48;
BA_ "GenSigSwitchedByIgnition" SG_ 1510 SCR_CAL_ID_Index_05 0;
BA_ "GenSigSendType" SG_ 1510 SCR_CAL_ID_Index_06 0;
BA_ "GenSigStartValue" SG_ 1510 SCR_CAL_ID_Index_06 48;
BA_ "GenSigSwitchedByIgnition" SG_ 1510 SCR_CAL_ID_Index_06 0;
BA_ "GenSigSendType" SG_ 1510 SCR_CAL_ID_Index_07 0;
BA_ "GenSigStartValue" SG_ 1510 SCR_CAL_ID_Index_07 48;
BA_ "GenSigSwitchedByIgnition" SG_ 1510 SCR_CAL_ID_Index_07 0;
BA_ "GenSigSendType" SG_ 1510 SCR_CAL_ID_Index_08 0;
BA_ "GenSigStartValue" SG_ 1510 SCR_CAL_ID_Index_08 48;
BA_ "GenSigSwitchedByIgnition" SG_ 1510 SCR_CAL_ID_Index_08 0;
BA_ "GenSigSendType" SG_ 1512 SCR_CAL_ID_Index_09 0;
BA_ "GenSigStartValue" SG_ 1512 SCR_CAL_ID_Index_09 48;
BA_ "GenSigSwitchedByIgnition" SG_ 1512 SCR_CAL_ID_Index_09 0;
BA_ "GenSigSendType" SG_ 1512 SCR_CAL_ID_Index_10 0;
BA_ "GenSigStartValue" SG_ 1512 SCR_CAL_ID_Index_10 48;
BA_ "GenSigSwitchedByIgnition" SG_ 1512 SCR_CAL_ID_Index_10 0;
BA_ "GenSigSendType" SG_ 1512 SCR_CAL_ID_Index_11 0;
BA_ "GenSigStartValue" SG_ 1512 SCR_CAL_ID_Index_11 48;
BA_ "GenSigSwitchedByIgnition" SG_ 1512 SCR_CAL_ID_Index_11 0;
BA_ "GenSigSendType" SG_ 1512 SCR_CAL_ID_Index_12 0;
BA_ "GenSigStartValue" SG_ 1512 SCR_CAL_ID_Index_12 48;
BA_ "GenSigSwitchedByIgnition" SG_ 1512 SCR_CAL_ID_Index_12 0;
BA_ "GenSigSendType" SG_ 1512 SCR_CAL_ID_Index_13 0;
BA_ "GenSigStartValue" SG_ 1512 SCR_CAL_ID_Index_13 48;
BA_ "GenSigSwitchedByIgnition" SG_ 1512 SCR_CAL_ID_Index_13 0;
BA_ "GenSigSendType" SG_ 1512 SCR_CAL_ID_Index_14 0;
BA_ "GenSigStartValue" SG_ 1512 SCR_CAL_ID_Index_14 48;
BA_ "GenSigSwitchedByIgnition" SG_ 1512 SCR_CAL_ID_Index_14 0;
BA_ "GenSigSendType" SG_ 1512 SCR_CAL_ID_Index_15 0;
BA_ "GenSigStartValue" SG_ 1512 SCR_CAL_ID_Index_15 48;
BA_ "GenSigSwitchedByIgnition" SG_ 1512 SCR_CAL_ID_Index_15 0;
BA_ "GenSigSendType" SG_ 1512 SCR_CAL_ID_Index_16 0;
BA_ "GenSigStartValue" SG_ 1512 SCR_CAL_ID_Index_16 48;
BA_ "GenSigSwitchedByIgnition" SG_ 1512 SCR_CAL_ID_Index_16 0;
BA_ "GenSigSendType" SG_ 2589283497 SCR_DEF2_CAL_ID_Index01 0;
BA_ "GenSigStartValue" SG_ 2589283497 SCR_DEF2_CAL_ID_Index01 1145390640;
BA_ "GenSigSwitchedByIgnition" SG_ 2589283497 SCR_DEF2_CAL_ID_Index01 0;
BA_ "GenSigSendType" SG_ 2589283497 SCR_DEF2_CAL_ID_Index02 0;
BA_ "GenSigStartValue" SG_ 2589283497 SCR_DEF2_CAL_ID_Index02 808464432;
BA_ "GenSigSwitchedByIgnition" SG_ 2589283497 SCR_DEF2_CAL_ID_Index02 0;
BA_ "GenSigSendType" SG_ 2589283498 SCR_DEF2_CAL_ID_Index03 0;
BA_ "GenSigStartValue" SG_ 2589283498 SCR_DEF2_CAL_ID_Index03 808464432;
BA_ "GenSigSwitchedByIgnition" SG_ 2589283498 SCR_DEF2_CAL_ID_Index03 0;
BA_ "GenSigSendType" SG_ 2589283498 SCR_DEF2_CAL_ID_Index04 0;
BA_ "GenSigStartValue" SG_ 2589283498 SCR_DEF2_CAL_ID_Index04 808464432;
BA_ "GenSigSwitchedByIgnition" SG_ 2589283498 SCR_DEF2_CAL_ID_Index04 0;
BA_ "GenSigSendType" SG_ 2589283413 SCR_DEF_CAL_ID_Index01 0;
BA_ "GenSigStartValue" SG_ 2589283413 SCR_DEF_CAL_ID_Index01 1145390640;
BA_ "GenSigSwitchedByIgnition" SG_ 2589283413 SCR_DEF_CAL_ID_Index01 0;
BA_ "GenSigSendType" SG_ 2589283413 SCR_DEF_CAL_ID_Index02 0;
BA_ "GenSigStartValue" SG_ 2589283413 SCR_DEF_CAL_ID_Index02 808464432;
BA_ "GenSigSwitchedByIgnition" SG_ 2589283413 SCR_DEF_CAL_ID_Index02 0;
BA_ "GenSigSendType" SG_ 2589283414 SCR_DEF_CAL_ID_Index03 0;
BA_ "GenSigStartValue" SG_ 2589283414 SCR_DEF_CAL_ID_Index03 808464432;
BA_ "GenSigSwitchedByIgnition" SG_ 2589283414 SCR_DEF_CAL_ID_Index03 0;
BA_ "GenSigSendType" SG_ 2589283414 SCR_DEF_CAL_ID_Index04 0;
BA_ "GenSigStartValue" SG_ 2589283414 SCR_DEF_CAL_ID_Index04 808464432;
BA_ "GenSigSwitchedByIgnition" SG_ 2589283414 SCR_DEF_CAL_ID_Index04 0;
BA_ "GenSigSendType" SG_ 980 BH_Blinker_Fehler 3;
BA_ "GenSigSwitchedByIgnition" SG_ 980 BH_Blinker_Fehler 0;
BA_ "Fehlerwert" SG_ 980 BH_Blinker_Fehler 1;
BA_ "GenSigActiveRepetitions" SG_ 980 BH_Blinker_li 5;
BA_ "GenSigSendType" SG_ 980 BH_Blinker_li 4;
BA_ "GenSigSwitchedByIgnition" SG_ 980 BH_Blinker_li 0;
BA_ "GenSigActiveRepetitions" SG_ 980 BH_Blinker_re 5;
BA_ "GenSigSendType" SG_ 980 BH_Blinker_re 4;
BA_ "GenSigSwitchedByIgnition" SG_ 980 BH_Blinker_re 0;
BA_ "GenSigSendType" SG_ 980 BH_Fernlicht 3;
BA_ "GenSigSwitchedByIgnition" SG_ 980 BH_Fernlicht 0;
BA_ "GenSigActiveRepetitions" SG_ 980 BH_Lichthupe 5;
BA_ "GenSigSendType" SG_ 980 BH_Lichthupe 4;
BA_ "GenSigSwitchedByIgnition" SG_ 980 BH_Lichthupe 0;
BA_ "GenSigSendType" SG_ 980 FAS_Taster 3;
BA_ "GenSigSwitchedByIgnition" SG_ 980 FAS_Taster 0;
BA_ "GenSigSendType" SG_ 980 FAS_Taster_Fehler 3;
BA_ "GenSigSwitchedByIgnition" SG_ 980 FAS_Taster_Fehler 0;
BA_ "Fehlerwert" SG_ 980 FAS_Taster_Fehler 1;
BA_ "GenSigSendType" SG_ 980 LRH_aktiv 3;
BA_ "GenSigSwitchedByIgnition" SG_ 980 LRH_aktiv 0;
BA_ "GenSigSendType" SG_ 980 LRH_on_off 3;
BA_ "GenSigSwitchedByIgnition" SG_ 980 LRH_on_off 0;
BA_ "Fehlerwert" SG_ 980 LRH_on_off 3;
BA_ "GenSigSendType" SG_ 980 SMLS_01_BZ 0;
BA_ "GenSigFuncType" SG_ 980 SMLS_01_BZ 1;
BA_ "GenSigSwitchedByIgnition" SG_ 980 SMLS_01_BZ 0;
BA_ "GenSigSendType" SG_ 980 SMLS_01_CRC 0;
BA_ "GenSigFuncType" SG_ 980 SMLS_01_CRC 2;
BA_ "GenSigSwitchedByIgnition" SG_ 980 SMLS_01_CRC 0;
BA_ "GenSigActiveRepetitions" SG_ 980 SMLS_Hupe 5;
BA_ "GenSigSendType" SG_ 980 SMLS_Hupe 4;
BA_ "GenSigSwitchedByIgnition" SG_ 980 SMLS_Hupe 0;
BA_ "GenSigSendType" SG_ 980 SMLS_P_verriegelt_plausibel 3;
BA_ "GenSigSwitchedByIgnition" SG_ 980 SMLS_P_verriegelt_plausibel 0;
BA_ "GenSigActiveRepetitions" SG_ 980 SMLS_PTT 5;
BA_ "GenSigSendType" SG_ 980 SMLS_PTT 4;
BA_ "GenSigSendType" SG_ 980 WH_Frontwaschen 3;
BA_ "GenSigSwitchedByIgnition" SG_ 980 WH_Frontwaschen 0;
BA_ "GenSigSendType" SG_ 980 WH_Heckintervall 3;
BA_ "GenSigSwitchedByIgnition" SG_ 980 WH_Heckintervall 0;
BA_ "GenSigSendType" SG_ 980 WH_Heckwaschen 3;
BA_ "GenSigSwitchedByIgnition" SG_ 980 WH_Heckwaschen 0;
BA_ "GenSigSendType" SG_ 980 WH_Intervall 3;
BA_ "GenSigSwitchedByIgnition" SG_ 980 WH_Intervall 0;
BA_ "GenSigSendType" SG_ 980 WH_Intervallstufen 3;
BA_ "GenSigSwitchedByIgnition" SG_ 980 WH_Intervallstufen 0;
BA_ "Fehlerwert" SG_ 980 WH_Intervallstufen 15;
BA_ "GenSigMissingSourceValue" SG_ 980 WH_Intervallstufen 15;
BA_ "GenSigActiveRepetitions" SG_ 980 WH_SRA 5;
BA_ "GenSigSendType" SG_ 980 WH_SRA 4;
BA_ "GenSigSwitchedByIgnition" SG_ 980 WH_SRA 0;
BA_ "GenSigActiveRepetitions" SG_ 980 WH_Tipwischen 5;
BA_ "GenSigSendType" SG_ 980 WH_Tipwischen 4;
BA_ "GenSigSwitchedByIgnition" SG_ 980 WH_Tipwischen 0;
BA_ "GenSigActiveRepetitions" SG_ 980 WH_Tipwischen_lang 5;
BA_ "GenSigSendType" SG_ 980 WH_Tipwischen_lang 4;
BA_ "GenSigSwitchedByIgnition" SG_ 980 WH_Tipwischen_lang 0;
BA_ "GenSigSendType" SG_ 980 WH_Wischer_Fehler 3;
BA_ "GenSigSwitchedByIgnition" SG_ 980 WH_Wischer_Fehler 0;
BA_ "Fehlerwert" SG_ 980 WH_Wischer_Fehler 1;
BA_ "GenSigSendType" SG_ 980 WH_WischerStufe1 3;
BA_ "GenSigSwitchedByIgnition" SG_ 980 WH_WischerStufe1 0;
BA_ "GenSigSendType" SG_ 980 WH_WischerStufe2 3;
BA_ "GenSigSwitchedByIgnition" SG_ 980 WH_WischerStufe2 0;
BA_ "GenSigActiveRepetitions" SG_ 1710 SP_abklappen 5;
BA_ "GenSigSendType" SG_ 1710 SP_abklappen 4;
BA_ "GenSigSwitchedByIgnition" SG_ 1710 SP_abklappen 0;
BA_ "GenSigActiveRepetitions" SG_ 1710 SP_anklappen 5;
BA_ "GenSigSendType" SG_ 1710 SP_anklappen 4;
BA_ "GenSigSwitchedByIgnition" SG_ 1710 SP_anklappen 0;
BA_ "GenSigSendType" SG_ 1710 SP_ARA_Status 0;
BA_ "GenSigActiveRepetitions" SG_ 1710 SP_Auswahl_li 5;
BA_ "GenSigSendType" SG_ 1710 SP_Auswahl_li 4;
BA_ "GenSigSwitchedByIgnition" SG_ 1710 SP_Auswahl_li 0;
BA_ "GenSigActiveRepetitions" SG_ 1710 SP_Auswahl_re 5;
BA_ "GenSigSendType" SG_ 1710 SP_Auswahl_re 4;
BA_ "GenSigSwitchedByIgnition" SG_ 1710 SP_Auswahl_re 0;
BA_ "GenSigActiveRepetitions" SG_ 1710 SP_BT_links 5;
BA_ "GenSigSendType" SG_ 1710 SP_BT_links 4;
BA_ "GenSigSwitchedByIgnition" SG_ 1710 SP_BT_links 0;
BA_ "GenSigActiveRepetitions" SG_ 1710 SP_BT_oben 5;
BA_ "GenSigSendType" SG_ 1710 SP_BT_oben 4;
BA_ "GenSigSwitchedByIgnition" SG_ 1710 SP_BT_oben 0;
BA_ "GenSigActiveRepetitions" SG_ 1710 SP_BT_rechts 5;
BA_ "GenSigSendType" SG_ 1710 SP_BT_rechts 4;
BA_ "GenSigSwitchedByIgnition" SG_ 1710 SP_BT_rechts 0;
BA_ "GenSigActiveRepetitions" SG_ 1710 SP_BT_unten 5;
BA_ "GenSigSendType" SG_ 1710 SP_BT_unten 4;
BA_ "GenSigSwitchedByIgnition" SG_ 1710 SP_BT_unten 0;
BA_ "GenSigActiveRepetitions" SG_ 1710 SP_FT_links 5;
BA_ "GenSigSendType" SG_ 1710 SP_FT_links 4;
BA_ "GenSigSwitchedByIgnition" SG_ 1710 SP_FT_links 0;
BA_ "GenSigActiveRepetitions" SG_ 1710 SP_FT_oben 5;
BA_ "GenSigSendType" SG_ 1710 SP_FT_oben 4;
BA_ "GenSigSwitchedByIgnition" SG_ 1710 SP_FT_oben 0;
BA_ "GenSigActiveRepetitions" SG_ 1710 SP_FT_rechts 5;
BA_ "GenSigSendType" SG_ 1710 SP_FT_rechts 4;
BA_ "GenSigSwitchedByIgnition" SG_ 1710 SP_FT_rechts 0;
BA_ "GenSigActiveRepetitions" SG_ 1710 SP_FT_unten 5;
BA_ "GenSigSendType" SG_ 1710 SP_FT_unten 4;
BA_ "GenSigSwitchedByIgnition" SG_ 1710 SP_FT_unten 0;
BA_ "GenSigSendType" SG_ 1710 SP_Hzg_Taster 3;
BA_ "GenSigSwitchedByIgnition" SG_ 1710 SP_Hzg_Taster 0;
BA_ "GenSigActiveRepetitions" SG_ 1710 SP_normieren 5;
BA_ "GenSigSendType" SG_ 1710 SP_normieren 4;
BA_ "GenSigSwitchedByIgnition" SG_ 1710 SP_normieren 0;
BA_ "GenSigActiveRepetitions" SG_ 1710 SP_S_Klappen 5;
BA_ "GenSigSendType" SG_ 1710 SP_S_Klappen 4;
BA_ "GenSigSwitchedByIgnition" SG_ 1710 SP_S_Klappen 0;
BA_ "GenSigActiveRepetitions" SG_ 1710 SP_S_links 5;
BA_ "GenSigSendType" SG_ 1710 SP_S_links 4;
BA_ "GenSigSwitchedByIgnition" SG_ 1710 SP_S_links 0;
BA_ "GenSigActiveRepetitions" SG_ 1710 SP_S_oben 5;
BA_ "GenSigSendType" SG_ 1710 SP_S_oben 4;
BA_ "GenSigSwitchedByIgnition" SG_ 1710 SP_S_oben 0;
BA_ "GenSigActiveRepetitions" SG_ 1710 SP_S_rechts 5;
BA_ "GenSigSendType" SG_ 1710 SP_S_rechts 4;
BA_ "GenSigSwitchedByIgnition" SG_ 1710 SP_S_rechts 0;
BA_ "GenSigActiveRepetitions" SG_ 1710 SP_S_unten 5;
BA_ "GenSigSendType" SG_ 1710 SP_S_unten 4;
BA_ "GenSigSwitchedByIgnition" SG_ 1710 SP_S_unten 0;
BA_ "GenSigSendType" SG_ 1710 SP_Verstellschalter_Fehler 0;
BA_ "Fehlerwert" SG_ 1710 SP_Verstellschalter_Fehler 1;
BA_ "GenSigSendType" SG_ 1313 STH_EKP_Anst 0;
BA_ "GenSigSwitchedByIgnition" SG_ 1313 STH_EKP_Anst 0;
BA_ "GenSigSendType" SG_ 1313 STH_Fehler_ElWaPu 0;
BA_ "GenSigSwitchedByIgnition" SG_ 1313 STH_Fehler_ElWaPu 0;
BA_ "Fehlerwert" SG_ 1313 STH_Fehler_ElWaPu 1;
BA_ "GenSigSendType" SG_ 1313 STH_Fehlerstatus 0;
BA_ "GenSigSwitchedByIgnition" SG_ 1313 STH_Fehlerstatus 0;
BA_ "GenSigSendType" SG_ 1313 STH_Funk_aus 0;
BA_ "GenSigSwitchedByIgnition" SG_ 1313 STH_Funk_aus 0;
BA_ "GenSigSendType" SG_ 1313 STH_Funk_ein 0;
BA_ "GenSigSwitchedByIgnition" SG_ 1313 STH_Funk_ein 0;
BA_ "GenSigSendType" SG_ 1313 STH_Geblaese 0;
BA_ "GenSigSwitchedByIgnition" SG_ 1313 STH_Geblaese 0;
BA_ "GenSigSendType" SG_ 1313 STH_Heizleistung 0;
BA_ "GenSigSwitchedByIgnition" SG_ 1313 STH_Heizleistung 0;
BA_ "GenSigSendType" SG_ 1313 STH_KL_HUP 0;
BA_ "GenSigSwitchedByIgnition" SG_ 1313 STH_KL_HUP 0;
BA_ "GenSigSendType" SG_ 1313 STH_KVS 0;
BA_ "GenSigSwitchedByIgnition" SG_ 1313 STH_KVS 0;
BA_ "GenSigSendType" SG_ 1313 STH_KVS_Ueberlauf 0;
BA_ "GenSigSwitchedByIgnition" SG_ 1313 STH_KVS_Ueberlauf 0;
BA_ "GenSigSendType" SG_ 1313 STH_LED 0;
BA_ "GenSigSwitchedByIgnition" SG_ 1313 STH_LED 0;
BA_ "GenSigSendType" SG_ 1313 STH_Motorvorwaermung 0;
BA_ "GenSigSwitchedByIgnition" SG_ 1313 STH_Motorvorwaermung 0;
BA_ "GenSigSendType" SG_ 1313 STH_Pumpe_ein 0;
BA_ "GenSigSwitchedByIgnition" SG_ 1313 STH_Pumpe_ein 0;
BA_ "GenSigSendType" SG_ 1313 STH_Pumpen_Anf_extern 0;
BA_ "GenSigSwitchedByIgnition" SG_ 1313 STH_Pumpen_Anf_extern 0;
BA_ "GenSigSendType" SG_ 1313 STH_Servicemode 0;
BA_ "GenSigSwitchedByIgnition" SG_ 1313 STH_Servicemode 0;
BA_ "GenSigSendType" SG_ 1313 STH_SH_ZH 0;
BA_ "GenSigSwitchedByIgnition" SG_ 1313 STH_SH_ZH 0;
BA_ "GenSigSendType" SG_ 1313 STH_Start_folgt 0;
BA_ "GenSigSwitchedByIgnition" SG_ 1313 STH_Start_folgt 0;
BA_ "GenSigSendType" SG_ 1313 STH_Texte 0;
BA_ "GenSigSwitchedByIgnition" SG_ 1313 STH_Texte 0;
BA_ "GenSigSendType" SG_ 1313 STH_Ventil_Status 0;
BA_ "GenSigSwitchedByIgnition" SG_ 1313 STH_Ventil_Status 0;
BA_ "GenSigSendType" SG_ 1313 STH_Ventiloeffnungszeit 0;
BA_ "GenSigSwitchedByIgnition" SG_ 1313 STH_Ventiloeffnungszeit 0;
BA_ "GenSigSendType" SG_ 1313 STH_Waermeeintrag 0;
BA_ "GenSigSwitchedByIgnition" SG_ 1313 STH_Waermeeintrag 0;
BA_ "GenSigSendType" SG_ 1313 STH_war_aktiv 0;
BA_ "GenSigSwitchedByIgnition" SG_ 1313 STH_war_aktiv 0;
BA_ "GenSigSendType" SG_ 1313 STH_Wassertemp 0;
BA_ "GenSigStartValue" SG_ 1313 STH_Wassertemp 254;
BA_ "GenSigSwitchedByIgnition" SG_ 1313 STH_Wassertemp 0;
BA_ "Fehlerwert" SG_ 1313 STH_Wassertemp 255;
BA_ "GenSigSendType" SG_ 1313 STH_Zusatzheizung 0;
BA_ "GenSigSwitchedByIgnition" SG_ 1313 STH_Zusatzheizung 0;
BA_REL_ "GenSigTimeoutTime" BU_SG_REL_ E_Sound SG_ 424 SARA_Accel_X_r 500;
BA_REL_ "GenSigTimeoutTime" BU_SG_REL_ FLA SG_ 1122 PSD_Segment_ID 1500;
BA_REL_ "GenSigTimeoutTime" BU_SG_REL_ FLA SG_ 1122 PSD_Vorgaenger_Segment_ID 1500;
BA_REL_ "GenSigTimeoutTime" BU_SG_REL_ FLA SG_ 1122 PSD_Segmentlaenge 1500;
BA_REL_ "GenSigTimeoutTime" BU_SG_REL_ FLA SG_ 1122 PSD_Strassenkategorie 1500;
BA_REL_ "GenSigTimeoutTime" BU_SG_REL_ FLA SG_ 1122 PSD_Endkruemmung 1500;
BA_REL_ "GenSigTimeoutTime" BU_SG_REL_ FLA SG_ 1122 PSD_Endkruemmung_Vorz 1500;
BA_REL_ "GenSigTimeoutTime" BU_SG_REL_ FLA SG_ 1122 PSD_Idenditaets_ID 1500;
BA_REL_ "GenSigTimeoutTime" BU_SG_REL_ FLA SG_ 1122 PSD_ADAS_Qualitaet 1500;
BA_REL_ "GenSigTimeoutTime" BU_SG_REL_ FLA SG_ 1122 PSD_wahrscheinlichster_Pfad 1500;
BA_REL_ "GenSigTimeoutTime" BU_SG_REL_ FLA SG_ 1122 PSD_Geradester_Pfad 1500;
BA_REL_ "GenSigTimeoutTime" BU_SG_REL_ FLA SG_ 1122 PSD_Fahrspuren_Anzahl 1500;
BA_REL_ "GenSigTimeoutTime" BU_SG_REL_ FLA SG_ 1122 PSD_Bebauung 1500;
BA_REL_ "GenSigTimeoutTime" BU_SG_REL_ FLA SG_ 1122 PSD_Segment_Komplett 1500;
BA_REL_ "GenSigTimeoutTime" BU_SG_REL_ FLA SG_ 1122 PSD_Rampe 1500;
BA_REL_ "GenSigTimeoutTime" BU_SG_REL_ FLA SG_ 1122 PSD_Anfangskruemmung 1500;
BA_REL_ "GenSigTimeoutTime" BU_SG_REL_ FLA SG_ 1122 PSD_Anfangskruemmung_Vorz 1500;
BA_REL_ "GenSigTimeoutTime" BU_SG_REL_ FLA SG_ 1122 PSD_Abzweigewinkel 1500;
BA_REL_ "GenSigTimeoutTime" BU_SG_REL_ FLA SG_ 1123 PSD_Pos_Segment_ID 1500;
BA_REL_ "GenSigTimeoutTime" BU_SG_REL_ FLA SG_ 1123 PSD_Pos_Segmentlaenge 1500;
BA_REL_ "GenSigTimeoutTime" BU_SG_REL_ FLA SG_ 1123 PSD_Pos_Inhibitzeit 1500;
BA_REL_ "GenSigTimeoutTime" BU_SG_REL_ FLA SG_ 1123 PSD_Pos_Standort_Eindeutig 1500;
BA_REL_ "GenSigTimeoutTime" BU_SG_REL_ FLA SG_ 1123 PSD_Pos_Fehler_Laengsrichtung 1500;
BA_REL_ "GenSigTimeoutTime" BU_SG_REL_ FLA SG_ 1123 PSD_Pos_Fahrspur 1500;
BA_REL_ "GenSigTimeoutTime" BU_SG_REL_ FLA SG_ 1123 PSD_Attribut_Segment_ID_05 1500;
BA_REL_ "GenSigTimeoutTime" BU_SG_REL_ FLA SG_ 1123 PSD_Attribut_1_Wert 1500;
BA_REL_ "GenSigTimeoutTime" BU_SG_REL_ FLA SG_ 1123 PSD_Attribut_1_Offset 1500;
BA_REL_ "GenSigTimeoutTime" BU_SG_REL_ FLA SG_ 1123 PSD_Attribut_2_ID 1500;
BA_REL_ "GenSigTimeoutTime" BU_SG_REL_ FLA SG_ 1123 PSD_Attribut_2_Wert 1500;
BA_REL_ "GenSigTimeoutTime" BU_SG_REL_ FLA SG_ 1123 PSD_Attribut_2_Offset 1500;
BA_REL_ "GenSigTimeoutTime" BU_SG_REL_ FLA SG_ 1123 PSD_Attribute_Komplett_05 1500;
BA_REL_ "GenSigTimeoutTime" BU_SG_REL_ FLA SG_ 1124 PSD_Sys_Segment_ID 1500;
BA_REL_ "GenSigTimeoutTime" BU_SG_REL_ FLA SG_ 1124 PSD_Attribut_Segment_ID 1500;
BA_REL_ "GenSigTimeoutTime" BU_SG_REL_ FLA SG_ 1124 PSD_Ges_Segment_ID 1500;
BA_REL_ "GenSigTimeoutTime" BU_SG_REL_ FLA SG_ 1124 PSD_Baum_Laenge_VZ 1500;
BA_REL_ "GenSigTimeoutTime" BU_SG_REL_ FLA SG_ 1124 PSD_Steigung_1_Segment_ID 1500;
BA_REL_ "GenSigTimeoutTime" BU_SG_REL_ FLA SG_ 1124 PSD_Baum_Laenge 1500;
BA_REL_ "GenSigTimeoutTime" BU_SG_REL_ FLA SG_ 1124 PSD_Sys_Laendercode 1500;
BA_REL_ "GenSigTimeoutTime" BU_SG_REL_ FLA SG_ 1124 PSD_Attribut_3_ID 1500;
BA_REL_ "GenSigTimeoutTime" BU_SG_REL_ FLA SG_ 1124 PSD_Ges_Offset 1500;
BA_REL_ "GenSigTimeoutTime" BU_SG_REL_ FLA SG_ 1124 PSD_Steigung_1_A_Steigung 1500;
BA_REL_ "GenSigTimeoutTime" BU_SG_REL_ FLA SG_ 1124 PSD_Attribut_3_Offset 1500;
BA_REL_ "GenSigTimeoutTime" BU_SG_REL_ FLA SG_ 1124 PSD_Ges_Geschwindigkeit 1500;
BA_REL_ "GenSigTimeoutTime" BU_SG_REL_ FLA SG_ 1124 PSD_Steigung_1_A_Vorz 1500;
BA_REL_ "GenSigTimeoutTime" BU_SG_REL_ FLA SG_ 1124 PSD_Sys_Geschwindigkeit_Einheit 1500;
BA_REL_ "GenSigTimeoutTime" BU_SG_REL_ FLA SG_ 1124 PSD_Steigung_1_A_Offset 1500;
BA_REL_ "GenSigTimeoutTime" BU_SG_REL_ FLA SG_ 1124 PSD_Sys_Verkehrsrichtung 1500;
BA_REL_ "GenSigTimeoutTime" BU_SG_REL_ FLA SG_ 1124 PSD_Sys_Geometrieguete 1500;
BA_REL_ "GenSigTimeoutTime" BU_SG_REL_ FLA SG_ 1124 PSD_Sys_Mapmatchingguete 1500;
BA_REL_ "GenSigTimeoutTime" BU_SG_REL_ FLA SG_ 1124 PSD_Attribut_3_Wert 1500;
BA_REL_ "GenSigTimeoutTime" BU_SG_REL_ FLA SG_ 1124 PSD_Ges_Typ 1500;
BA_REL_ "GenSigTimeoutTime" BU_SG_REL_ FLA SG_ 1124 PSD_Sys_Alter_Karte 1500;
BA_REL_ "GenSigTimeoutTime" BU_SG_REL_ FLA SG_ 1124 PSD_Ges_Spur_Geschw_Begrenzung 1500;
BA_REL_ "GenSigTimeoutTime" BU_SG_REL_ FLA SG_ 1124 PSD_Steigung_1_B_Steigung 1500;
BA_REL_ "GenSigTimeoutTime" BU_SG_REL_ FLA SG_ 1124 PSD_Attribut_4_ID 1500;
BA_REL_ "GenSigTimeoutTime" BU_SG_REL_ FLA SG_ 1124 PSD_Sys_Zielfuehrung 1500;
BA_REL_ "GenSigTimeoutTime" BU_SG_REL_ FLA SG_ 1124 PSD_Sys_US_State 1500;
BA_REL_ "GenSigTimeoutTime" BU_SG_REL_ FLA SG_ 1124 PSD_Ges_Geschwindigkeit_Gespann 1500;
BA_REL_ "GenSigTimeoutTime" BU_SG_REL_ FLA SG_ 1124 PSD_Baum_Breite_VZ 1500;
BA_REL_ "GenSigTimeoutTime" BU_SG_REL_ FLA SG_ 1124 PSD_Attribut_4_Wert 1500;
BA_REL_ "GenSigTimeoutTime" BU_SG_REL_ FLA SG_ 1124 PSD_Baum_Breite 1500;
BA_REL_ "GenSigTimeoutTime" BU_SG_REL_ FLA SG_ 1124 PSD_Ges_Geschwindigkeit_Witter 1500;
BA_REL_ "GenSigTimeoutTime" BU_SG_REL_ FLA SG_ 1124 PSD_Steigung_1_B_Vorz 1500;
BA_REL_ "GenSigTimeoutTime" BU_SG_REL_ FLA SG_ 1124 PSD_Steigung_1_B_Offset 1500;
BA_REL_ "GenSigTimeoutTime" BU_SG_REL_ FLA SG_ 1124 PSD_Sys_Quali_Geometrien 1500;
BA_REL_ "GenSigTimeoutTime" BU_SG_REL_ FLA SG_ 1124 PSD_Ges_Geschwindigkeit_Tag_Anf 1500;
BA_REL_ "GenSigTimeoutTime" BU_SG_REL_ FLA SG_ 1124 PSD_Attribut_4_Offset 1500;
BA_REL_ "GenSigTimeoutTime" BU_SG_REL_ FLA SG_ 1124 PSD_Sys_Quali_Ortsinfo 1500;
BA_REL_ "GenSigTimeoutTime" BU_SG_REL_ FLA SG_ 1124 PSD_Ges_Geschwindigkeit_Tag_Ende 1500;
BA_REL_ "GenSigTimeoutTime" BU_SG_REL_ FLA SG_ 1124 PSD_Sys_Quali_verfuegbar 1500;
BA_REL_ "GenSigTimeoutTime" BU_SG_REL_ FLA SG_ 1124 PSD_Sys_Zielfuehrung_geaendert 1500;
BA_REL_ "GenSigTimeoutTime" BU_SG_REL_ FLA SG_ 1124 PSD_Ges_Geschwindigkeit_Std_Anf 1500;
BA_REL_ "GenSigTimeoutTime" BU_SG_REL_ FLA SG_ 1124 PSD_Steigung_1_Attribute_kompl 1500;
BA_REL_ "GenSigTimeoutTime" BU_SG_REL_ FLA SG_ 1124 PSD_Sys_Geometrieguete_erweitert 1500;
BA_REL_ "GenSigTimeoutTime" BU_SG_REL_ FLA SG_ 1124 PSD_Steigung_2_Segment_ID 1500;
BA_REL_ "GenSigTimeoutTime" BU_SG_REL_ FLA SG_ 1124 PSD_Attribut_5_ID 1500;
BA_REL_ "GenSigTimeoutTime" BU_SG_REL_ FLA SG_ 1124 PSD_Ges_Geschwindigkeit_Std_Ende 1500;
BA_REL_ "GenSigTimeoutTime" BU_SG_REL_ FLA SG_ 1124 PSD_Attribut_5_Offset 1500;
BA_REL_ "GenSigTimeoutTime" BU_SG_REL_ FLA SG_ 1124 PSD_Steigung_2_Steigung 1500;
BA_REL_ "GenSigTimeoutTime" BU_SG_REL_ FLA SG_ 1124 PSD_Sys_Quali_sonstige_Attribute 1500;
BA_REL_ "GenSigTimeoutTime" BU_SG_REL_ FLA SG_ 1124 PSD_Ges_Ueberholverbot 1500;
BA_REL_ "GenSigTimeoutTime" BU_SG_REL_ FLA SG_ 1124 PSD_Sys_Quali_Steigungen 1500;
BA_REL_ "GenSigTimeoutTime" BU_SG_REL_ FLA SG_ 1124 PSD_Ges_Wechselverkehrszeichen 1500;
BA_REL_ "GenSigTimeoutTime" BU_SG_REL_ FLA SG_ 1124 PSD_Attribut_5_Wert 1500;
BA_REL_ "GenSigTimeoutTime" BU_SG_REL_ FLA SG_ 1124 PSD_Steigung_2_Vorz 1500;
BA_REL_ "GenSigTimeoutTime" BU_SG_REL_ FLA SG_ 1124 PSD_Sys_Quali_Strassenkennz 1500;
BA_REL_ "GenSigTimeoutTime" BU_SG_REL_ FLA SG_ 1124 PSD_Wechselverkehrszeichen_Typ 1500;
BA_REL_ "GenSigTimeoutTime" BU_SG_REL_ FLA SG_ 1124 PSD_Baum_Ausrichtung 1500;
BA_REL_ "GenSigTimeoutTime" BU_SG_REL_ FLA SG_ 1124 PSD_Steigung_2_Offset 1500;
BA_REL_ "GenSigTimeoutTime" BU_SG_REL_ FLA SG_ 1124 PSD_Ges_Gesetzlich_Kategorie 1500;
BA_REL_ "GenSigTimeoutTime" BU_SG_REL_ FLA SG_ 1124 PSD_Sys_Quali_Tempolimits 1500;
BA_REL_ "GenSigTimeoutTime" BU_SG_REL_ FLA SG_ 1124 PSD_Attribute_Komplett_06 1500;
BA_REL_ "GenSigTimeoutTime" BU_SG_REL_ FLA SG_ 1124 PSD_Ges_Gesetzlich_Zusatz 1500;
BA_REL_ "GenSigTimeoutTime" BU_SG_REL_ FLA SG_ 1124 PSD_Sys_Quali_Vorfahrtsregelung 1500;
BA_REL_ "GenSigTimeoutTime" BU_SG_REL_ FLA SG_ 1124 PSD_Ges_Verkehrszeichen_Quelle 1500;
BA_REL_ "GenSigTimeoutTime" BU_SG_REL_ FLA SG_ 1124 PSD_Steigung_2_Attribute_kompl 1500;
BA_REL_ "GenSigTimeoutTime" BU_SG_REL_ FLA SG_ 1124 PSD_Ges_Attribute_Komplett 1500;
BA_REL_ "GenSigTimeoutTime" BU_SG_REL_ FLA SG_ 424 SARA_Omega_Z_r 500;
BA_REL_ "GenSigTimeoutTime" BU_SG_REL_ FLA SG_ 424 SARA_CF_Omega_Z_r 500;
BA_REL_ "GenSigTimeoutTime" BU_SG_REL_ FLA SG_ 980 BH_Fernlicht 2000;
BA_REL_ "GenSigTimeoutTime" BU_SG_REL_ Gateway SG_ 1529 RDK_Warnungen_02 3200;
BA_REL_ "GenSigTimeoutTime" BU_SG_REL_ Gateway SG_ 1528 SAK_Charisma_FahrPr 5000;
BA_REL_ "GenSigTimeoutTime" BU_SG_REL_ Gateway SG_ 1528 SAK_Charisma_Status 5000;
BA_REL_ "GenSigTimeoutTime" BU_SG_REL_ Gateway SG_ 1011 SCR_Sent_Level_Aktivtank 1000;
BA_REL_ "GenSigTimeoutTime" BU_SG_REL_ Gateway SG_ 1507 SCR_Heizkreis_3_Strom 5000;
BA_REL_ "GenSigTimeoutTime" BU_SG_REL_ Gateway SG_ 1507 SCR_Leitungsheizung_Strom 5000;
BA_REL_ "GenSigTimeoutTime" BU_SG_REL_ Gateway SG_ 1507 SCR_Tankheizung_Strom 5000;
BA_REL_ "GenSigTimeoutTime" BU_SG_REL_ Gateway SG_ 1313 STH_Zusatzheizung 2000;
BA_REL_ "GenSigTimeoutTime" BU_SG_REL_ Gateway SG_ 1313 STH_LED 2000;
BA_REL_ "GenSigTimeoutTime" BU_SG_REL_ Gateway SG_ 1313 STH_Heizleistung 2000;
BA_REL_ "GenSigTimeoutTime" BU_SG_REL_ Gateway_PAG SG_ 1529 RDK_Warnungen_02 3200;
BA_REL_ "GenSigTimeoutTime" BU_SG_REL_ Gateway_PAG SG_ 1528 SAK_Charisma_FahrPr 5000;
BA_REL_ "GenSigTimeoutTime" BU_SG_REL_ Gateway_PAG SG_ 1528 SAK_Charisma_Status 5000;
BA_REL_ "GenSigTimeoutTime" BU_SG_REL_ Gateway_PAG SG_ 1011 SCR_Sent_Level_Aktivtank 1000;
BA_REL_ "GenSigTimeoutTime" BU_SG_REL_ Gateway_PAG SG_ 1507 SCR_Heizkreis_3_Strom 5000;
BA_REL_ "GenSigTimeoutTime" BU_SG_REL_ Gateway_PAG SG_ 1507 SCR_Leitungsheizung_Strom 5000;
BA_REL_ "GenSigTimeoutTime" BU_SG_REL_ Gateway_PAG SG_ 1507 SCR_Tankheizung_Strom 5000;
BA_REL_ "GenSigTimeoutTime" BU_SG_REL_ Gateway_PAG SG_ 1313 STH_Zusatzheizung 2000;
BA_REL_ "GenSigTimeoutTime" BU_SG_REL_ Gateway_PAG SG_ 1313 STH_LED 2000;
BA_REL_ "GenSigTimeoutTime" BU_SG_REL_ Gateway_PAG SG_ 1313 STH_Heizleistung 2000;
BA_REL_ "GenSigTimeoutTime" BU_SG_REL_ ISE SG_ 424 SARA_Accel_X_r 500;
BA_REL_ "GenSigTimeoutTime" BU_SG_REL_ NightVision SG_ 2527679498 Perso_Kontonummer 5000;
BA_REL_ "GenSigTimeoutTime" BU_SG_REL_ NightVision SG_ 2527679498 Perso_Steuerung 5000;
BA_REL_ "GenSigTimeoutTime" BU_SG_REL_ NightVision SG_ 2527679498 Perso_Steuerungsparameter 5000;
BA_REL_ "GenSigTimeoutTime" BU_SG_REL_ NightVision SG_ 2527679498 Perso_Status 5000;
BA_REL_ "GenSigTimeoutTime" BU_SG_REL_ NightVision SG_ 319 SC_PreSense_FCWP 2000;
BA_REL_ "GenSigTimeoutTime" BU_SG_REL_ NightVision SG_ 319 SC_PreCrash_Warnung 2000;
BA_REL_ "GenSigTimeoutTime" BU_SG_REL_ NightVision SG_ 1122 PSD_Segment_ID 1500;
BA_REL_ "GenSigTimeoutTime" BU_SG_REL_ NightVision SG_ 1122 PSD_Vorgaenger_Segment_ID 1500;
BA_REL_ "GenSigTimeoutTime" BU_SG_REL_ NightVision SG_ 1122 PSD_Segmentlaenge 1500;
BA_REL_ "GenSigTimeoutTime" BU_SG_REL_ NightVision SG_ 1122 PSD_Strassenkategorie 1500;
BA_REL_ "GenSigTimeoutTime" BU_SG_REL_ NightVision SG_ 1122 PSD_Endkruemmung 1500;
BA_REL_ "GenSigTimeoutTime" BU_SG_REL_ NightVision SG_ 1122 PSD_Endkruemmung_Vorz 1500;
BA_REL_ "GenSigTimeoutTime" BU_SG_REL_ NightVision SG_ 1122 PSD_Idenditaets_ID 1500;
BA_REL_ "GenSigTimeoutTime" BU_SG_REL_ NightVision SG_ 1122 PSD_ADAS_Qualitaet 1500;
BA_REL_ "GenSigTimeoutTime" BU_SG_REL_ NightVision SG_ 1122 PSD_wahrscheinlichster_Pfad 1500;
BA_REL_ "GenSigTimeoutTime" BU_SG_REL_ NightVision SG_ 1122 PSD_Geradester_Pfad 1500;
BA_REL_ "GenSigTimeoutTime" BU_SG_REL_ NightVision SG_ 1122 PSD_Fahrspuren_Anzahl 1500;
BA_REL_ "GenSigTimeoutTime" BU_SG_REL_ NightVision SG_ 1122 PSD_Bebauung 1500;
BA_REL_ "GenSigTimeoutTime" BU_SG_REL_ NightVision SG_ 1122 PSD_Segment_Komplett 1500;
BA_REL_ "GenSigTimeoutTime" BU_SG_REL_ NightVision SG_ 1122 PSD_Rampe 1500;
BA_REL_ "GenSigTimeoutTime" BU_SG_REL_ NightVision SG_ 1122 PSD_Anfangskruemmung 1500;
BA_REL_ "GenSigTimeoutTime" BU_SG_REL_ NightVision SG_ 1122 PSD_Anfangskruemmung_Vorz 1500;
BA_REL_ "GenSigTimeoutTime" BU_SG_REL_ NightVision SG_ 1122 PSD_Abzweigerichtung 1500;
BA_REL_ "GenSigTimeoutTime" BU_SG_REL_ NightVision SG_ 1122 PSD_Abzweigewinkel 1500;
BA_REL_ "GenSigTimeoutTime" BU_SG_REL_ NightVision SG_ 1123 PSD_Pos_Segment_ID 1500;
BA_REL_ "GenSigTimeoutTime" BU_SG_REL_ NightVision SG_ 1123 PSD_Pos_Segmentlaenge 1500;
BA_REL_ "GenSigTimeoutTime" BU_SG_REL_ NightVision SG_ 1123 PSD_Pos_Inhibitzeit 1500;
BA_REL_ "GenSigTimeoutTime" BU_SG_REL_ NightVision SG_ 1123 PSD_Pos_Standort_Eindeutig 1500;
BA_REL_ "GenSigTimeoutTime" BU_SG_REL_ NightVision SG_ 1123 PSD_Pos_Fehler_Laengsrichtung 1500;
BA_REL_ "GenSigTimeoutTime" BU_SG_REL_ NightVision SG_ 1123 PSD_Pos_Fahrspur 1500;
BA_REL_ "GenSigTimeoutTime" BU_SG_REL_ NightVision SG_ 1123 PSD_Attribut_Segment_ID_05 1500;
BA_REL_ "GenSigTimeoutTime" BU_SG_REL_ NightVision SG_ 1123 PSD_Attribut_1_ID 1500;
BA_REL_ "GenSigTimeoutTime" BU_SG_REL_ NightVision SG_ 1123 PSD_Attribut_1_Wert 1500;
BA_REL_ "GenSigTimeoutTime" BU_SG_REL_ NightVision SG_ 1123 PSD_Attribut_1_Offset 1500;
BA_REL_ "GenSigTimeoutTime" BU_SG_REL_ NightVision SG_ 1123 PSD_Attribut_2_ID 1500;
BA_REL_ "GenSigTimeoutTime" BU_SG_REL_ NightVision SG_ 1123 PSD_Attribut_2_Wert 1500;
BA_REL_ "GenSigTimeoutTime" BU_SG_REL_ NightVision SG_ 1123 PSD_Attribut_2_Offset 1500;
BA_REL_ "GenSigTimeoutTime" BU_SG_REL_ NightVision SG_ 1123 PSD_Attribute_Komplett_05 1500;
BA_REL_ "GenSigTimeoutTime" BU_SG_REL_ NightVision SG_ 1124 PSD_06_Mux 1500;
BA_REL_ "GenSigTimeoutTime" BU_SG_REL_ NightVision SG_ 1124 PSD_Sys_Segment_ID 1500;
BA_REL_ "GenSigTimeoutTime" BU_SG_REL_ NightVision SG_ 1124 PSD_Attribut_Segment_ID 1500;
BA_REL_ "GenSigTimeoutTime" BU_SG_REL_ NightVision SG_ 1124 PSD_Ges_Segment_ID 1500;
BA_REL_ "GenSigTimeoutTime" BU_SG_REL_ NightVision SG_ 1124 PSD_Baum_Laenge_VZ 1500;
BA_REL_ "GenSigTimeoutTime" BU_SG_REL_ NightVision SG_ 1124 PSD_Steigung_1_Segment_ID 1500;
BA_REL_ "GenSigTimeoutTime" BU_SG_REL_ NightVision SG_ 1124 PSD_Baum_Laenge 1500;
BA_REL_ "GenSigTimeoutTime" BU_SG_REL_ NightVision SG_ 1124 PSD_Sys_Laendercode 1500;
BA_REL_ "GenSigTimeoutTime" BU_SG_REL_ NightVision SG_ 1124 PSD_Attribut_3_ID 1500;
BA_REL_ "GenSigTimeoutTime" BU_SG_REL_ NightVision SG_ 1124 PSD_Ges_Offset 1500;
BA_REL_ "GenSigTimeoutTime" BU_SG_REL_ NightVision SG_ 1124 PSD_Steigung_1_A_Steigung 1500;
BA_REL_ "GenSigTimeoutTime" BU_SG_REL_ NightVision SG_ 1124 PSD_Attribut_3_Offset 1500;
BA_REL_ "GenSigTimeoutTime" BU_SG_REL_ NightVision SG_ 1124 PSD_Ges_Geschwindigkeit 1500;
BA_REL_ "GenSigTimeoutTime" BU_SG_REL_ NightVision SG_ 1124 PSD_Steigung_1_A_Vorz 1500;
BA_REL_ "GenSigTimeoutTime" BU_SG_REL_ NightVision SG_ 1124 PSD_Sys_Geschwindigkeit_Einheit 1500;
BA_REL_ "GenSigTimeoutTime" BU_SG_REL_ NightVision SG_ 1124 PSD_Steigung_1_A_Offset 1500;
BA_REL_ "GenSigTimeoutTime" BU_SG_REL_ NightVision SG_ 1124 PSD_Sys_Verkehrsrichtung 1500;
BA_REL_ "GenSigTimeoutTime" BU_SG_REL_ NightVision SG_ 1124 PSD_Sys_Geometrieguete 1500;
BA_REL_ "GenSigTimeoutTime" BU_SG_REL_ NightVision SG_ 1124 PSD_Sys_Mapmatchingguete 1500;
BA_REL_ "GenSigTimeoutTime" BU_SG_REL_ NightVision SG_ 1124 PSD_Attribut_3_Wert 1500;
BA_REL_ "GenSigTimeoutTime" BU_SG_REL_ NightVision SG_ 1124 PSD_Ges_Typ 1500;
BA_REL_ "GenSigTimeoutTime" BU_SG_REL_ NightVision SG_ 1124 PSD_Sys_Alter_Karte 1500;
BA_REL_ "GenSigTimeoutTime" BU_SG_REL_ NightVision SG_ 1124 PSD_Ges_Spur_Geschw_Begrenzung 1500;
BA_REL_ "GenSigTimeoutTime" BU_SG_REL_ NightVision SG_ 1124 PSD_Steigung_1_B_Steigung 1500;
BA_REL_ "GenSigTimeoutTime" BU_SG_REL_ NightVision SG_ 1124 PSD_Attribut_4_ID 1500;
BA_REL_ "GenSigTimeoutTime" BU_SG_REL_ NightVision SG_ 1124 PSD_Sys_Zielfuehrung 1500;
BA_REL_ "GenSigTimeoutTime" BU_SG_REL_ NightVision SG_ 1124 PSD_Sys_US_State 1500;
BA_REL_ "GenSigTimeoutTime" BU_SG_REL_ NightVision SG_ 1124 PSD_Ges_Geschwindigkeit_Gespann 1500;
BA_REL_ "GenSigTimeoutTime" BU_SG_REL_ NightVision SG_ 1124 PSD_Baum_Breite_VZ 1500;
BA_REL_ "GenSigTimeoutTime" BU_SG_REL_ NightVision SG_ 1124 PSD_Attribut_4_Wert 1500;
BA_REL_ "GenSigTimeoutTime" BU_SG_REL_ NightVision SG_ 1124 PSD_Baum_Breite 1500;
BA_REL_ "GenSigTimeoutTime" BU_SG_REL_ NightVision SG_ 1124 PSD_Ges_Geschwindigkeit_Witter 1500;
BA_REL_ "GenSigTimeoutTime" BU_SG_REL_ NightVision SG_ 1124 PSD_Steigung_1_B_Vorz 1500;
BA_REL_ "GenSigTimeoutTime" BU_SG_REL_ NightVision SG_ 1124 PSD_Steigung_1_B_Offset 1500;
BA_REL_ "GenSigTimeoutTime" BU_SG_REL_ NightVision SG_ 1124 PSD_Sys_Quali_Geometrien 1500;
BA_REL_ "GenSigTimeoutTime" BU_SG_REL_ NightVision SG_ 1124 PSD_Ges_Geschwindigkeit_Tag_Anf 1500;
BA_REL_ "GenSigTimeoutTime" BU_SG_REL_ NightVision SG_ 1124 PSD_Attribut_4_Offset 1500;
BA_REL_ "GenSigTimeoutTime" BU_SG_REL_ NightVision SG_ 1124 PSD_Sys_Quali_Ortsinfo 1500;
BA_REL_ "GenSigTimeoutTime" BU_SG_REL_ NightVision SG_ 1124 PSD_Ges_Geschwindigkeit_Tag_Ende 1500;
BA_REL_ "GenSigTimeoutTime" BU_SG_REL_ NightVision SG_ 1124 PSD_Sys_Quali_verfuegbar 1500;
BA_REL_ "GenSigTimeoutTime" BU_SG_REL_ NightVision SG_ 1124 PSD_Sys_Zielfuehrung_geaendert 1500;
BA_REL_ "GenSigTimeoutTime" BU_SG_REL_ NightVision SG_ 1124 PSD_Ges_Geschwindigkeit_Std_Anf 1500;
BA_REL_ "GenSigTimeoutTime" BU_SG_REL_ NightVision SG_ 1124 PSD_Steigung_1_Attribute_kompl 1500;
BA_REL_ "GenSigTimeoutTime" BU_SG_REL_ NightVision SG_ 1124 PSD_Sys_Geometrieguete_erweitert 1500;
BA_REL_ "GenSigTimeoutTime" BU_SG_REL_ NightVision SG_ 1124 PSD_Steigung_2_Segment_ID 1500;
BA_REL_ "GenSigTimeoutTime" BU_SG_REL_ NightVision SG_ 1124 PSD_Attribut_5_ID 1500;
BA_REL_ "GenSigTimeoutTime" BU_SG_REL_ NightVision SG_ 1124 PSD_Ges_Geschwindigkeit_Std_Ende 1500;
BA_REL_ "GenSigTimeoutTime" BU_SG_REL_ NightVision SG_ 1124 PSD_Attribut_5_Offset 1500;
BA_REL_ "GenSigTimeoutTime" BU_SG_REL_ NightVision SG_ 1124 PSD_Steigung_2_Steigung 1500;
BA_REL_ "GenSigTimeoutTime" BU_SG_REL_ NightVision SG_ 1124 PSD_Sys_Quali_sonstige_Attribute 1500;
BA_REL_ "GenSigTimeoutTime" BU_SG_REL_ NightVision SG_ 1124 PSD_Ges_Ueberholverbot 1500;
BA_REL_ "GenSigTimeoutTime" BU_SG_REL_ NightVision SG_ 1124 PSD_Sys_Quali_Steigungen 1500;
BA_REL_ "GenSigTimeoutTime" BU_SG_REL_ NightVision SG_ 1124 PSD_Ges_Wechselverkehrszeichen 1500;
BA_REL_ "GenSigTimeoutTime" BU_SG_REL_ NightVision SG_ 1124 PSD_Attribut_5_Wert 1500;
BA_REL_ "GenSigTimeoutTime" BU_SG_REL_ NightVision SG_ 1124 PSD_Steigung_2_Vorz 1500;
BA_REL_ "GenSigTimeoutTime" BU_SG_REL_ NightVision SG_ 1124 PSD_Sys_Quali_Strassenkennz 1500;
BA_REL_ "GenSigTimeoutTime" BU_SG_REL_ NightVision SG_ 1124 PSD_Wechselverkehrszeichen_Typ 1500;
BA_REL_ "GenSigTimeoutTime" BU_SG_REL_ NightVision SG_ 1124 PSD_Baum_Ausrichtung 1500;
BA_REL_ "GenSigTimeoutTime" BU_SG_REL_ NightVision SG_ 1124 PSD_Steigung_2_Offset 1500;
BA_REL_ "GenSigTimeoutTime" BU_SG_REL_ NightVision SG_ 1124 PSD_Ges_Gesetzlich_Kategorie 1500;
BA_REL_ "GenSigTimeoutTime" BU_SG_REL_ NightVision SG_ 1124 PSD_Sys_Quali_Tempolimits 1500;
BA_REL_ "GenSigTimeoutTime" BU_SG_REL_ NightVision SG_ 1124 PSD_Attribute_Komplett_06 1500;
BA_REL_ "GenSigTimeoutTime" BU_SG_REL_ NightVision SG_ 1124 PSD_Ges_Gesetzlich_Zusatz 1500;
BA_REL_ "GenSigTimeoutTime" BU_SG_REL_ NightVision SG_ 1124 PSD_Sys_Quali_Vorfahrtsregelung 1500;
BA_REL_ "GenSigTimeoutTime" BU_SG_REL_ NightVision SG_ 1124 PSD_Ges_Verkehrszeichen_Quelle 1500;
BA_REL_ "GenSigTimeoutTime" BU_SG_REL_ NightVision SG_ 1124 PSD_Steigung_2_Attribute_kompl 1500;
BA_REL_ "GenSigTimeoutTime" BU_SG_REL_ NightVision SG_ 1124 PSD_Ges_Attribute_Komplett 1500;
BA_REL_ "GenSigTimeoutTime" BU_SG_REL_ NightVision SG_ 1440 LS_Helligkeit_IR 2000;
BA_REL_ "GenSigTimeoutTime" BU_SG_REL_ NightVision SG_ 1440 LS_Helligkeit_FW 2000;
BA_REL_ "GenSigTimeoutTime" BU_SG_REL_ NightVision SG_ 1440 LS_defekt 2000;
BA_REL_ "GenSigTimeoutTime" BU_SG_REL_ NightVision SG_ 1440 LS_Verbau 2000;
BA_REL_ "GenSigTimeoutTime" BU_SG_REL_ NightVision SG_ 1440 RS_Verbau 2000;
BA_REL_ "GenSigTimeoutTime" BU_SG_REL_ NightVision SG_ 1440 RS_defekt 2000;
BA_REL_ "GenSigTimeoutTime" BU_SG_REL_ NightVision SG_ 1440 RS_Wischergeschwindigkeit 2000;
BA_REL_ "GenSigTimeoutTime" BU_SG_REL_ NightVision SG_ 424 SARA_Omega_Z_r 500;
BA_REL_ "GenSigTimeoutTime" BU_SG_REL_ NightVision SG_ 424 SARA_CF_Omega_Z_r 500;
BA_REL_ "GenSigTimeoutTime" BU_SG_REL_ TopView SG_ 1355 PH_Aufschaltursache 5000;
BA_REL_ "GenSigTimeoutTime" BU_SG_REL_ TopView SG_ 424 SARA_Accel_X_r 500;
BA_REL_ "GenSigTimeoutTime" BU_SG_REL_ TopView SG_ 424 SARA_Accel_Y_r 500;
BA_REL_ "GenSigTimeoutTime" BU_SG_REL_ TopView SG_ 424 SARA_Omega_Z_r 500;
BA_REL_ "GenSigTimeoutTime" BU_SG_REL_ TopView SG_ 424 SARA_CF_Accel_X_r 500;
BA_REL_ "GenSigTimeoutTime" BU_SG_REL_ TopView SG_ 424 SARA_CF_Accel_Y_r 500;
BA_REL_ "GenSigTimeoutTime" BU_SG_REL_ TopView SG_ 424 SARA_CF_Omega_Z_r 500;
BA_REL_ "GenSigTimeoutTime" BU_SG_REL_ TopView SG_ 980 BH_Blinker_li 2000;
BA_REL_ "GenSigTimeoutTime" BU_SG_REL_ TopView SG_ 980 BH_Blinker_re 2000;
BA_REL_ "GenSigTimeoutTime" BU_SG_REL_ TopView SG_ 1710 SP_S_Klappen 5000;
VAL_ 1355 PH_Verschmutzungsmeldung 0 "keine_Anzeige_kein_Gong" 1 "Textmeldung_PDC_hinten_verschmutzt_mit_Gong" 2 "Textmeldung_PDC_hinten_verschmutzt_ohne_Gong" 3 "Textmeldung_PDC_vorn_verschmutzt_mit_Gong" 4 "Textmeldung_PDC_vorn_verschmutzt_ohne_Gong" 5 "Textmeldung_PDC_verschmutzt_mit_Gong" 6 "Textmeldung_PDC_verschmutzt_ohne_Gong" 7 "Textmeldung_PDC_seitlich_verschmutzt_mit_Gong" 8 "Textmeldung_PDC_seitlich_verschmutzt_ohne_Gong" ;
VAL_ 1355 PH_Aufschaltursache 0 "Anlage aus" 1 "Anlage durch einlegen R-Gang aktiviert" 2 "Anlage manuell durch Taster aktiviert" 3 "Anlage automatisch aktiviert" 4 "Anlage durch ARA aktiviert" 5 "Rueckwaertsrollen" 6 "Anlage_durch_PLA_aktiviert" 7 "Anlage_durch_IPA_aktiviert" 8 "Anlage_durch_FA_aktiviert" 9 "Anlage_durch_RBF_oder_MA_aktiviert" 10 "Anlage_durch_Smartphone_aktiviert" 11 "Anlage_durch_Jokertaste_aktiviert" 12 "Anlage_durch_Favoritentasten_aktiviert" 13 "Anlage_durch_SideViewTaster_aktiviert" 14 "Anlage_durch_RCTA_aktiviert" 15 "Anlage_durch_KAS_aktiviert" 16 "Anlage_durch_AWC_aktiviert" 30 "Init_Initialisierungsphase_nach_Kl_15_ein_oder_Reset" 31 "Fehler_gestoerter_Zustand_System_noch_aktiv" ;
VAL_ 1355 PH_Ton_Ausgabe 0 "Init" 1 "Intervallton_vorne" 2 "Intervallton_hinten" 3 "Dauerton_vorne" 4 "Dauerton_hinten" 5 "Quittierungston" 6 "Reserviert" 7 "Fehler" ;
VAL_ 1355 PH_Ton_Pausenlaenge 0 "Init" 1 "Pause_5ms" 2 "Pause_10ms" 3 "Pause_15ms" 100 "Pause_500ms" 101 "Reserviert" 126 "Reserviert" 127 "Fehler" ;
VAL_ 1355 PH_Ton_Richtung 0 "vorne" 1 "vorne_rechts" 2 "rechts" 3 "rechts_hinten" 4 "hinten" 5 "hinten_links" 6 "links" 7 "vorne_links" ;
VAL_ 1355 PH_Ton_Lautstaerke 0 "Minimallautstaerke" 1 "Lautstaerke_1" 2 "Lautstaerke_2" 3 "Lautstaerke_3" 4 "Lautstaerke_4" 5 "Lautstaerke_5" 6 "Lautstaerke_6" 7 "Maximallautstaerke" ;
VAL_ 1355 BCM_WAH_Meldung 0 "Init" 1 "Fehlermeldung_bei_Nichtverfuegbarkeit_mit_Gong" 2 "Fehlermeldung_bei_Nichtverfuegbarkeit_ohne_Gong" 3 "Anzeige_dass_Fahrzeug_erkannt_wurde_und_Funktion_aktiv_ist" 4 "Wiederanfahrhinweis_mit_Gong" 5 "Wiederanfahrhinweis_ohne_Gong" ;
VAL_ 1355 PDC_Charisma_Status 0 "Init" 1 "verfuegbar" 2 "nicht_verfuegbar" 3 "asynchron_durch_Fahrerwunsch" ;
VAL_ 1355 PDC_Charisma_FahrPr 0 "keine_Funktion" 1 "Programm_1" 2 "Programm_2" 3 "Programm_3" 4 "Programm_4" 5 "Programm_5" 6 "Programm_6" 7 "Programm_7" 8 "Programm_8" 9 "Programm_9" 10 "Programm_10" 11 "Programm_11" 12 "Programm_12" 13 "Programm_13" 14 "Programm_14" 15 "Programm_15" ;
VAL_ 2527679498 Perso_Kontonummer 0 "kein_Benutzerkonto" 1 "Benutzerkonto_1" 2 "Benutzerkonto_2" 3 "Benutzerkonto_3" 4 "Benutzerkonto_4" 5 "Benutzerkonto_5" 6 "Benutzerkonto_6" 7 "Benutzerkonto_7" ;
VAL_ 2527679498 Perso_Steuerung 0 "keine_Steuerung" 1 "Reset_alle_Konten" 2 "Reset_aktives_Konto" 3 "Kopiere_aktives_Konto_nach" 4 "Wiederherstellen_aktives_Konto" 5 "Aktivieren_aktives_Konto" 6 "Reset_Konto" 7 "Reset_alle_Fahrer" 8 "Reset_aktiver_Fahrer" 9 "Reset_Fahrer" ;
VAL_ 2527679498 Perso_Steuerungsparameter 0 "kein_Parameter" 1 "Benutzerkonto_1" 2 "Benutzerkonto_2" 3 "Benutzerkonto_3" 4 "Benutzerkonto_4" 5 "Benutzerkonto_5" 6 "Benutzerkonto_6" 7 "Benutzerkonto_7" ;
VAL_ 2527679498 Perso_Status 0 "deaktiviert" 1 "PSO_1x_aktiviert" 2 "PSO_2x_aktiviert" ;
VAL_ 2527679498 Perso_Bedienstelle 0 "Init" 1 "Kombiinstrument" 2 "ABT" ;
VAL_ 2527679498 Perso_Freigabe_Verstellung 0 "Init" 1 "freigegeben" ;
VAL_ 2527679498 Perso_Aktiv 0 "deaktiviert" 1 "aktiviert" ;
VAL_ 2527679498 IAA_PSO_wake_up 0 "wake_up_inactive" 1 "wake_up_active" ;
VAL_ 2527679498 Perso_Fahrernummer 0 "kein_Fahrer" 1 "Fahrer_1" 2 "Fahrer_2" 3 "Fahrer_3" 4 "Fahrer_4" 5 "Fahrer_5" 6 "Fahrer_6" 7 "Fahrer_7" ;
VAL_ 2527679498 Perso_Schreibschutz 0 "Schreibschutz_deaktiviert" 1 "Schreibschutz_aktiviert" ;
VAL_ 319 PreCrash_Charisma_FahrPr 0 "keine_Funktion" 1 "Programm_1" 2 "Programm_2" 3 "Programm_3" 4 "Programm_4" 5 "Programm_5" 6 "Programm_6" 7 "Programm_7" 8 "Programm_8" 9 "Programm_9" 10 "Programm_10" 11 "Programm_11" 12 "Programm_12" 13 "Programm_13" 14 "Programm_14" 15 "Programm_15" ;
VAL_ 319 PreCrash_Charisma_Status 0 "Init" 1 "verfuegbar" 2 "nicht_verfuegbar" 3 "asynchron_durch_Fahrerwunsch" ;
VAL_ 319 PreCrash_Schiebedach_schliessen 0 "keine_Schliessung" 1 "Schliessung_angefordert" ;
VAL_ 319 PreCrash_Fenster_schliessen 0 "keine_Schliessung" 1 "Schliessung_angefordert" ;
VAL_ 319 PreCrash_Blinken 0 "keine_Blinkanforderung" 1 "Warnblinken" 2 "RECAS_Blinken" 3 "Notbremsblinken" ;
VAL_ 319 SC_PreSense_FCWP 0 "Warnung_gilt_fuer_Objekte" 1 "Warnung_gitl_fuer_Fussgaenger" ;
VAL_ 319 PreCrash_Tueren_Verriegeln 0 "keine_Anforderung" 1 "Tueren_Verriegeln" ;
VAL_ 319 PreCrash_Anforderung_AFR 0 "keine_Anforderung" 1 "linke_Seite" 2 "rechte_Seite" 3 "Vorderachse" 4 "Hinterachse" 5 "Vorwarnung" 7 "Init" ;
VAL_ 319 SC_PreCrash_LED 0 "keine_Anzeige" 1 "Stufe_1_glimmen" 2 "Stufe_2_leuchten" 3 "Stufe_3_blinken" ;
VAL_ 319 PreCrash_FS_Pneumatik_ansteuern 0 "keine_Anforderung" 1 "Pneumatik_ansteuern" ;
VAL_ 319 PreCrash_BFS_Pneumatik_ansteuern 0 "keine_Anforderung" 1 "Pneumatik_ansteuern" ;
VAL_ 319 PreCrash_Fo_Pneumatik_ansteuern 0 "keine_Anforderung" 1 "Pneumatik_ansteuern" ;
VAL_ 319 PreCrash_FS_Sitzlehne_verfahren 0 "keine_Anforderung" 1 "Sitzlehne_in_pos_x-Richtung_verfahren(vor)" 2 "Sitzlehne_in_neg_x-Richtung_verfahren(zurueck)" 3 "Sitzlehnenkopf_in_pos_x-Richtung_verfahren(vor)" 4 "Sitzlehnenkopf_in_neg_x-Richtung_verfahren(zurueck)" 6 "Lehnenverstellung_ansteuern" 7 "Lehnenkopfverstellung_ansteuern" ;
VAL_ 319 PreCrash_BFS_Sitzlehne_verfahren 0 "keine_Anforderung" 1 "Sitzlehne_in_pos_x-Richtung_verfahren(vor)" 2 "Sitzlehne_in_neg_x-Richtung_verfahren(zurueck)" 3 "Sitzlehnenkopf_in_pos_x-Richtung_verfahren(vor)" 4 "Sitzlehnenkopf_in_neg_x-Richtung_verfahren(zurueck)" 6 "Lehnenverstellung_ansteuern" 7 "Lehnenkopfverstellung_ansteuern" ;
VAL_ 319 PreCrash_Fo_Sitzlehne_verfahren 0 "keine_Anforderung" 1 "Sitzlehne_in_pos_x-Richtung_verfahren(vor)" 2 "Sitzlehne_in_neg_x-Richtung_verfahren(zurueck)" 3 "Sitzlehnenkopf_in_pos_x-Richtung_verfahren(vor)" 4 "Sitzlehnenkopf_in_neg_x-Richtung_verfahren(zurueck)" ;
VAL_ 319 PreCrash_FS_KSV_verfahren 0 "keine_Anforderung" 1 "in_pos_x-Richtung_verfahren" 2 "in_neg_x-Richung_verfahren" 3 "in_pos_z-Richtung_verfahren" 4 "in_neg_z-Richtung_verfahren" 5 "in_pos_x-Richtung_und_neg_z-Richtung_verfahren" 6 "in_pos_x_Richtung_und_pos_z-Richtung_verfahren" 7 "in_neg_x-Richtung_und_neg_z-Richtung_verfahren" 8 "in_neg_x-Richtung_und_pos_z-Richtung_verfahren" 9 "Kopfstuetze_ansteuern" ;
VAL_ 319 PreCrash_BFS_KSV_verfahren 0 "keine_Anforderung" 1 "in_pos_x-Richtung_verfahren" 2 "in_neg_x-Richung_verfahren" 3 "in_pos_z-Richtung_verfahren" 4 "in_neg_z-Richtung_verfahren" 5 "in_pos_x-Richtung_und_neg_z-Richtung_verfahren" 6 "in_pos_x_Richtung_und_pos_z-Richtung_verfahren" 7 "in_neg_x-Richtung_und_neg_z-Richtung_verfahren" 8 "in_neg_x-Richtung_und_pos_z-Richtung_verfahren" 9 "Kopfstuetze_ansteuern" ;
VAL_ 319 PreCrash_Fo_KSV_verfahren 0 "keine_Anforderung" 1 "in_pos_x-Richtung_verfahren" 2 "in_neg_x-Richung_verfahren" 3 "in_pos_z-Richtung_verfahren" 4 "in_neg_z-Richtung_verfahren" 5 "in_pos_x-Richtung_und_neg_z-Richtung_verfahren" 6 "in_pos_x_Richtung_und_pos_z-Richtung_verfahren" 7 "in_neg_x-Richtung_und_neg_z-Richtung_verfahren" 8 "in_neg_x-Richtung_und_pos_z-Richtung_verfahren" ;
VAL_ 319 SC_PreCrash_Warnung 0 "keine_Anzeige" 1 "latente_Vorwarnung" 2 "Vorwarnung" 3 "Akutwarnung" 4 "Eingriff" 5 "Fahreruebernahmeaufforderung" 6 "Abbiegewarnung" 7 "Basiseingriff" 8 "Heckeingriff" ;
VAL_ 319 SC_PreCrash_Texte 0 "keine_Anzeige" 1 "Systemstoerung" 2 "keine_Sensorsicht" 3 "Demomodus" 4 "System_aus" 5 "Anhaengerbetrieb" 6 "ESC_aus" 7 "zurzeit_eingeschraenkt" 8 "zurzeit_eingeschraenkt_ESP_Aus" 9 "Initialisierung" ;
VAL_ 1122 PSD_Segment_ID 0 "keine Segmentinformationen vorhanden" 1 "Fehlerwert" ;
VAL_ 1122 PSD_Vorgaenger_Segment_ID 0 "keine Segmentinformation vorhanden" 1 "Fehlerwert" ;
VAL_ 1122 PSD_Strassenkategorie 0 "Rest_Feldweg_Schotterweg_Privatweg" 1 "Ortsstraße" 2 "Kreisstraße" 3 "Landstraße" 4 "Bundesstraße" 5 "Autobahn" 7 "Init" ;
VAL_ 1122 PSD_Endkruemmung 255 "Gerade" ;
VAL_ 1122 PSD_Endkruemmung_Vorz 0 "Kruemmung_positiv" 1 "Kruemmung_negativ" ;
VAL_ 1122 PSD_Idenditaets_ID 0 "keine_Segment_Informationen_vorhanden" 1 "Fehler" ;
VAL_ 1122 PSD_ADAS_Qualitaet 0 "keine_ADAS_Qualitaet" 1 "ADAS_Qualitaet" ;
VAL_ 1122 PSD_wahrscheinlichster_Pfad 0 "Pfad_mit_geringer_Wahrscheinlichkeit" 1 "wahrscheinlichster_Pfad" ;
VAL_ 1122 PSD_Geradester_Pfad 0 "nicht_geradester_PFad" 1 "geradester_Pfad" ;
VAL_ 1122 PSD_Fahrspuren_Anzahl 0 "Einbahnstrasse_in_falsche_Richtung" 1 "eine_Fahrspur" 2 "zwei_Fahrspuren" 3 "drei_Fahrspuren" 4 "vier_Fahrspuren" 5 "fuenf_Fahrspuren" 6 "sechs_Fahrspuren" 7 "mehr_als_sechs_Fahrspuren" ;
VAL_ 1122 PSD_Bebauung 0 "ausserhalb_bebauten_Gebietes" 1 "innerhalb_bebauten_Gebietes" ;
VAL_ 1122 PSD_Segment_Komplett 0 "Segment_Attribute_nicht_komplett" 1 "Segment_Attribute_komplett" ;
VAL_ 1122 PSD_Rampe 0 "Strasse_mit_Gegenverkehr" 1 "Auffahrt_Einbahnstr" 2 "Abfahrt_Einbahnstr" 3 "Einbahnstrasse" ;
VAL_ 1122 PSD_Anfangskruemmung 255 "Gerade" ;
VAL_ 1122 PSD_Anfangskruemmung_Vorz 0 "positiv" 1 "negativ" ;
VAL_ 1122 PSD_Abzweigerichtung 0 "rects_abzweigende_Strasse" 1 "links_abzweigende_Strasse" ;
VAL_ 1123 PSD_Pos_Segment_ID 0 "keine Position gegeben" 1 "Fehlerwert" ;
VAL_ 1123 PSD_Pos_Standort_Eindeutig 0 "mehrdeutiger_Standort" 1 "eindeutiger_Standort" ;
VAL_ 1123 PSD_Pos_Fehler_Laengsrichtung 0 "Init" 1 "< 2m" 2 "< 5m" 3 "< 10m" 4 "< 20m" 5 "< 50m" 6 "> 50m" 7 "Off-Road" ;
VAL_ 1123 PSD_Pos_Fahrspur 0 "unbekannt" 1 "Erste_Spur_von_rechts" 2 "Zweite_Spur_von_rechts" 3 "Dritte_Spur_von_rechts" 4 "Vierte_Spur_von_rechts" 5 "Fuenfte_Spur_von_rechts" 6 "Sechte_Spur_von_rechts" 7 "Siebte_oder_weitere_Spur_von_rechts" ;
VAL_ 1123 PSD_Attribut_Segment_ID_05 0 "keine_Segment_Information" 1 "Fehler" ;
VAL_ 1123 PSD_Attribut_1_ID 0 "keine_Information" ;
VAL_ 1123 PSD_Attribut_2_ID 0 "keine_Information" ;
VAL_ 1123 PSD_Attribute_Komplett_05 0 "Attribute_nicht_komplett" 1 "Attribute_komplett" ;
VAL_ 1124 PSD_06_Mux 0 "Init" ;
VAL_ 1124 PSD_Sys_Segment_ID 0 "keine Segmentinformationen vorhanden" 1 "nicht zulaessig" ;
VAL_ 1124 PSD_Attribut_Segment_ID 0 "keine_Segment_Information_vorhanden" 1 "Fehler" ;
VAL_ 1124 PSD_Ges_Segment_ID 0 "keine Segmentinformationen vorhanden" 1 "nicht zulaessig" ;
VAL_ 1124 PSD_Baum_Laenge_VZ 0 "Ost" 1 "West" ;
VAL_ 1124 PSD_Steigung_1_Segment_ID 0 "keine_Segment_Information_vorhanden" 1 "Fehler" ;
VAL_ 1124 PSD_Baum_Laenge 33554431 "keine_GPS_Information" ;
VAL_ 1124 PSD_Attribut_3_ID 0 "keine_Information" ;
VAL_ 1124 PSD_Steigung_1_A_Steigung 126 "mehr_als_15_Prozent" 127 "Steigung_unbekannt" ;
VAL_ 1124 PSD_Ges_Geschwindigkeit 0 "Kein Geschwindigkeitsgebot" 1 "0 km/h < v_max <  5 km/h" 2 "5 km/h < v_max < 10km/h" 3 "10 km/h < v_max < 15 km/h" 4 "15 km/h < v_max < 20 km/h" 5 "20 km/h < v_max < 25 km/h" 6 "25 km/h < v_max < 30 km/h" 7 "30 km/h < v_max < 35 km/h" 8 "35 km/h < v_max < 40 km/h" 9 "40 km/h < v_max < 45 km/h" 10 "45 km/h < v_max < 50 km/h" 11 "50 km/h < v_max < 60 km/h" 12 "60 km/h < v_max < 70 km/h" 13 "70 km/h < v_max < 80 km/h" 14 "80 km/h < v_max < 90 km/h" 15 "90 km/h < v_max < 100 km/h" 16 "100 km/h < v_max < 110 km/h" 17 "110 km/h < v_max < 120 km/h" 18 " 120 km/h < v_max < 130 km/h" 19 "130 km/h < v_max < 140 km/h" 20 "140 km/h < v_max < 150 km/h" 21 "150 km/h < v_max < 160 km/h" 22 "160 km/h < v_max" 23 "Geschwindigkeitsgebot aufgehoben" 24 "..0x1F ungültig" ;
VAL_ 1124 PSD_Steigung_1_A_Vorz 0 "Gefaelle" 1 "Steigung" ;
VAL_ 1124 PSD_Sys_Geschwindigkeit_Einheit 0 "km/h" 1 "mph" ;
VAL_ 1124 PSD_Sys_Verkehrsrichtung 0 "Rechtsverkehr" 1 "Linksverkehr" ;
VAL_ 1124 PSD_Sys_Geometrieguete 0 "Geringe_Guete" 1 "tbd" 2 "tbd" 3 "Hohe_Guete" ;
VAL_ 1124 PSD_Sys_Mapmatchingguete 0 "geringe_Guete" 1 "res" 2 "res" 3 "hohe_Guete" ;
VAL_ 1124 PSD_Ges_Typ 0 "Geschw_Klasse_des_Kartendatensuppliers" 1 "Explizit_abgeleiteten_Begrenzung" 2 "Durch_Gesetzg_vorgeg_allgem_Gebot_fuer_uebertr_Rahmenbed" 3 "Init" ;
VAL_ 1124 PSD_Sys_Alter_Karte 0 "kleiner_1_Jahr" 1 "1_Jahr" 2 "2_Jahre" 3 "3_Jahre" 4 "4_Jahre" 5 "5_Jahre" 6 "6_Jahre" 7 "groesser_7_Jahre" ;
VAL_ 1124 PSD_Ges_Spur_Geschw_Begrenzung 0 "Gebot_fuer_alle_spuren_gueltig" ;
VAL_ 1124 PSD_Steigung_1_B_Steigung 126 "mehr_als_15_Prozent" 127 "Steigung_unbekannt" ;
VAL_ 1124 PSD_Attribut_4_ID 0 "keine_Information" ;
VAL_ 1124 PSD_Sys_Zielfuehrung 0 "Zielfuehrung nicht aktiv" 1 "Zielfuehrung aktiv" ;
VAL_ 1124 PSD_Sys_US_State 0 "kein_US_State" 1 "Alabama" 2 "Alaska" 3 "Arkansas" 4 "Arizona" 5 "California" 6 "Colorado" 7 "Conneticut" 8 "District_of_Columbia" 9 "Delaware" 10 "Florida" 11 "Georgia" 12 "Hawaii" 13 "Idaho" 14 "Illinois" 15 "Iowa" 16 "Indiana" 17 "Kansas" 18 "Kentucky" 19 "Louisiana" 20 "Massachusetts" 21 "Maryland" 22 "Maine" 23 "Michigan" 24 "Minnesota" 25 "Missouri" 26 "Mississippi" 27 "Montana" 28 "North_Carolina" 29 "North_Dakota" 30 "Nebraska" 31 "Nevada" 32 "New_Hampshire" 33 "New_Jersey" 34 "New_Mexico" 35 "New_York" 36 "Ohio" 37 "Oklahoma" 38 "Oregon" 39 "Pennsylvania" 40 "Puerto_Rico" 41 "Rhode_Island" 42 "South_Carolina" 43 "South_Dakota" 44 "Tennessee" 45 "Texas" 46 "Utah" 47 "Virginia" 48 "Virgin_Islands" 49 "Vermont" 50 "Washington" 51 "Wisconsin" 52 "West_Virginia" 53 "Wyoming" ;
VAL_ 1124 PSD_Ges_Geschwindigkeit_Gespann 0 "alle Fahrzeuge" 1 "PKW mit Gespann" 2 "LKW, Busse, etc." ;
VAL_ 1124 PSD_Baum_Breite_VZ 0 "Nord" 1 "Sued" ;
VAL_ 1124 PSD_Ges_Geschwindigkeit_Witter 0 "Witterungsunabhängig" 1 "Nässe, Regen, Niederschlag" 2 "Glätte" 3 "Nebel" ;
VAL_ 1124 PSD_Steigung_1_B_Vorz 0 "Gefaelle" 1 "Steigung" ;
VAL_ 1124 PSD_Ges_Geschwindigkeit_Tag_Anf 0 "kein Beginn definiert" 1 "Montag" 2 "Dienstag" 3 "Mittwoch" 4 "Donnerstag" 5 "Freitag" 6 "Samstag" 7 "Sonntag" ;
VAL_ 1124 PSD_Ges_Geschwindigkeit_Tag_Ende 0 "kein Ende definiert" 1 "Montag" 2 "Dienstag" 3 "Mittwoch" 4 "Donnerstag" 5 "Freitag" 6 "Samstag" 7 "Sonntag" ;
VAL_ 1124 PSD_Sys_Quali_verfuegbar 0 "Qualitaetskriterien_nicht_verfuegbar" 1 "Qualitaetskriterien_verfuegbar" ;
VAL_ 1124 PSD_Sys_Zielfuehrung_geaendert 0 "Zielfuehrung_nicht_geaendert" 1 "Zielfuehrung_geaendert" ;
VAL_ 1124 PSD_Ges_Geschwindigkeit_Std_Anf 25 "kein Beginn für stundenweise Einschränkungen" ;
VAL_ 1124 PSD_Steigung_1_Attribute_kompl 0 "Steigungen_nicht_komplett" 1 "Steigungen_komplett" ;
VAL_ 1124 PSD_Sys_Geometrieguete_erweitert 0 "Init" ;
VAL_ 1124 PSD_Steigung_2_Segment_ID 0 "keine_Segment_Information_vorhanden" 1 "Fehler" ;
VAL_ 1124 PSD_Attribut_5_ID 0 "keine_Information" ;
VAL_ 1124 PSD_Ges_Geschwindigkeit_Std_Ende 25 "kein Ende für stundenweise Einschränkungen" ;
VAL_ 1124 PSD_Steigung_2_Steigung 126 "mehr_als_15_Prozent" 127 "Steigung_unbekannt" ;
VAL_ 1124 PSD_Ges_Ueberholverbot 0 "kein Überholverbot" 1 "alle Fahrzeuge" 2 "Überholverbot für PKW mit Gespann" 3 "Überholverbot für LKW, Busse, etc." ;
VAL_ 1124 PSD_Ges_Wechselverkehrszeichen 0 "Kein Wechselverkehrszeichen" 1 "Wechselverkehrszeichen links" 2 "Wechselverkehrszeichen rechts" 3 "Wechselverkehrszeichen links und rechts" 4 "Wechselverkerhszeichen über der Fahrbahn" ;
VAL_ 1124 PSD_Steigung_2_Vorz 0 "Gefaelle" 1 "Steigung" ;
VAL_ 1124 PSD_Wechselverkehrszeichen_Typ 0 "kein_Wechselverkehrszeichen" 1 "LED_Wechselverkehrszeichen" 2 "nicht_LED_Wechselverkehrszeichen" ;
VAL_ 1124 PSD_Ges_Gesetzlich_Kategorie 0 "kein_legales_Verbot" 1 "innerorts" 2 "ausserorts" 3 "Autobahn" ;
VAL_ 1124 PSD_Attribute_Komplett_06 0 "Attribute_nicht_komplett" 1 "Attribute_komplett" ;
VAL_ 1124 PSD_Ges_Gesetzlich_Zusatz 0 "kein_Zusatz_zu_legalem_Gebot" 1 "Anhaenger_Klasse_1" 2 "Anhaenger_Klasse_2" ;
VAL_ 1124 PSD_Ges_Verkehrszeichen_Quelle 0 "VZA_kein_Onlinedienst" 1 "nur_VZA" 2 "nur_VZO" 3 "VZA_und_VZO" ;
VAL_ 1124 PSD_Steigung_2_Attribute_kompl 0 "Steigungen_nicht_komplett" 1 "Steigungen_komplett" ;
VAL_ 1124 PSD_Ges_Attribute_Komplett 0 "Attribute_nicht_komplett" 1 "Attribute_komplett" ;
VAL_ 1529 RDK_FMVSS138_Lampe 0 "RDK_WaLa_inaktiv" 1 "RDK_WaLa_aktiv" ;
VAL_ 1529 RDK_FMVSS138_MIL 0 "keine_Stoerungsanzeige" 1 "Stoerungsanzeige" ;
VAL_ 1529 RDK_Kalibrierung 0 "BAP_Kalibrierung" 1 "CAN_Kombitaster_Kalibrierung" ;
VAL_ 1529 RDK_Reifendruck_Lampe 0 "RDK_WaLa_inaktiv" 1 "RDK_WaLa_aktiv" ;
VAL_ 1529 RDK_Warnungen_02 0 "keine_Anzeige" 1 "Reifen_allgemein_Warnstufe_1" 2 "Reifen_vorne_links_Warnstufe_1" 3 "Reifen_vorne_rechts_Warnstufe_1" 4 "Reifen_hinten_links_Warnstufe_1" 5 "Reifen_hinten_rechts_Warnstufe_1" 6 "Reifen_allgemein_Warnstufe_2" 7 "Reifen_vorne_links_Warnstufe_2" 8 "Reifen_vorne_rechts_Warnstufe_2" 9 "Reifen_hinten_links_Warnstufe_2" 10 "Reifen_hinten_rechts_Warnstufe_2" 11 "Reifen_allgemein_Warnstufe_3" 12 "Reifen_vorne_links_Warnstufe_3" 13 "Reifen_vorne_rechts_Warnstufe_3" 14 "Reifen_hinten_links_Warnstufe_3" 15 "Reifen_hinten_rechts_Warnstufe_3" 16 "Akustikausgabe_Kalibrierung_io" 17 "Textausgabe_Kalibrierung_io" 18 "Akustik_Textausgabe_Kalibrier_io" 19 "RDK_aktiviert" 20 "RDK_deaktiviert" 21 "RDK_Systemstoerung" 22 "RDK_Systemstoerung_temporaer" 23 "V_Warnschwelle_1" 24 "V_Warnschwelle_2" 25 "Radwechsel_allgemein" 26 "Teilueberwachung" 27 "V_Warnschwelle_3" ;
VAL_ 1529 RDK_Reifentemperatur_Lampe 0 "RDK_WaLa_inaktiv" 1 "RDK_WaLa_aktiv" ;
VAL_ 2589283632 RDK_Reifengroesse 0 "Init" 1 "Zoll_16" 2 "Zoll_17" 3 "Zoll_18" 4 "Zoll_19" 5 "Zoll_20" 6 "Zoll_21" 7 "Zoll_22" ;
VAL_ 2589283632 RDK_Reifentyp 0 "Init" 1 "Winter" 2 "Sommer" 3 "Ganzjahresreifen" 4 "Kundenspezifisch" 5 "UHP" 6 "eDistance" 7 "ePerformance" ;
VAL_ 2589283632 RDK_SollDruck_VA 63 "Init" ;
VAL_ 2589283632 RDK_SollDruck_HA 63 "Init" ;
VAL_ 1651 RDK_Druck_VL_unkomp 63 "Init" ;
VAL_ 1651 RDK_Signal_Alter_VL 0 "Signal_ist_aktuell__Init" 1 "kein_neues_Signal_fuer_3_Minuten" 2 "kein_neues_Signal_fuer_6_Minuten" 3 "kein_neues_Signal_fuer_9_Minuten" ;
VAL_ 1651 RDK_Druck_VR_unkomp 63 "Init" ;
VAL_ 1651 RDK_Signal_Alter_VR 0 "Signal_ist_aktuell__Init" 1 "kein_neues_Signal_fuer_3_Minuten" 2 "kein_neues_Signal_fuer_6_Minuten" 3 "kein_neues_Signal_fuer_9_Minuten" ;
VAL_ 1651 RDK_Druck_HL_unkomp 63 "Init" ;
VAL_ 1651 RDK_Signal_Alter_HL 0 "Signal_ist_aktuell__Init" 1 "kein_neues_Signal_fuer_3_Minuten" 2 "kein_neues_Signal_fuer_6_Minuten" 3 "kein_neues_Signal_fuer_9_Minuten" ;
VAL_ 1651 RDK_Druck_HR_unkomp 63 "Init" ;
VAL_ 1651 RDK_Signal_Alter_HR 0 "Signal_ist_aktuell__Init" 1 "kein_neues_Signal_fuer_3_Minuten" 2 "kein_neues_Signal_fuer_6_Minuten" 3 "kein_neues_Signal_fuer_9_Minuten" ;
VAL_ 1651 RDK_R_Temp_VL 254 "Signal_nicht_verfuegbar" 255 "Fehler" ;
VAL_ 1651 RDK_R_Temp_VR 254 "Signal_nicht_verfuegbar" 255 "Fehler" ;
VAL_ 1651 RDK_R_Temp_HL 254 "Signal_nicht_verfuegbar" 255 "Fehler" ;
VAL_ 1651 RDK_R_Temp_HR 254 "Signal_nicht_verfuegbar" 255 "Fehler" ;
VAL_ 1711 RV_Video_on 0 "Kamerabild wird nicht angezeigt" 1 "Kamerabild wird angezeigt" ;
VAL_ 1711 RV_Dark_Screen 0 "Kamerabild nicht verdunkeln" 1 "Kamerabild verdunkeln" ;
VAL_ 1711 RV_HMI_Mode 0 "Parkluecke  (Modus 1)" 1 "Parallel zur Straße (Modus 2)" 2 "reserviert" 3 "Kalibrierung (nur Diagnose)" ;
VAL_ 1711 RV_GL_side 0 "Guidelines_abgeschaltet" 1 "Guidelines_Anzeige_rechte_Seite" 2 "Guiedelines_Anzeige_linke_Seite" 3 "Guiedelines_Anzeige_beide_Seiten" ;
VAL_ 1711 RV_System_aktiv 0 "System nicht betriebsbereit" 1 "System betriebsbereit" ;
VAL_ 1711 RV_Reinigung_Anf 0 "nicht_reinigen" 1 "reinigen" ;
VAL_ 1711 RV_Settings_enabled 0 "Menu 'Einstellungen' nicht aktiviert" 1 "Menu 'Einstellungen' aktiviert" ;
VAL_ 1711 RV_Menu_Item 0 "HMI Mode als ausgewaehlt markiert" 1 "Helligkeit als ausgewaehlt markiert" 2 "Kontrast als ausgewaehlt markiert" 3 "Farbsaettigung als ausgewaehlt markiert" ;
VAL_ 1711 SV_Video_on 0 "SideView_aus_/_nicht_verbaut" 1 "SideView_an" ;
VAL_ 1711 RV_Calib_Fehler 0 "Kalibrierung_i.O." 1 "RearView_nicht_kalibriert" ;
VAL_ 1711 RV_GL_Trailer_connect 0 "Guidelines_werden_angezeigt" 1 "Guidelines_wegen_angekoppeltem_Anhänger_deaktiviert" ;
VAL_ 1711 RV_GL_Trunk_open 0 "Guidelines_werden_angezeigt" 1 "Guidelines_wegen_geöffneter_Heckklappe_deaktiviert" ;
VAL_ 1711 RV_GL_LWS_Fehler 0 "Guidelines_werden_angezeigt" 1 "Guidelines_wegen_nicht_kalibriertem_Lenkwinkelsensor_deaktiviert" ;
VAL_ 1711 ZFAS_Umfeldbeleuchtung_Anf 0 "nicht_angefordert" 1 "angefordert" ;
VAL_ 1440 LS_Helligkeit_IR 254 "Init" 255 "Fehler" ;
VAL_ 1440 LS_Helligkeit_FW 1022 "Init" 1023 "Fehler" ;
VAL_ 1440 LS_defekt 0 "OK" 1 "defekt" ;
VAL_ 1440 LS_Verbau 1 "Lichtsensor verbaut" ;
VAL_ 1440 RS_Regenmenge 14 "Init" 15 "Fehler" ;
VAL_ 1440 RS_Verbau 1 "Regensensor verbaut" ;
VAL_ 1440 RS_Verglasung_schliessen 0 "Verglasung nicht schliessen" 1 "Verglasung schliessen" ;
VAL_ 1440 RS_defekt 0 "OK" 1 "defekt" ;
VAL_ 1440 RS_Wischergeschwindigkeit 0 "kein Wischen" 1 "42 Huebe/min" 2 "45 Huebe/min" 3 "48 Huebe/min" 4 "51 Huebe/min" 5 "54 Huebe/min" 6 "57 Huebe/min" 7 "60 Huebe/min" ;
VAL_ 1440 RLS_Vorfeldhelligkeit_Boost 0 "groesser_24413_Lux" 1 "bis_24413_Lux" 2 "bis_22193_Lux" 3 "bis_20176_Lux" 4 "bis_18342_Lux" 5 "bis_16647_Lux" 6 "bis_15158_Lux" 7 "bis_13780_Lux" 8 "bis_12527_Lux" 9 "bis_11388_Lux" 10 "bis_10353_Lux" 11 "bis_9412_Lux" 12 "bis_8556_Lux" 13 "bis_7778_Lux" 14 "bis_7071_Lux" 15 "bis_6428_Lux" ;
VAL_ 1528 SAK_Charisma_FahrPr 0 "keine_Funktion" 1 "Programm_1" 2 "Programm_2" 3 "Programm_3" 4 "Programm_4" 5 "Programm_5" 6 "Programm_6" 7 "Programm_7" 8 "Programm_8" 9 "Programm_9" 10 "Programm_10" 11 "Programm_11" 12 "Programm_12" 13 "Programm_13" 14 "Programm_14" 15 "Programm_15" ;
VAL_ 1528 SAK_Charisma_Status 0 "Init" 1 "verfuegbar" 2 "nicht_verfuegbar" 3 "asynchron_durch_Fahrerwunsch" ;
VAL_ 424 SARA_Accel_X_r 0 "nicht_verbaut" 8191 "Fehler" ;
VAL_ 424 SARA_Accel_Y_r 0 "nicht_verbaut" 8191 "Fehler" ;
VAL_ 424 SARA_Omega_Z_r 0 "nicht_verbaut" 8191 "Fehler" ;
VAL_ 424 SARA_CF_Accel_X_r 0 "gueltiger_Wert" 1 "nicht_belegt" 2 "nicht_belegt" 3 "temporaerer_Fehler" 4 "Init" 5 "Sensor_nicht_verbaut_Signal_nicht_berrechnet" 6 "Sensor_nicht_abgeglichen" 7 "Sensor_defekt" ;
VAL_ 424 SARA_CF_Accel_Y_r 0 "gueltiger_Wert" 1 "nicht_belegt" 2 "nicht_belegt" 3 "temporaerer_Fehler" 4 "Init" 5 "Sensor_nicht_verbaut_Signal_nicht_berrechnet" 6 "Sensor_nicht_abgeglichen" 7 "Sensor_defekt" ;
VAL_ 424 SARA_CF_Omega_Z_r 0 "gueltiger_Wert" 1 "nicht_belegt" 2 "nicht_belegt" 3 "temporaerer_Fehler" 4 "Init" 5 "Sensor_nicht_verbaut_Signal_nicht_berrechnet" 6 "Sensor_nicht_abgeglichen" 7 "Sensor_defekt" ;
VAL_ 1011 SCR_Sent_Levelsignal_Status 0 "kein_Wert_ermittelbar" 1 "Aggregatszustand_Mischphase" 2 "Aggregatszustand_Eis" 3 "Aggregatszustand_Fluessig" 6 "Fehler" 7 "Init" ;
VAL_ 1011 SCR_QBit_Level_Aktivtank_02 0 "gueltiger_Wert" 1 "Ersatz_Init_oder_Fehlerwert" ;
VAL_ 1011 SCR_Level_ReadAbove 0 "Readabove aus" 1 "Readabove aktiv" ;
VAL_ 1011 SCR_Dosierpumpe_Drehzahl 2046 "Init" 2047 "Fehler" ;
VAL_ 1011 SCR_Druck 1021 "nicht_verbaut" 1022 "Init" 1023 "Fehler" ;
VAL_ 1011 SCR_Level_Aktivtank 1021 "nicht_verbaut" 1022 "Init" 1023 "Fehler" ;
VAL_ 1011 SCR_Sent_Level_Aktivtank 1022 "Init" ;
VAL_ 1507 SCR_Heizkreis_3_Strom 253 "nicht_verbaut" 254 "Init" 255 "Fehler" ;
VAL_ 1507 SCR_Guetesensor 1021 "nicht_verbaut" 1022 "Init" 1023 "Fehler" ;
VAL_ 1507 SCR_Temp_Aktivtank 254 "Init" 255 "Fehler" ;
VAL_ 1507 SCR_Temp_Passivtank 253 "nicht_verbaut" 254 "Init" 255 "Fehler" ;
VAL_ 1507 SCR_Leitungsheizung_Strom 254 "Init" 255 "Fehler" ;
VAL_ 1507 SCR_Transferpumpe_Strom 253 "nicht_verbaut" 254 "Init" 255 "Fehler" ;
VAL_ 1507 SCR_Tankheizung_Strom 254 "Init" 255 "Fehler" ;
VAL_ 1508 SCR_Spannungsversorgung_Status 0 "kein_Fehler" 1 "KS-" 2 "KS+" 3 "OC" 4 "OOR+(Ueberspannung)" 5 "OOR-(Unterspannung)" 6 "RC+" 7 "RC-" 8 "KS+/OC" 9 "KS-/OC" 10 "KS-/KS+" 11 "KS-/KS+/OC" 12 "OOR+(FktEinschr_Ueberspg)" 13 "OOR-(FktEinschr_Unterspg)" 14 "frei" 15 "Diagnose_noch_nicht_beendet" ;
VAL_ 1508 SCR_VersorgungSensoren_Status_02 0 "kein_Fehler" 1 "KS-" 2 "KS+" 3 "OC" 4 "OOR+" 5 "OOR-" 6 "RC+" 7 "RC-" 10 "KS_Sensormasse" 11 "KS_Heizkreis_1" 12 "KS_Heizkreis_2" 13 "KS_Heizkreis_3" 14 "KS_Dosierpumpe" 15 "Diagnose_noch_nicht_beendet" ;
VAL_ 1508 SCR_Heizkreis_3_Status 0 "kein Fehler / Init / nicht verbaut" 1 "KS- (Kurzschluss nach minus)" 2 "KS+ (Kurzschluss nach plus)" 3 "OC (Leitungsunterbrechung)" 4 "OOR+ (Signal zu gross)" 5 "OOR- (Signal zu klein)" 6 "RC+ (Signal unplausibel zu gross)" 7 "RC- (Signal unplausibel zu klein)" 8 "KS+/OC (Kurzschluss nach plus/Unterbrechung)" 9 "KS-/OC  (Kurzschluss nach minus/Unterbrechung)" 10 "KS-/KS+  (Kurzschluss nach minus/plus)" 11 "KS-/KS+/OC (Kurzschluss nach minus/plus/Unterbrechung)" 12 "KS_Heizer" 13 "KS_Pumpe" 14 "frei" 15 "Diagnose_noch_nicht_beendet" ;
VAL_ 1508 SCR_Sensorversorgung_12V_Status 0 "kein_Fehler" 1 "KS-" 2 "KS+" 3 "OC" 4 "OOR+" 5 "OOR-" 6 "RC+" 7 "RC-" 10 "KS_Sensormasse" 15 "Diagnose_noch_nicht_beendet" ;
VAL_ 1508 SCR_Leitungsheizung_Status 0 "kein Fehler / Init / nicht verbaut" 1 "KS- (Kurzschluss nach minus)" 2 "KS+ (Kurzschluss nach plus)" 3 "OC (Leitungsunterbrechung)" 4 "OOR+ (Signal zu gross)" 5 "OOR- (Signal zu klein)" 6 "RC+ (Signal unplausibel zu gross)" 7 "RC- (Signal unplausibel zu klein)" 8 "KS+/OC (Kurzschluss nach plus/Unterbrechung)" 9 "KS-/OC  (Kurzschluss nach minus/Unterbrechung)" 10 "KS-/KS+  (Kurzschluss nach minus/plus)" 11 "KS-/KS+/OC (Kurzschluss nach minus/plus/Unterbrechung)" 12 "KS_Heizer" 13 "KS_Pumpe" 14 "KS_Heizer_3" 15 "Diagnose_noch_nicht_beendet" ;
VAL_ 1508 SCR_Tankheizung_Status 0 "kein Fehler / Init / nicht verbaut" 1 "KS- (Kurzschluss nach minus)" 2 "KS+ (Kurzschluss nach plus)" 3 "OC (Leitungsunterbrechung)" 4 "OOR+ (Signal zu gross)" 5 "OOR- (Signal zu klein)" 6 "RC+ (Signal unplausibel zu gross)" 7 "RC- (Signal unplausibel zu klein)" 8 "KS+/OC (Kurzschluss nach plus/Unterbrechung)" 9 "KS-/OC  (Kurzschluss nach minus/Unterbrechung)" 10 "KS-/KS+  (Kurzschluss nach minus/plus)" 11 "KS-/KS+/OC (Kurzschluss nach minus/plus/Unterbrechung)" 12 "KS_Heizer" 13 "KS_Pumpe" 14 "frei" 15 "Diagnose_noch_nicht_beendet" ;
VAL_ 1508 SCR_Druck_Status_02 0 "kein_Fehler" 1 "KS_minus" 2 "KS_plus" 3 "OC_Leitungsunterbrechung" 4 "OOR_plus" 5 "OOR_minus" 6 "RC_plus" 7 "RC_minus" 8 "KS_plus_Unterbrechung" 9 "KS_minus_OC_Opencircut" 11 "KS_Heizkreis_1" 12 "KS_Heizkreis_2" 13 "KS_Heizkreis_3" 14 "KS_Dosierpumpe" 15 "Diagnose_noch_nicht_beendet" ;
VAL_ 1508 SCR_Dosierpumpe_Status_Spule 0 "kein_Fehler" 1 "KS-" 2 "KS+" 3 "OC" 4 "OOR+" 5 "OOR-" 6 "RC+(Drehzahl_zu_hoch)" 7 "RC-(Drehzahl_zu_niedrig)" 8 "KS+/OC" 9 "KS-/OC" 10 "KS-/KS+" 11 "KS_Leitungsheizer" 12 "KS_zwischen_Phasen" 13 "KS_Heizer" 14 "KS_Heizer_3" 15 "Diagnose_noch_nicht_beendet" ;
VAL_ 1508 SCR_Transferpumpe_Status 0 "kein Fehler / Init / nicht verbaut" 1 "KS- (Kurzschluss nach minus)" 2 "KS+ (Kurzschluss nach plus)" 3 "OC (Leitungsunterbrechung)" 4 "OOR+ (Signal zu gross)" 5 "OOR- (Signal zu klein)" 6 "RC+ (Signal unplausibel zu gross)" 7 "RC- (Signal unplausibel zu klein)" 8 "KS+/OC (Kurzschluss nach plus/Unterbrechung)" 9 "KS-/OC  (Kurzschluss nach minus/Unterbrechung)" 10 "KS-/KS+  (Kurzschluss nach minus/plus)" 11 "KS-/KS+/OC (Kurzschluss nach minus/plus/Unterbrechung)" 12 "KS_Heizer" 13 "KS_Pumpe" 14 "KS_Heizer_3" 15 "Diagnose_noch_nicht_beendet" ;
VAL_ 1508 SCR_Level_Aktivtank_Status 0 "kein Fehler / Init / nicht verbaut" 1 "KS- (Kurzschluss nach minus)" 2 "KS+ (Kurzschluss nach plus)" 3 "OC (Leitungsunterbrechung)" 4 "OOR+ (Signal zu gross)" 5 "OOR- (Signal zu klein)" 6 "RC+ (Signal unplausibel zu gross)" 7 "RC- (Signal unplausibel zu klein)" 8 "KS+/OC (Kurzschluss nach plus/Unterbrechung)" 9 "KS-/OC  (Kurzschluss nach minus/Unterbrechung)" 10 "KS-/KS+  (Kurzschluss nach minus/plus)" 11 "KS-/KS+/OC (Kurzschluss nach minus/plus/Unterbrechung)" 12 "KS_Heizer" 13 "KS_Pumpe" 14 "frei" 15 "Diagnose_noch_nicht_beendet" ;
VAL_ 1508 SCR_Level_Passivtank_Status 0 "kein Fehler / Init / nicht verbaut" 1 "KS- (Kurzschluss nach minus)" 2 "KS+ (Kurzschluss nach plus)" 3 "OC (Leitungsunterbrechung)" 4 "OOR+ (Signal zu gross)" 5 "OOR- (Signal zu klein)" 6 "RC+ (Signal unplausibel zu gross)" 7 "RC- (Signal unplausibel zu klein)" 8 "KS+/OC (Kurzschluss nach plus/Unterbrechung)" 9 "KS-/OC  (Kurzschluss nach minus/Unterbrechung)" 10 "KS-/KS+  (Kurzschluss nach minus/plus)" 11 "KS-/KS+/OC (Kurzschluss nach minus/plus/Unterbrechung)" 12 "KS_Heizer" 13 "KS_Pumpe" 14 "frei" 15 "Diagnose_noch_nicht_beendet" ;
VAL_ 1508 SCR_Temp_Aktivtank_Status_02 0 "kein Fehler / Init / nicht verbaut" 1 "KS- (Kurzschluss nach minus)" 2 "KS+ (Kurzschluss nach plus)" 3 "OC (Leitungsunterbrechung)" 4 "OOR+ (Signal zu gross)" 5 "OOR- (Signal zu klein)" 6 "RC+ (Signal unplausibel zu gross)" 7 "RC- (Signal unplausibel zu klein)" 8 "KS-/OC (Kurzschluss nach Masse/ Leitungsunterbrechung)" 11 "KS_Heizkreis_1" 12 "KS_Heizkreis_2" 13 "KS_Heizkreis_3" 14 "KS_Dosierpumpe" 15 "Diagnose_noch_nicht_beendet" ;
VAL_ 1508 SCR_Temp_Passivtank_Status 0 "kein Fehler / Init / nicht verbaut" 1 "KS- (Kurzschluss nach minus)" 2 "KS+ (Kurzschluss nach plus)" 3 "OC (Leitungsunterbrechung)" 4 "OOR+ (Signal zu gross)" 5 "OOR- (Signal zu klein)" 6 "RC+ (Signal unplausibel zu gross)" 7 "RC- (Signal unplausibel zu klein)" 8 "KS+/OC (Kurzschluss nach plus/Unterbrechung)" 9 "KS-/OC  (Kurzschluss nach minus/Unterbrechung)" 10 "KS-/KS+  (Kurzschluss nach minus/plus)" 11 "KS-/KS+/OC (Kurzschluss nach minus/plus/Unterbrechung)" 12 "KS_Heizer" 13 "KS_Pumpe" 14 "frei" 15 "Diagnose_noch_nicht_beendet" ;
VAL_ 1509 SCR_Ansteuerung_Transferpumpe 0 "nicht_aktiv" 1 "aktiv" ;
VAL_ 1509 SCR_Ansteuerung_Dosierpumpe 0 "nicht_aktiv" 1 "aktiv" ;
VAL_ 1509 SCR_Ansteuerung_Heizkreis_3 0 "nicht_aktiv" 1 "aktiv" ;
VAL_ 1509 SCR_Ansteuerung_Leitungsheizung 0 "nicht_aktiv" 1 "aktiv" ;
VAL_ 1509 SCR_Ansteuerung_Tankheizung 0 "nicht_aktiv" 1 "aktiv" ;
VAL_ 1509 SCR_Steuergeraet_PMode 0 "PMode_nicht_aktiv" 1 "PMode_aktiv" ;
VAL_ 1526 SCR_Level_Aktivtank_OOR4Quality 0 "Füllstand i.O. für Qualitätsberechnung" 1 "Füllstand zu niedrig für Qualitätsberechnung" ;
VAL_ 1526 SCR_Level_Aktivtank_OOR_minus 0 "Level erfassbar" 1 "Level zu niedrig" ;
VAL_ 1526 SCR_Sent_1_Signalstatus 0 "kein Fehler" 1 "Sent Signal unplausibel" 2 "Sent Signal TimeOut" 3 "Diagnose noch nicht beendet" ;
VAL_ 1526 SCR_Sent_1_elektrischer_Status 0 "kein Fehler" 1 "KS- " 2 "KS+" 8 "KS_Versorgung_Sensoren" 11 "KS_Heizkreis_1" 12 "KS_Heizkreis_2" 13 "KS_Heizkreis_3" 14 "KS_Pumpe" 15 "Diagnose noch nicht beendet" ;
VAL_ 1526 SCR_Sent_Levelsensor 0 "kein Fehler" 1 "Levelsensor defekt" 2 "Sensortemperatur zu hoch" 3 "Sensorversorgung OOR" 5 "Levelsignal OOR+" 6 "Levelsignal OOR-" 7 "Diagnose noch nicht beendet" ;
VAL_ 1526 SCR_Sent_Qualitaetssensor 0 "kein Fehler" 1 "Qualitätssensor defekt" 2 "Fremdlicht" 3 "Sensorstoerung" 5 "OOR+" 6 "OOR-" 7 "Diagnose noch nicht beendet" ;
VAL_ 1526 SCR_Sent_Temperatursensor 0 "kein Fehler" 1 "Temperatursensor defekt" 5 "OOR+" 6 "OOR-" 7 "Diagnose noch nicht beendet" ;
VAL_ 1526 SCR_DEF_Qualitaet_Medium 0 "Mediumkonzentration ermittelbar" 1 "Mediumkonzentration nicht ermittelbar" ;
VAL_ 1526 SCR_QBit_Qualitaet 0 "gueltiger_Wert" 1 "Ersatz_Init_oder_Fehlerwert" ;
VAL_ 1526 SCR_Sent_2_Signalstatus 0 "kein_Fehler" 1 "Sent_Signal_unplausibel" 2 "Sent_Signal_TimeOut" 3 "Diagnose_noch_nicht_beendet" ;
VAL_ 1526 SCR_Temp_DEF2_Sensor_Status 0 "kein_Fehler" 1 "Temperatursensor_defekt" 5 "OOR+" 6 "OOR-" 7 "Diagnose_noch_nicht_beendet" ;
VAL_ 1526 SCR_Sent_2_elektrischer_Status 0 "kein_Fehler" 1 "KS- " 2 "KS+" 8 "KS_Versorgung_Sensoren" 11 "KS_Heizkreis_1" 12 "KS_Heizkreis_2" 13 "KS_Heizkreis_3" 14 "KS_Pumpe" 15 "Diagnose_noch_nicht_beendet" ;
VAL_ 1526 SCR_HAL_Sensorik_Status 0 "kein_Fehler" 1 "KS-" 2 "KS+" 3 "OC" 4 "OOR+" 5 "OOR-" 6 "RC+" 7 "RC-" 8 "KSplus_Unterbrechung" 9 "KSminus_Unterbrechung" 15 "Diagnose_noch_nicht_beendet" ;
VAL_ 1526 SCR_Steuergeraet_Heizung_Status 0 "kein_Fehler" 1 "Endstufe_Tankheizung_ueberhitzt" 2 "Endstufe_Leitungsheizung_ueberhitzt" 3 "Diagnose_noch_nicht_beendet" ;
VAL_ 1526 SCR_Steuergeraet_Pumpe_Status 0 "kein_Fehler" 1 "Endstufe_Pumpe_ueberhitzt" 2 "Pumpe_blockiert" 3 "Diagnose_noch_nicht_beendet" ;
VAL_ 1526 SCR_Steuergeraet_Relais_Status 0 "kein_Fehler" 1 "KS+ (Ausgang Leistungsrelais) " 2 "KS-/OC (Ausgang Leistungsrelais)" 3 "Diagnose_noch_nicht_beendet" ;
VAL_ 1526 SCR_Steuergeraet_Bus_Status 0 "kein_Fehler" 1 "Bus_Kommunikation_Fehler" 2 "Bus_Kommunikation_Stoerung_(temporaer)" 3 "Diagnose_noch_nicht_beendet" ;
VAL_ 1526 SCR_ECU_Datensatz_Status 0 "kein_Fehler" 1 "ungueltiger_Datensatz" 2 "unplausibeler_Datensatz" 3 "Diagnose_noch_nicht_beendet" ;
VAL_ 1526 SCR_Steuergeraet_Defekt_Status 0 "kein_Fehler" 1 "Steuergeraet_defekt" 2 "Steuergeraet_Stoerung_(temporaer)" 3 "Diagnose_noch_nicht_beendet" ;
VAL_ 2527679503 SCR_DEF_CAL_CVN_CRC_32 0 "Init" ;
VAL_ 2527679503 SCR_Temp_DEF_Hinweis 0 "kein Hinweis" 1 "SCR_DEF_Temp_high " 2 "SCR_DEF_Temp_low" 3 "Hinweis noch nicht verfügbar" ;
VAL_ 2527679503 SCR_Level_Aktivtank_saturated 0 "maximaler erfassbarer Füllstand nicht erreicht" 1 "maximalerer erfassbarer Füllstand erreicht" ;
VAL_ 2527679503 SCR_QBit_Qualitaet_Aktivtank 0 "gueltiger_Wert" 1 "Ersatz_Init_oder_Fehlerwert" ;
VAL_ 2527679503 SCR_QBit_Temp_DEF_Sensor_02 0 "gueltiger_Wert" 1 "Ersatz_Init_oder_Fehlerwert" ;
VAL_ 2527679503 SCR_Sent_Qualitaet_Aktivtank 253 "Sensor nicht verbaut" 254 "Init" ;
VAL_ 2527679503 SCR_Temperatur_DEF_Sensor 254 "Init" ;
VAL_ 2589283459 SCR_Tankheizung_P_effektiv 254 "Initwert" ;
VAL_ 2589283459 SCR_Tankheizkreis_P_Grenze 254 "Init" ;
VAL_ 2589283459 SCR_Heizkreis_3_P_effektiv 254 "Init" ;
VAL_ 2589283459 SCR_Heizkreis_3_P_Grenze 254 "Init" ;
VAL_ 2589283460 SCR_QBit_Temp_DEF2_Sensor 0 "gueltiger_Wert" 1 "Ersatz_Init_oder_Fehlerwert" ;
VAL_ 2589283460 SCR_Temp_DEF2_Sensor 254 "Init" ;
VAL_ 2589283460 SCR_DEF2_CAL_CVN_CRC_32 0 "Init" ;
VAL_ 2463978593 SCR_QBit_Level_kurz_Aktivtank 0 "gueltiger_Wert" 1 "Ersatz_Init_oder_Fehlerwert" ;
VAL_ 2463978593 SCR_Sent_Level_kurz_Aktivtank 1022 "Init" ;
VAL_ 2463978593 SCR_Dosierpumpe_Umdrehungen 254 "Init" 255 "Fehler" ;
VAL_ 2589283497 SCR_DEF2_CAL_ID_Index01 1145390640 "Init" ;
VAL_ 2589283497 SCR_DEF2_CAL_ID_Index02 808464432 "Init" ;
VAL_ 2589283498 SCR_DEF2_CAL_ID_Index03 808464432 "Init" ;
VAL_ 2589283498 SCR_DEF2_CAL_ID_Index04 808464432 "Init" ;
VAL_ 2589283413 SCR_DEF_CAL_ID_Index01 1145390640 "Init" ;
VAL_ 2589283413 SCR_DEF_CAL_ID_Index02 808464432 "Init" ;
VAL_ 2589283414 SCR_DEF_CAL_ID_Index03 808464432 "Init" ;
VAL_ 2589283414 SCR_DEF_CAL_ID_Index04 808464432 "Init" ;
VAL_ 980 BH_Blinker_li 0 "nicht_betaetigt" 1 "Blinkerhebel_Richtung_links_betaetigt" ;
VAL_ 980 BH_Blinker_re 0 "nicht_betaetigt" 1 "Blinkerhebel_Richtung_rechts_betaetigt" ;
VAL_ 980 BH_Lichthupe 0 "nicht_betaetigt" 1 "Blinkerhebel in Richtung Lichthupe betaetigt" ;
VAL_ 980 BH_Fernlicht 0 "nicht_betaetigt" 1 "Blinkerhebel_in_Richtung_Fernlicht_betaetigt" ;
VAL_ 980 WH_Tipwischen 0 "nicht_betaetigt" 1 "betaetigt" ;
VAL_ 980 WH_Intervall 0 "aus" 1 "Wischerhebel in Stellung Intervall" ;
VAL_ 980 WH_WischerStufe1 0 "aus" 1 "Wischerhebel in Stufe Wischen 1" ;
VAL_ 980 WH_WischerStufe2 0 "aus" 1 "Wischerhebel in Stufe Wischen 2" ;
VAL_ 980 WH_Frontwaschen 0 "aus" 1 "Wischerhebel in Stellung Wisch Wasch vorne" ;
VAL_ 980 WH_Heckintervall 0 "nicht_betaetigt" 1 "Wischerhebel in Stellung Heckintervall" ;
VAL_ 980 WH_Heckwaschen 0 "nicht_betaetigt" 1 "Wischerhebel in Stellung Wisch Wasch hinten" ;
VAL_ 980 WH_Intervallstufen 0 "Init / Default" 1 "Intervallstufe 1" 5 "Intervallstufe 2" 9 "Intervallstufe 3" 13 "Intervallstufe 4" 15 "Fehler" ;
VAL_ 980 FAS_Taster 0 "nicht_betaetigt" 1 "betaetigt" ;
VAL_ 980 FAS_Taster_Fehler 0 "kein_Fehler" 1 "Fehler" ;
VAL_ 980 SMLS_Hupe 0 "nicht_betaetigt" 1 "Hupe_gedrueckt" ;
VAL_ 980 LRH_on_off 0 "LRH_aus__keine Anzeige" 1 "LRH_aus" 2 "LRH_ein" 3 "Fehler" ;
VAL_ 980 LRH_aktiv 0 "inaktiv" 1 "aktiv" ;
VAL_ 980 SMLS_P_verriegelt_plausibel 0 "unplausibel" 1 "plausibel" ;
VAL_ 980 WH_SRA 0 "SRA_Aus" 1 "SRA_Ein" ;
VAL_ 980 WH_Wischer_Fehler 0 "kein_Fehler" 1 "Fehler" ;
VAL_ 980 BH_Blinker_Fehler 0 "kein_Fehler" 1 "Fehler" ;
VAL_ 980 SMLS_PTT 0 "nicht_betaetigt" 1 "PTT_gedrueckt" ;
VAL_ 980 WH_Tipwischen_lang 0 "nicht_betaetigt" 1 "betaetigt" ;
VAL_ 1710 SP_FT_oben 0 "nicht_betaetigt" 1 "betaetigt" ;
VAL_ 1710 SP_FT_unten 0 "nicht_betaetigt" 1 "betaetigt" ;
VAL_ 1710 SP_FT_links 0 "nicht_betaetigt" 1 "betaetigt" ;
VAL_ 1710 SP_FT_rechts 0 "nicht_betaetigt" 1 "betaetigt" ;
VAL_ 1710 SP_BT_oben 0 "nicht_betaetigt" 1 "betaetigt" ;
VAL_ 1710 SP_BT_unten 0 "nicht_betaetigt" 1 "betaetigt" ;
VAL_ 1710 SP_BT_links 0 "nicht_betaetigt" 1 "betaetigt" ;
VAL_ 1710 SP_BT_rechts 0 "nicht_betaetigt" 1 "betaetigt" ;
VAL_ 1710 SP_abklappen 0 "Spiegel_abklappen_nicht_aktiv" 1 "Spiegel_abklappen_aktiv" ;
VAL_ 1710 SP_anklappen 0 "Spiegle_anklappen_nicht_aktiv" 1 "Spiegel_anklappen_aktiv" ;
VAL_ 1710 SP_normieren 0 "Spiegel_nicht_normiert" 1 "Spiegel_normiert" ;
VAL_ 1710 SP_Hzg_Taster 0 "nicht_betaetigt" 1 "betaetigt" ;
VAL_ 1710 SP_S_oben 1 "Spiegelschalter in Stellung oben" ;
VAL_ 1710 SP_S_unten 1 "Spiegelschalter in Stellung unten" ;
VAL_ 1710 SP_S_links 1 "Spiegelschalter in Stellung links" ;
VAL_ 1710 SP_S_rechts 1 "Spiegelschalter in Stellung rechts" ;
VAL_ 1710 SP_Auswahl_li 1 "Spiegelschalter in Stellung Auswahl links" ;
VAL_ 1710 SP_Auswahl_re 1 "Spiegelschalter in Stellung Auswahl rechts" ;
VAL_ 1710 SP_ARA_Status 0 "TSG nicht im ARA-Modus" 1 "TSG im ARA-Modus" ;
VAL_ 1710 SP_S_Klappen 1 "Spiegelschalter in Stellung Klappen" ;
VAL_ 1710 SP_Verstellschalter_Fehler 0 "kein_Fehler" 1 "Fehler" ;
VAL_ 1313 STH_Funk_ein 0 "kein Funkbefehl zum Einschalten" 1 "Funkbefehl zum Einschalten erhalten" ;
VAL_ 1313 STH_Funk_aus 0 "kein Funkbefehl" 1 "Funkbefehl zum Ausschalten erhalten" ;
VAL_ 1313 STH_Zusatzheizung 0 "Zuheizer aus" 1 "Zuheizer ein" ;
VAL_ 1313 STH_LED 0 "keine Rückmeldung" 1 "Rueckmeldung Standheizung in Betrieb" ;
VAL_ 1313 STH_Geblaese 0 "kein Einschaltbefehl an die Klimaanlage, Gebläse" 1 "Einschaltbefehl an die Klimaanlage, Gebläse" ;
VAL_ 1313 STH_EKP_Anst 0 "EKP nicht ansteuern" 1 "EKP ansteuern" ;
VAL_ 1313 STH_Start_folgt 0 "kein_Start_folgt" 1 "Start_folgt" ;
VAL_ 1313 STH_Ventil_Status 0 "Ventil_offen__grosser_Kreislauf" 1 "Ventil_geschlossen__kleiner_Kreislauf" ;
VAL_ 1313 STH_Fehler_ElWaPu 0 "kein_Fehler" 1 "Fehler" ;
VAL_ 1313 STH_Pumpen_Anf_extern 0 "nicht_angefordert" 1 "angefordert" ;
VAL_ 1313 STH_KL_HUP 0 "Aus" 1 "Ein" ;
VAL_ 1313 STH_Fehlerstatus 0 "kein_Fehler" 1 "Unterspannung" 2 "Tankfuellstand_zu_gering" 3 "Fehler_Betrieb_verhindert" 4 "Heizgeraet_verriegelt" 5 "Fehler_Betrieb_nicht_verhindert" 6 "Emissionsüberschreitung" ;
VAL_ 1313 STH_Wassertemp 254 "Init" 255 "Fehler" ;
VAL_ 1313 STH_Texte 0 "keine_Anzeige" 1 "Batteriemanagementeinschraenkung" 2 "Kraftstoffmangel" 3 "interner_Systemfehler" 4 "Heizzeitueberschreitung" ;
VAL_ 1313 STH_Motorvorwaermung 0 "keine Motorvorwärmung erfolgt" 1 "Aufheizung mit Motorvorwärmung erfolgt" ;
VAL_ 1313 STH_war_aktiv 0 "war inaktiv" 1 "Standheizung war letzte halbe Stunde aktiv" ;
VAL_ 1313 STH_KVS_Ueberlauf 0 "kein Überlauf" 1 "Kraftstoffverbrauchssignal, mindestens ein Überlauf hat stattgefunden" ;
VAL_ 1313 STH_SH_ZH 0 "Heizgeraet_WZH" 1 "Heizgeraet_ZH" ;
